VERSION ""

NS_ :

BS_:

BU_: FICM_FD Vector__XXX

BO_ 741 DTE_FuelCnsmp: 8 Vector__XXX
 SG_ RemainDrvngDist : 7|12@0+ (1,0) [0|4095] ""  FICM_FD

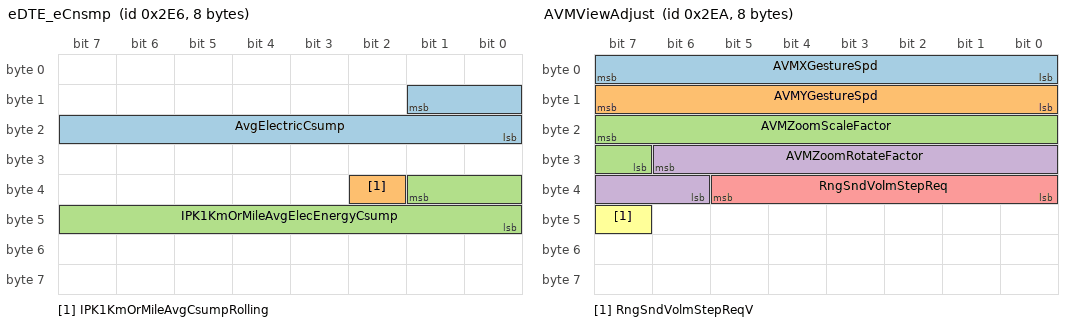
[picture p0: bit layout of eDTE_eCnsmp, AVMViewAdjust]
BO_ 742 eDTE_eCnsmp: 8 Vector__XXX
 SG_ AvgElectricCsump : 9|10@0+ (0.1,0) [0|99.9] "kWh/100km或者kWh/100mi"  FICM_FD
 SG_ IPK1KmOrMileAvgCsumpRolling : 34|1@0+ (1,0) [0|1] ""  FICM_FD
 SG_ IPK1KmOrMileAvgElecEnergyCsump : 33|10@0+ (0.1,-30) [-30|69.9] "kWh/100km或者kWh/100mi"  FICM_FD

BO_ 746 AVMViewAdjust: 8 FICM_FD
 SG_ AVMXGestureSpd : 7|8@0+ (1,0) [0|254] ""  Vector__XXX
 SG_ AVMYGestureSpd : 15|8@0+ (1,0) [0|254] ""  Vector__XXX
 SG_ AVMZoomScaleFactor : 23|9@0+ (1,0) [0|510] ""  Vector__XXX
 SG_ AVMZoomRotateFactor : 30|9@0+ (1,0) [0|510] ""  Vector__XXX
 SG_ RngSndVolmStepReq : 37|6@0+ (1,0) [0|63] ""  Vector__XXX
 SG_ RngSndVolmStepReqV : 47|1@0+ (1,0) [0|1] ""  Vector__XXX

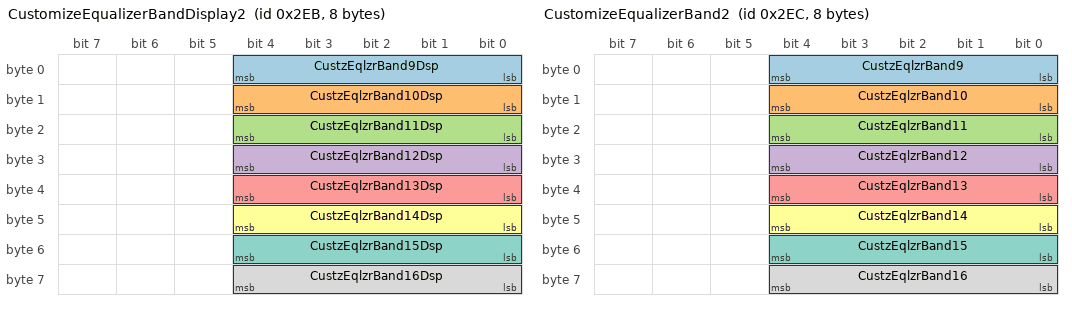
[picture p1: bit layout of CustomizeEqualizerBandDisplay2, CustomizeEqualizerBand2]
BO_ 747 CustomizeEqualizerBandDisplay2: 8 Vector__XXX
 SG_ CustzEqlzrBand9Dsp : 4|5@0+ (1,0) [0|31] ""  FICM_FD
 SG_ CustzEqlzrBand10Dsp : 12|5@0+ (1,0) [0|31] ""  FICM_FD
 SG_ CustzEqlzrBand11Dsp : 20|5@0+ (1,0) [0|31] ""  FICM_FD
 SG_ CustzEqlzrBand12Dsp : 28|5@0+ (1,0) [0|31] ""  FICM_FD
 SG_ CustzEqlzrBand13Dsp : 36|5@0+ (1,0) [0|31] ""  FICM_FD
 SG_ CustzEqlzrBand14Dsp : 44|5@0+ (1,0) [0|31] ""  FICM_FD
 SG_ CustzEqlzrBand15Dsp : 52|5@0+ (1,0) [0|31] ""  FICM_FD
 SG_ CustzEqlzrBand16Dsp : 60|5@0+ (1,0) [0|31] ""  FICM_FD

BO_ 748 CustomizeEqualizerBand2: 8 FICM_FD
 SG_ CustzEqlzrBand9 : 4|5@0+ (1,0) [0|31] "/"  Vector__XXX
 SG_ CustzEqlzrBand10 : 12|5@0+ (1,0) [0|31] "/"  Vector__XXX
 SG_ CustzEqlzrBand11 : 20|5@0+ (1,0) [0|31] "/"  Vector__XXX
 SG_ CustzEqlzrBand12 : 28|5@0+ (1,0) [0|31] "/"  Vector__XXX
 SG_ CustzEqlzrBand13 : 36|5@0+ (1,0) [0|31] "/"  Vector__XXX
 SG_ CustzEqlzrBand14 : 44|5@0+ (1,0) [0|31] "/"  Vector__XXX
 SG_ CustzEqlzrBand15 : 52|5@0+ (1,0) [0|31] "/"  Vector__XXX
 SG_ CustzEqlzrBand16 : 60|5@0+ (1,0) [0|31] "/"  Vector__XXX

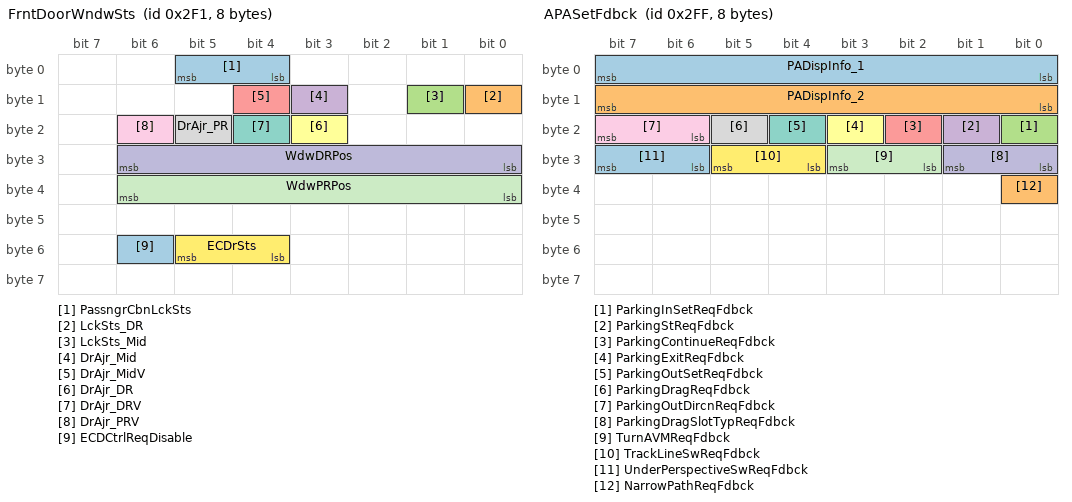
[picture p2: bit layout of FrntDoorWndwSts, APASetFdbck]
BO_ 753 FrntDoorWndwSts: 8 Vector__XXX
 SG_ PassngrCbnLckSts : 5|2@0+ (1,0) [0|3] ""  FICM_FD
 SG_ LckSts_DR : 8|1@0+ (1,0) [0|1] ""  FICM_FD
 SG_ LckSts_Mid : 9|1@0+ (1,0) [0|1] ""  FICM_FD
 SG_ DrAjr_Mid : 11|1@0+ (1,0) [0|1] ""  FICM_FD
 SG_ DrAjr_MidV : 12|1@0+ (1,0) [0|1] ""  FICM_FD
 SG_ DrAjr_DR : 19|1@0+ (1,0) [0|1] ""  FICM_FD
 SG_ DrAjr_DRV : 20|1@0+ (1,0) [0|1] ""  FICM_FD
 SG_ DrAjr_PR : 21|1@0+ (1,0) [0|1] ""  FICM_FD
 SG_ DrAjr_PRV : 22|1@0+ (1,0) [0|1] ""  FICM_FD
 SG_ WdwDRPos : 30|7@0+ (1,0) [0|127] "%"  FICM_FD
 SG_ WdwPRPos : 38|7@0+ (1,0) [0|127] "%"  FICM_FD
 SG_ ECDrSts : 53|2@0+ (1,0) [0|3] ""  FICM_FD
 SG_ ECDCtrlReqDisable : 54|1@0+ (1,0) [0|1] ""  FICM_FD

BO_ 754 RearDoorWndwSts: 8 Vector__XXX
 SG_ DrAjr_RL : 8|1@0+ (1,0) [0|1] ""  FICM_FD
 SG_ DrAjr_RLV : 9|1@0+ (1,0) [0|1] ""  FICM_FD
 SG_ DrAjr_RR : 10|1@0+ (1,0) [0|1] ""  FICM_FD
 SG_ DrAjr_RRV : 11|1@0+ (1,0) [0|1] ""  FICM_FD
 SG_ WdwRLPos : 22|7@0+ (1,0) [0|127] "%"  FICM_FD
 SG_ WdwRRPos : 30|7@0+ (1,0) [0|127] "%"  FICM_FD
 SG_ PwrPdlModuSts_RL : 36|3@0+ (1,0) [0|7] ""  FICM_FD
 SG_ PwrPdlModuSts_RR : 39|3@0+ (1,0) [0|7] ""  FICM_FD
 SG_ HVFuelSts : 41|2@0+ (1,0) [0|2] ""  FICM_FD
 SG_ Ajr_HVFulBxV : 42|1@0+ (1,0) [0|1] ""  FICM_FD
 SG_ Ajr_HVFulBx : 44|2@0+ (1,0) [0|2] ""  FICM_FD
 SG_ ChldLckSts_RR : 45|1@0+ (1,0) [0|1] ""  FICM_FD
 SG_ ChldLckSts_RL : 46|1@0+ (1,0) [0|1] ""  FICM_FD
 SG_ FuelSysEPTRdyOvrdInvsn : 54|1@0+ (1,0) [0|1] ""  FICM_FD
 SG_ FuelSysEPTRdyOvrd : 55|1@0+ (1,0) [0|1] ""  FICM_FD
 SG_ DrAjr_CRP : 57|1@0+ (1,0) [0|1] ""  FICM_FD
 SG_ DrAjr_CRPV : 58|1@0+ (1,0) [0|1] ""  FICM_FD
 SG_ ECDErrResp : 60|2@0+ (1,0) [0|3] ""  FICM_FD

BO_ 767 APASetFdbck: 8 Vector__XXX
 SG_ PADispInfo_1 : 7|8@0+ (1,0) [0|255] ""  FICM_FD
 SG_ PADispInfo_2 : 15|8@0+ (1,0) [0|255] ""  FICM_FD
 SG_ ParkingInSetReqFdbck : 16|1@0+ (1,0) [0|1] ""  FICM_FD
 SG_ ParkingStReqFdbck : 17|1@0+ (1,0) [0|1] ""  FICM_FD
 SG_ ParkingContinueReqFdbck : 18|1@0+ (1,0) [0|1] ""  FICM_FD
 SG_ ParkingExitReqFdbck : 19|1@0+ (1,0) [0|1] ""  FICM_FD
 SG_ ParkingOutSetReqFdbck : 20|1@0+ (1,0) [0|1] ""  FICM_FD
 SG_ ParkingDragReqFdbck : 21|1@0+ (1,0) [0|1] ""  FICM_FD
 SG_ ParkingOutDircnReqFdbck : 23|2@0+ (1,0) [0|3] ""  FICM_FD
 SG_ ParkingDragSlotTypReqFdbck : 25|2@0+ (1,0) [0|3] ""  FICM_FD
 SG_ TurnAVMReqFdbck : 27|2@0+ (1,0) [0|3] ""  FICM_FD
 SG_ TrackLineSwReqFdbck : 29|2@0+ (1,0) [0|3] ""  FICM_FD
 SG_ UnderPerspectiveSwReqFdbck : 31|2@0+ (1,0) [0|3] ""  FICM_FD
 SG_ NarrowPathReqFdbck : 32|1@0+ (1,0) [0|1] ""  FICM_FD

BO_ 769 TIMLmpSts: 8 Vector__XXX
 SG_ TrlerAttchSts : 0|1@0+ (1,0) [0|1] ""  FICM_FD

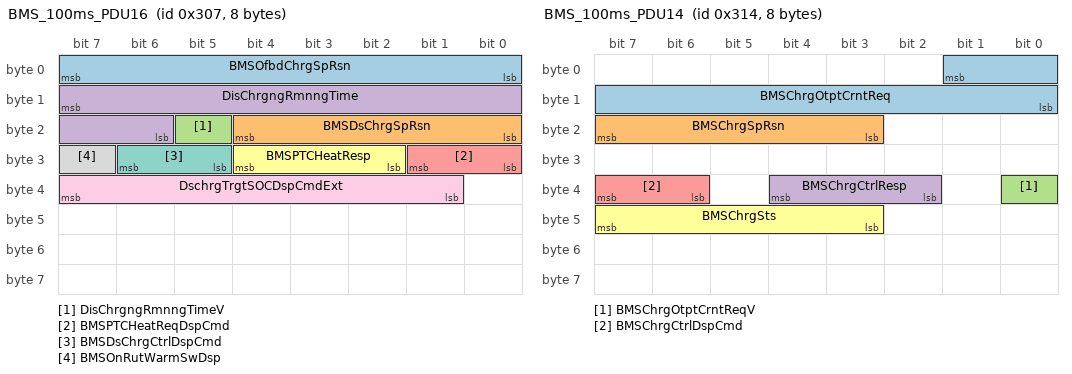
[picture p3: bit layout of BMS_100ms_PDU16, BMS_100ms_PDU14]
BO_ 775 BMS_100ms_PDU16: 8 Vector__XXX
 SG_ BMSOfbdChrgSpRsn : 7|8@0+ (1,0) [0|255] ""  FICM_FD
 SG_ BMSDsChrgSpRsn : 20|5@0+ (1,0) [0|31] ""  FICM_FD
 SG_ DisChrgngRmnngTimeV : 21|1@0+ (1,0) [0|1] ""  FICM_FD
 SG_ DisChrgngRmnngTime : 15|10@0+ (1,0) [0|1023] "min"  FICM_FD
 SG_ BMSPTCHeatReqDspCmd : 25|2@0+ (1,0) [0|3] ""  FICM_FD
 SG_ BMSPTCHeatResp : 28|3@0+ (1,0) [0|7] ""  FICM_FD
 SG_ BMSDsChrgCtrlDspCmd : 30|2@0+ (1,0) [0|3] ""  FICM_FD
 SG_ BMSOnRutWarmSwDsp : 31|1@0+ (1,0) [0|1] "NULL"  FICM_FD
 SG_ DschrgTrgtSOCDspCmdExt : 39|7@0+ (1,0) [0|100] "%"  FICM_FD

BO_ 776 AirBag_HMI: 8 Vector__XXX
 SG_ FrtPsngAirbagOnOffReqFdbck : 19|2@0+ (1,0) [0|3] ""  FICM_FD
 SG_ SBRSetReqFdbck_R : 20|1@0+ (1,0) [0|1] ""  FICM_FD

BO_ 788 BMS_100ms_PDU14: 8 Vector__XXX
 SG_ BMSChrgOtptCrntReq : 1|10@0+ (0.5,0) [0|511.5] "A"  FICM_FD
 SG_ BMSChrgSpRsn : 23|5@0+ (1,0) [0|31] "NULL"  FICM_FD
 SG_ BMSChrgOtptCrntReqV : 32|1@0+ (1,0) [0|1] "NULL"  FICM_FD
 SG_ BMSChrgCtrlResp : 36|3@0+ (1,0) [0|7] "NULL"  FICM_FD
 SG_ BMSChrgCtrlDspCmd : 39|2@0+ (1,0) [0|3] "NULL"  FICM_FD
 SG_ BMSChrgSts : 47|5@0+ (1,0) [0|31] "NULL"  FICM_FD

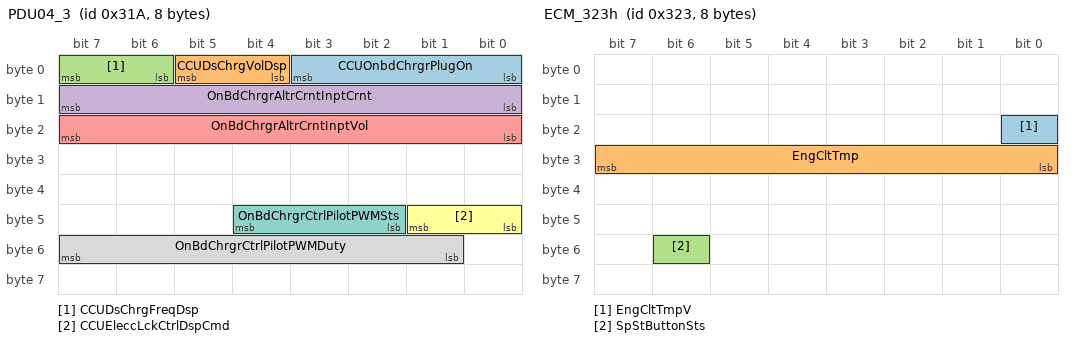
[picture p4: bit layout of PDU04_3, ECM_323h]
BO_ 794 PDU04_3: 8 Vector__XXX
 SG_ CCUOnbdChrgrPlugOn : 3|4@0+ (1,0) [0|15] "NULL"  FICM_FD
 SG_ CCUDsChrgVolDsp : 5|2@0+ (1,0) [0|3] ""  FICM_FD
 SG_ CCUDsChrgFreqDsp : 7|2@0+ (1,0) [0|3] ""  FICM_FD
 SG_ OnBdChrgrAltrCrntInptCrnt : 15|8@0+ (0.2,0) [0|51] "A"  FICM_FD
 SG_ OnBdChrgrAltrCrntInptVol : 23|8@0+ (2,0) [0|508] "V"  FICM_FD
 SG_ CCUEleccLckCtrlDspCmd : 41|2@0+ (1,0) [0|3] "NULL"  FICM_FD
 SG_ OnBdChrgrCtrlPilotPWMSts : 44|3@0+ (1,0) [0|7] ""  FICM_FD
 SG_ OnBdChrgrCtrlPilotPWMDuty : 55|7@0+ (1,0) [0|100] ""  FICM_FD

BO_ 800 SCM_DR_0x320: 8 Vector__XXX
 SG_ MemFdbk_PR : 1|2@0+ (1,0) [0|3] ""  FICM_FD
 SG_ MemClrFdbk_PR : 3|2@0+ (1,0) [0|3] ""  FICM_FD

BO_ 803 ECM_323h: 8 Vector__XXX
 SG_ EngCltTmpV : 16|1@0+ (1,0) [0|1] ""  FICM_FD
 SG_ EngCltTmp : 31|8@0+ (1,-40) [-40|215] "℃"  FICM_FD
 SG_ SpStButtonSts : 54|1@0+ (1,0) [0|1] ""  FICM_FD

BO_ 811 FOTAInfo: 8 Vector__XXX
 SG_ FOTAModReq : 1|2@0+ (1,0) [0|3] ""  FICM_FD

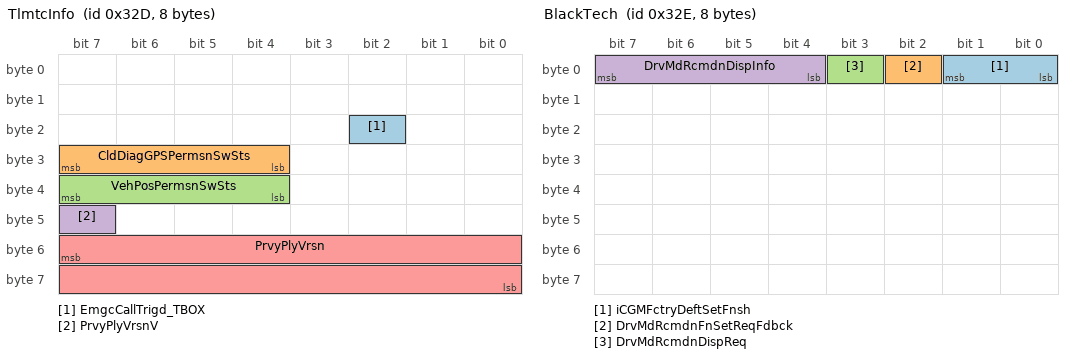
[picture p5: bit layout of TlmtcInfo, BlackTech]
BO_ 813 TlmtcInfo: 8 Vector__XXX
 SG_ EmgcCallTrigd_TBOX : 18|1@0+ (1,0) [0|1] ""  FICM_FD
 SG_ CldDiagGPSPermsnSwSts : 31|4@0+ (1,0) [0|15] ""  FICM_FD
 SG_ VehPosPermsnSwSts : 39|4@0+ (1,0) [0|15] ""  FICM_FD
 SG_ PrvyPlyVrsnV : 47|1@0+ (1,0) [0|1] ""  FICM_FD
 SG_ PrvyPlyVrsn : 55|16@0+ (1,0) [0|65535] ""  FICM_FD

BO_ 814 BlackTech: 8 Vector__XXX
 SG_ iCGMFctryDeftSetFnsh : 1|2@0+ (1,0) [0|3] ""  FICM_FD
 SG_ DrvMdRcmdnFnSetReqFdbck : 2|1@0+ (1,0) [0|1] ""  FICM_FD
 SG_ DrvMdRcmdnDispReq : 3|1@0+ (1,0) [0|1] ""  FICM_FD
 SG_ DrvMdRcmdnDispInfo : 7|4@0+ (1,0) [0|15] ""  FICM_FD

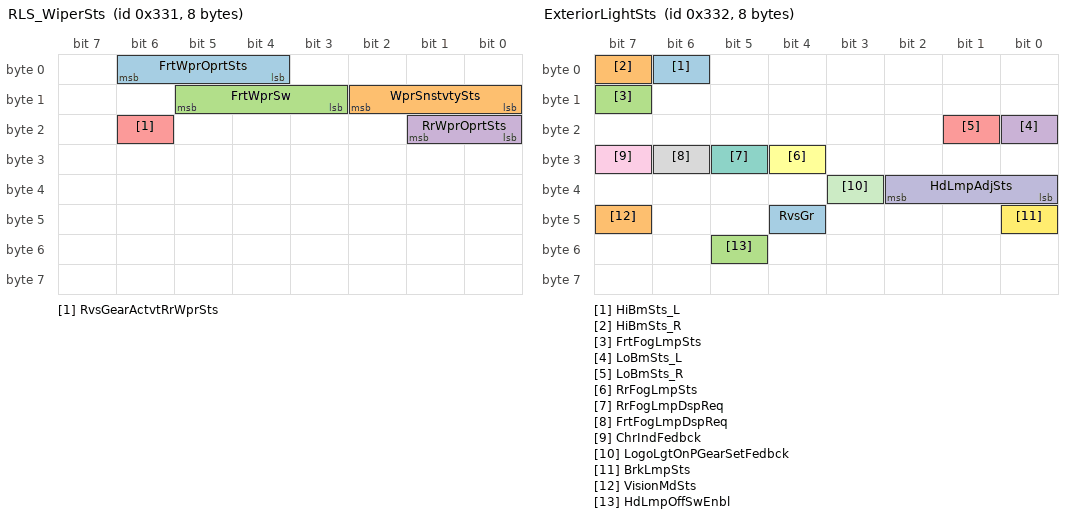
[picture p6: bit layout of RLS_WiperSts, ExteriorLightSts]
BO_ 817 RLS_WiperSts: 8 Vector__XXX
 SG_ FrtWprOprtSts : 6|3@0+ (1,0) [0|7] ""  FICM_FD
 SG_ WprSnstvtySts : 10|3@0+ (1,0) [0|4] ""  FICM_FD
 SG_ FrtWprSw : 13|3@0+ (1,0) [0|7] ""  FICM_FD
 SG_ RrWprOprtSts : 17|2@0+ (1,0) [0|3] ""  FICM_FD
 SG_ RvsGearActvtRrWprSts : 22|1@0+ (1,0) [0|1] ""  FICM_FD

BO_ 818 ExteriorLightSts: 8 Vector__XXX
 SG_ HiBmSts_L : 6|1@0+ (1,0) [0|1] ""  FICM_FD
 SG_ HiBmSts_R : 7|1@0+ (1,0) [0|1] ""  FICM_FD
 SG_ FrtFogLmpSts : 15|1@0+ (1,0) [0|1] ""  FICM_FD
 SG_ LoBmSts_L : 16|1@0+ (1,0) [0|1] ""  FICM_FD
 SG_ LoBmSts_R : 17|1@0+ (1,0) [0|1] ""  FICM_FD
 SG_ RrFogLmpSts : 28|1@0+ (1,0) [0|1] ""  FICM_FD
 SG_ RrFogLmpDspReq : 29|1@0+ (1,0) [0|1] ""  FICM_FD
 SG_ FrtFogLmpDspReq : 30|1@0+ (1,0) [0|1] ""  FICM_FD
 SG_ ChrIndFedbck : 31|1@0+ (1,0) [0|1] ""  FICM_FD
 SG_ HdLmpAdjSts : 34|3@0+ (1,0) [0|7] ""  FICM_FD
 SG_ LogoLgtOnPGearSetFedbck : 35|1@0+ (1,0) [0|1] ""  FICM_FD
 SG_ BrkLmpSts : 40|1@0+ (1,0) [0|1] ""  FICM_FD
 SG_ RvsGr : 44|1@0+ (1,0) [0|1] ""  FICM_FD
 SG_ VisionMdSts : 47|1@0+ (1,0) [0|1] ""  FICM_FD
 SG_ HdLmpOffSwEnbl : 53|1@0+ (1,0) [0|1] ""  FICM_FD

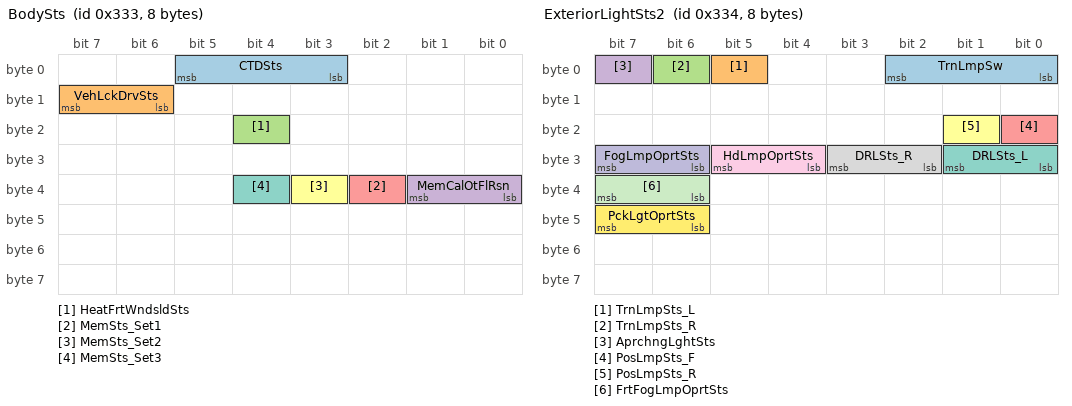
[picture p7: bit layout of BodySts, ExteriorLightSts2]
BO_ 819 BodySts: 8 Vector__XXX
 SG_ CTDSts : 5|3@0+ (1,0) [0|7] ""  FICM_FD
 SG_ VehLckDrvSts : 15|2@0+ (1,0) [0|3] ""  FICM_FD
 SG_ HeatFrtWndsldSts : 20|1@0+ (1,0) [0|1] ""  FICM_FD
 SG_ MemCalOtFlRsn : 33|2@0+ (1,0) [0|3] ""  FICM_FD
 SG_ MemSts_Set1 : 34|1@0+ (1,0) [0|1] ""  FICM_FD
 SG_ MemSts_Set2 : 35|1@0+ (1,0) [0|1] ""  FICM_FD
 SG_ MemSts_Set3 : 36|1@0+ (1,0) [0|1] ""  FICM_FD

BO_ 820 ExteriorLightSts2: 8 Vector__XXX
 SG_ TrnLmpSw : 2|3@0+ (1,0) [0|4] ""  FICM_FD
 SG_ TrnLmpSts_L : 5|1@0+ (1,0) [0|1] ""  FICM_FD
 SG_ TrnLmpSts_R : 6|1@0+ (1,0) [0|1] ""  FICM_FD
 SG_ AprchngLghtSts : 7|1@0+ (1,0) [0|1] ""  FICM_FD
 SG_ PosLmpSts_F : 16|1@0+ (1,0) [0|1] ""  FICM_FD
 SG_ PosLmpSts_R : 17|1@0+ (1,0) [0|1] ""  FICM_FD
 SG_ DRLSts_L : 25|2@0+ (1,0) [0|3] ""  FICM_FD
 SG_ DRLSts_R : 27|2@0+ (1,0) [0|3] ""  FICM_FD
 SG_ HdLmpOprtSts : 29|2@0+ (1,0) [0|3] ""  FICM_FD
 SG_ FogLmpOprtSts : 31|2@0+ (1,0) [0|3] ""  FICM_FD
 SG_ FrtFogLmpOprtSts : 39|2@0+ (1,0) [0|3] ""  FICM_FD
 SG_ PckLgtOprtSts : 47|2@0+ (1,0) [0|3] ""  FICM_FD

BO_ 823 RLSSts: 8 Vector__XXX
 SG_ Humidity : 47|8@0+ (0.5,0) [0|100] "%"  FICM_FD

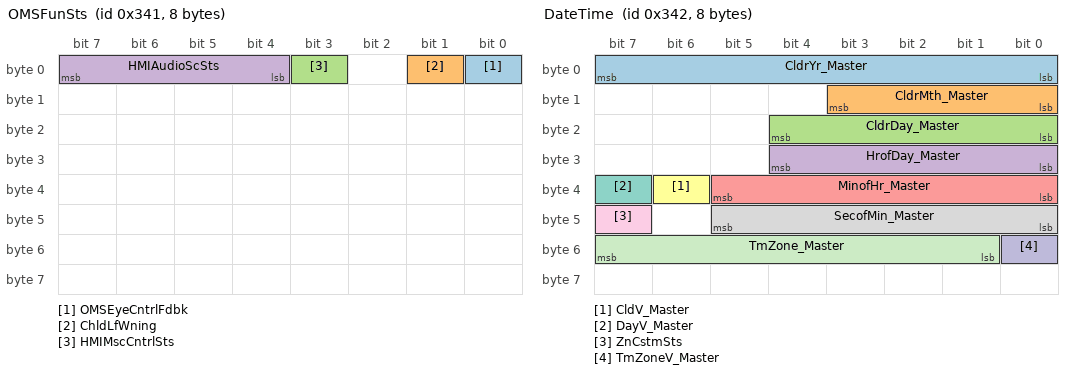
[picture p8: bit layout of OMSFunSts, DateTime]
BO_ 833 OMSFunSts: 8 FICM_FD
 SG_ OMSEyeCntrlFdbk : 0|1@0+ (1,0) [0|1] ""  Vector__XXX
 SG_ ChldLfWning : 1|1@0+ (1,0) [0|1] ""  Vector__XXX
 SG_ HMIMscCntrlSts : 3|1@0+ (1,0) [0|1] ""  Vector__XXX
 SG_ HMIAudioScSts : 7|4@0+ (1,0) [0|15] ""  Vector__XXX

BO_ 834 DateTime: 8 Vector__XXX
 SG_ CldrYr_Master : 7|8@0+ (1,2000) [2000|2255] ""  FICM_FD
 SG_ CldrMth_Master : 11|4@0+ (1,0) [0|12] ""  FICM_FD
 SG_ CldrDay_Master : 20|5@0+ (1,0) [0|31] ""  FICM_FD
 SG_ HrofDay_Master : 28|5@0+ (1,0) [0|23] ""  FICM_FD
 SG_ MinofHr_Master : 37|6@0+ (1,0) [0|63] ""  FICM_FD
 SG_ CldV_Master : 38|1@0+ (1,0) [0|1] ""  FICM_FD
 SG_ DayV_Master : 39|1@0+ (1,0) [0|1] ""  FICM_FD
 SG_ SecofMin_Master : 45|6@0+ (1,0) [0|63] ""  FICM_FD
 SG_ ZnCstmSts : 47|1@0+ (1,0) [0|1] ""  FICM_FD
 SG_ TmZoneV_Master : 48|1@0+ (1,0) [0|1] ""  FICM_FD
 SG_ TmZone_Master : 55|7@0+ (1,0) [0|127] ""  FICM_FD

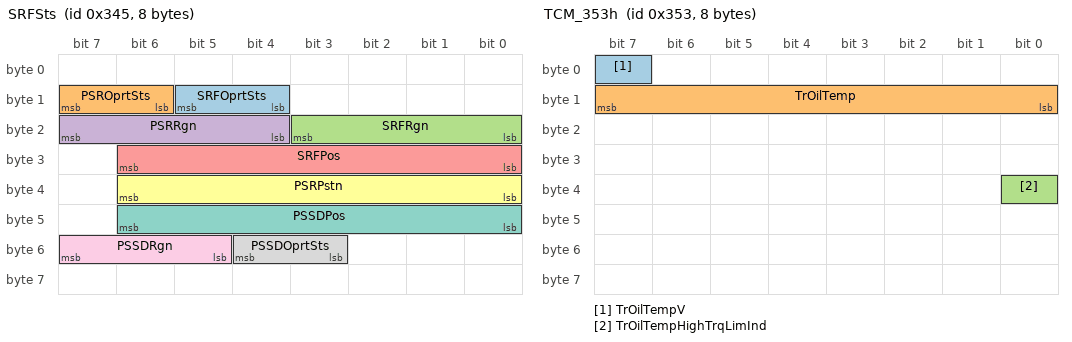
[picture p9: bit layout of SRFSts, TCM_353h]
BO_ 837 SRFSts: 8 Vector__XXX
 SG_ SRFOprtSts : 13|2@0+ (1,0) [0|3] ""  FICM_FD
 SG_ PSROprtSts : 15|2@0+ (1,0) [0|3] ""  FICM_FD
 SG_ SRFRgn : 19|4@0+ (1,0) [0|15] ""  FICM_FD
 SG_ PSRRgn : 23|4@0+ (1,0) [0|15] ""  FICM_FD
 SG_ SRFPos : 30|7@0+ (1,0) [0|127] "%"  FICM_FD
 SG_ PSRPstn : 38|7@0+ (1,0) [0|127] "%"  FICM_FD
 SG_ PSSDPos : 46|7@0+ (1,0) [0|127] "%"  FICM_FD
 SG_ PSSDOprtSts : 52|2@0+ (1,0) [0|3] ""  FICM_FD
 SG_ PSSDRgn : 55|3@0+ (1,0) [0|7] ""  FICM_FD

BO_ 838 AVAS_346h: 8 Vector__XXX
 SG_ VehSoundGenerateFeedback : 3|4@0+ (1,0) [0|7] ""  FICM_FD
 SG_ AVASSts : 4|1@0+ (1,0) [0|1] ""  FICM_FD

BO_ 846 InteriorLightSts: 8 Vector__XXX
 SG_ IntLgtOprtMd : 1|2@0+ (1,0) [0|3] ""  FICM_FD
 SG_ IntWlcmLampSetFedbck : 3|1@0+ (1,0) [0|1] ""  FICM_FD
 SG_ RfLmp5Stts : 4|1@0+ (1,0) [0|1] ""  FICM_FD
 SG_ RfLmp6Stts : 5|1@0+ (1,0) [0|1] ""  FICM_FD
 SG_ ALCRunMdSts : 7|2@0+ (1,0) [0|3] ""  FICM_FD
 SG_ BkltLumTrgt : 20|5@0+ (5,0) [0|100] "%"  FICM_FD
 SG_ BkltLum : 30|7@0+ (1,0) [0|100] "%"  FICM_FD
 SG_ BkltSts : 31|1@0+ (1,0) [0|1] ""  FICM_FD
 SG_ RfLmp1Stts : 36|1@0+ (1,0) [0|1] ""  FICM_FD
 SG_ RfLmp2Stts : 37|1@0+ (1,0) [0|1] ""  FICM_FD
 SG_ RfLmp3Stts : 38|1@0+ (1,0) [0|1] ""  FICM_FD
 SG_ RfLmp4Stts : 39|1@0+ (1,0) [0|1] ""  FICM_FD
 SG_ ALCColLvlSts : 47|8@0+ (1,0) [0|255] ""  FICM_FD
 SG_ ALCLumLvlSts : 54|7@0+ (1,0) [0|127] "%"  FICM_FD
 SG_ ALCSts : 57|2@0+ (1,0) [0|3] ""  FICM_FD
 SG_ ALDrFdbkSts : 58|1@0+ (1,0) [0|1] ""  FICM_FD
 SG_ ALCallRmdSts : 59|1@0+ (1,0) [0|1] ""  FICM_FD
 SG_ ALStartFdbkSts : 60|1@0+ (1,0) [0|1] ""  FICM_FD
 SG_ ALRhythmSts : 61|1@0+ (1,0) [0|1] ""  FICM_FD

BO_ 848 SeatSysLinkage: 8 Vector__XXX
 SG_ StSysCstmSetFdbk : 0|1@0+ (1,0) [0|1] ""  FICM_FD
 SG_ StSysLnkgSts_Dwdlr_R : 2|2@0+ (1,0) [0|3] ""  FICM_FD
 SG_ StSysSftyAlrm : 3|1@0+ (1,0) [0|1] ""  FICM_FD
 SG_ StSysLnkgSts_Thrn : 5|2@0+ (1,0) [0|3] ""  FICM_FD
 SG_ StSysLnkgSts_Dwdlr_L : 7|2@0+ (1,0) [0|3] ""  FICM_FD
 SG_ StSysLnkgSts_FstCls : 9|2@0+ (1,0) [0|3] ""  FICM_FD
 SG_ StSysLnkgSts_Strg : 11|2@0+ (1,0) [0|3] ""  FICM_FD
 SG_ StSysLnkgSts_Bbs : 13|2@0+ (1,0) [0|3] ""  FICM_FD
 SG_ StSysLnkgSts_Cstm : 15|2@0+ (1,0) [0|3] ""  FICM_FD
 SG_ StSysLnkgEnbl_Thrn : 16|1@0+ (1,0) [0|1] ""  FICM_FD
 SG_ StSysLnkgEnbl_Dwdlr_L : 17|1@0+ (1,0) [0|1] ""  FICM_FD
 SG_ StSysLnkgEnbl_FstCls : 18|1@0+ (1,0) [0|1] ""  FICM_FD
 SG_ StSysLnkgEnbl_Strg : 19|1@0+ (1,0) [0|1] ""  FICM_FD
 SG_ StSysLnkgEnbl_Bbs : 20|1@0+ (1,0) [0|1] ""  FICM_FD
 SG_ StSysLnkgEnbl_Cstm : 21|1@0+ (1,0) [0|1] ""  FICM_FD
 SG_ StSysLnkgSts_Rset : 23|2@0+ (1,0) [0|3] ""  FICM_FD
 SG_ StSysLnkgOprtSts : 27|4@0+ (1,0) [0|15] ""  FICM_FD
 SG_ MemCalOtExctSts_DR : 43|2@0+ (1,0) [0|3] ""  FICM_FD
 SG_ IntltWlcmSts : 47|2@0+ (1,0) [0|3] ""  FICM_FD
 SG_ LockVehRcvrSts : 49|2@0+ (1,0) [0|3] ""  FICM_FD
 SG_ StSysLnkgEnbl_Dwdlr_R : 55|1@0+ (1,0) [0|1] ""  FICM_FD

BO_ 849 SeatMsgReq: 8 FICM_FD
 SG_ StSysLnkgReq_HMI : 39|4@0+ (1,0) [0|15] ""  Vector__XXX
 SG_ StSysCstmReq_HMI : 42|3@0+ (1,0) [0|7] ""  Vector__XXX

BO_ 851 TCM_353h: 8 Vector__XXX
 SG_ TrOilTempV : 7|1@0+ (1,0) [0|1] ""  FICM_FD
 SG_ TrOilTemp : 15|8@0+ (1,-40) [-40|214] "℃"  FICM_FD
 SG_ TrOilTempHighTrqLimInd : 32|1@0+ (1,0) [0|1] ""  FICM_FD

BO_ 863 RearMrrAdjust: 8 Vector__XXX
 SG_ MrrFldSts : 15|2@0+ (1,0) [0|2] ""  FICM_FD

BO_ 864 ECM_360h: 8 Vector__XXX
 SG_ BarPrsAbsV : 7|1@0+ (1,0) [0|1] ""  FICM_FD
 SG_ BarPrsAbs : 15|8@0+ (0.5,0) [0|127.5] "kpa"  FICM_FD

BO_ 890 AllSeatAdjust: 8 Vector__XXX
 SG_ StHtEnbl : 14|1@0+ (1,0) [0|1] ""  FICM_FD

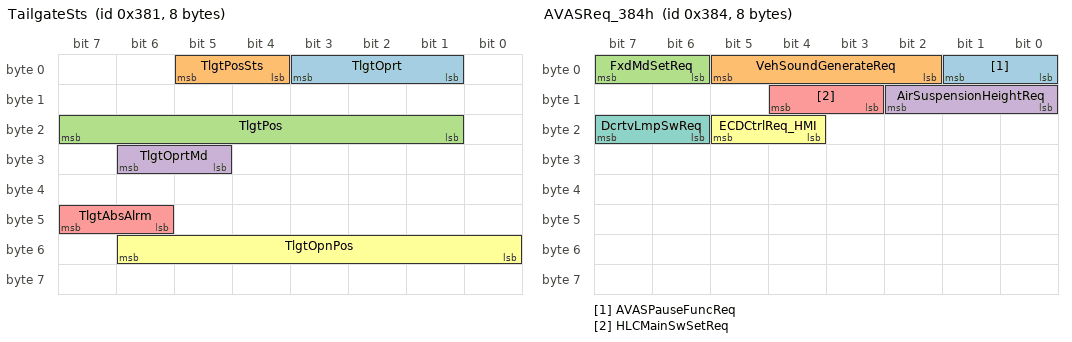
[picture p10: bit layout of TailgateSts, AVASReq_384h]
BO_ 897 TailgateSts: 8 Vector__XXX
 SG_ TlgtOprt : 3|3@0+ (1,0) [0|7] ""  FICM_FD
 SG_ TlgtPosSts : 5|2@0+ (1,0) [0|3] ""  FICM_FD
 SG_ TlgtPos : 23|7@0+ (1,0) [0|127] ""  FICM_FD
 SG_ TlgtOprtMd : 30|2@0+ (1,0) [0|3] ""  FICM_FD
 SG_ TlgtAbsAlrm : 47|2@0+ (1,0) [0|3] ""  FICM_FD
 SG_ TlgtOpnPos : 54|7@0+ (1,0) [0|100] ""  FICM_FD

BO_ 898 IBDU_SmartRequest: 8 Vector__XXX
 SG_ SmrtWlcmVcReq : 0|1@0+ (1,0) [0|1] ""  FICM_FD
 SG_ SmrtFrwllVcReq : 1|1@0+ (1,0) [0|1] ""  FICM_FD

BO_ 900 AVASReq_384h: 8 FICM_FD
 SG_ AVASPauseFuncReq : 1|2@0+ (1,0) [0|3] ""  Vector__XXX
 SG_ VehSoundGenerateReq : 5|4@0+ (1,0) [0|7] ""  Vector__XXX
 SG_ FxdMdSetReq : 7|2@0+ (1,0) [0|3] ""  Vector__XXX
 SG_ AirSuspensionHeightReq : 10|3@0+ (1,0) [0|7] ""  Vector__XXX
 SG_ HLCMainSwSetReq : 12|2@0+ (1,0) [0|3] ""  Vector__XXX
 SG_ ECDCtrlReq_HMI : 21|2@0+ (1,0) [0|3] ""  Vector__XXX
 SG_ DcrtvLmpSwReq : 23|2@0+ (1,0) [0|3] ""  Vector__XXX

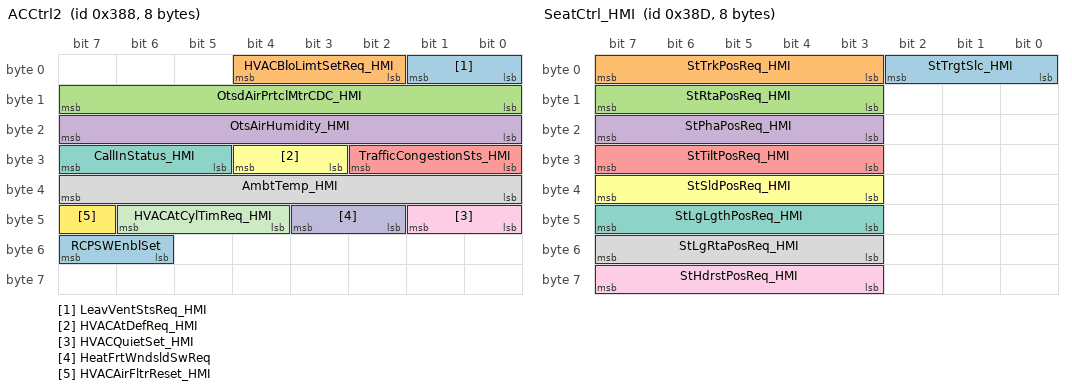
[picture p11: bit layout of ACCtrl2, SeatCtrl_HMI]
BO_ 904 ACCtrl2: 8 FICM_FD
 SG_ LeavVentStsReq_HMI : 1|2@0+ (1,0) [0|3] ""  Vector__XXX
 SG_ HVACBloLimtSetReq_HMI : 4|3@0+ (1,0) [0|7] ""  Vector__XXX
 SG_ OtsdAirPrtclMtrCDC_HMI : 15|8@0+ (2,0) [0|510] "ug/m3"  Vector__XXX
 SG_ OtsAirHumidity_HMI : 23|8@0+ (0.5,0) [0|100] "%"  Vector__XXX
 SG_ TrafficCongestionSts_HMI : 26|3@0+ (1,0) [0|7] ""  Vector__XXX
 SG_ HVACAtDefReq_HMI : 28|2@0+ (1,0) [0|3] ""  Vector__XXX
 SG_ CallInStatus_HMI : 31|3@0+ (1,0) [0|7] ""  Vector__XXX
 SG_ AmbtTemp_HMI : 39|8@0+ (0.5,-40) [-40|87.5] "deg C"  Vector__XXX
 SG_ HVACQuietSet_HMI : 41|2@0+ (1,0) [0|3] ""  Vector__XXX
 SG_ HeatFrtWndsldSwReq : 43|2@0+ (1,0) [0|3] ""  Vector__XXX
 SG_ HVACAtCylTimReq_HMI : 46|3@0+ (1,0) [0|7] ""  Vector__XXX
 SG_ HVACAirFltrReset_HMI : 47|1@0+ (1,0) [0|1] ""  Vector__XXX
 SG_ RCPSWEnblSet : 55|2@0+ (1,0) [0|3] ""  Vector__XXX

BO_ 909 SeatCtrl_HMI: 8 FICM_FD
 SG_ StTrgtSlc_HMI : 2|3@0+ (1,0) [0|7] ""  Vector__XXX
 SG_ StTrkPosReq_HMI : 7|5@0+ (1,0) [0|31] ""  Vector__XXX
 SG_ StRtaPosReq_HMI : 15|5@0+ (1,0) [0|31] ""  Vector__XXX
 SG_ StPhaPosReq_HMI : 23|5@0+ (1,0) [0|31] ""  Vector__XXX
 SG_ StTiltPosReq_HMI : 31|5@0+ (1,0) [0|31] ""  Vector__XXX
 SG_ StSldPosReq_HMI : 39|5@0+ (1,0) [0|31] ""  Vector__XXX
 SG_ StLgLgthPosReq_HMI : 47|5@0+ (1,0) [0|31] ""  Vector__XXX
 SG_ StLgRtaPosReq_HMI : 55|5@0+ (1,0) [0|31] ""  Vector__XXX
 SG_ StHdrstPosReq_HMI : 63|5@0+ (1,0) [0|31] ""  Vector__XXX

BO_ 911 OneTouchModeSts: 8 FICM_FD
 SG_ RlxMdSts_Lf : 1|2@0+ (1,0) [0|2] ""  Vector__XXX
 SG_ SlpMdSts_Lf : 3|2@0+ (1,0) [0|2] ""  Vector__XXX
 SG_ WkMdSts_Lf : 5|2@0+ (1,0) [0|2] ""  Vector__XXX
 SG_ WmMdSts_Lf : 7|2@0+ (1,0) [0|2] ""  Vector__XXX
 SG_ ClMdSts_Lf : 9|2@0+ (1,0) [0|2] ""  Vector__XXX
 SG_ SmkMdSts_Lf : 11|2@0+ (1,0) [0|2] ""  Vector__XXX
 SG_ RlxMdSts_Rt : 17|2@0+ (1,0) [0|2] ""  Vector__XXX
 SG_ SlpMdSts_Rt : 19|2@0+ (1,0) [0|2] ""  Vector__XXX
 SG_ WkMdSts_Rt : 21|2@0+ (1,0) [0|2] ""  Vector__XXX
 SG_ WmMdSts_Rt : 23|2@0+ (1,0) [0|2] ""  Vector__XXX
 SG_ ClMdSts_Rt : 25|2@0+ (1,0) [0|2] ""  Vector__XXX
 SG_ SmkMdSts_Rt : 27|2@0+ (1,0) [0|2] ""  Vector__XXX
 SG_ StBOSSVIPSts_L : 29|2@0+ (1,0) [0|2] ""  Vector__XXX
 SG_ StBOSSVIPSts_R : 31|2@0+ (1,0) [0|2] ""  Vector__XXX
 SG_ OMSCntrlObjt_L : 35|4@0+ (1,0) [0|15] ""  Vector__XXX
 SG_ OMSCntrlObjt_R : 39|4@0+ (1,0) [0|15] ""  Vector__XXX
 SG_ ClMdSts : 40|1@0+ (1,0) [0|1] ""  Vector__XXX
 SG_ WmMdSts : 41|1@0+ (1,0) [0|1] ""  Vector__XXX
 SG_ CmfrtMdSts : 42|1@0+ (1,0) [0|1] ""  Vector__XXX
 SG_ RlxMdSts : 43|1@0+ (1,0) [0|1] ""  Vector__XXX
 SG_ ZenMdSts : 44|1@0+ (1,0) [0|1] ""  Vector__XXX
 SG_ MtngMdSts : 45|1@0+ (1,0) [0|1] ""  Vector__XXX
 SG_ StdMdSts : 46|1@0+ (1,0) [0|1] ""  Vector__XXX

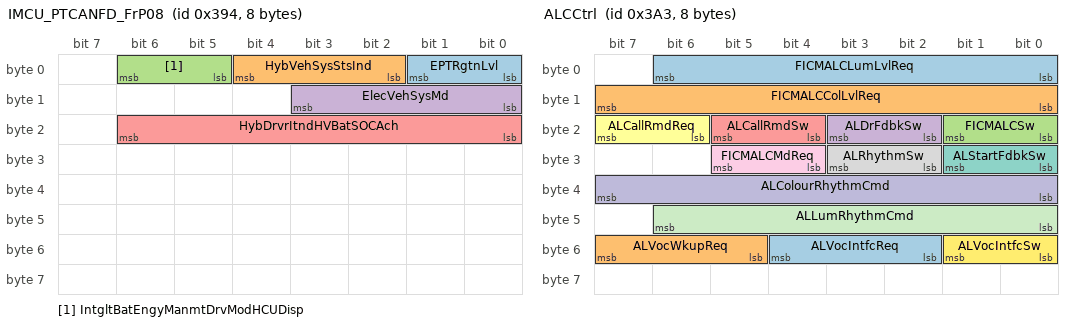
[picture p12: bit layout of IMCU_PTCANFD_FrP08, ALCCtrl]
BO_ 916 IMCU_PTCANFD_FrP08: 8 Vector__XXX
 SG_ EPTRgtnLvl : 1|2@0+ (1,0) [0|3] ""  FICM_FD
 SG_ HybVehSysStsInd : 4|3@0+ (1,0) [0|7] ""  FICM_FD
 SG_ IntgltBatEngyManmtDrvModHCUDisp : 6|2@0+ (1,0) [0|3] ""  FICM_FD
 SG_ ElecVehSysMd : 11|4@0+ (1,0) [0|15] ""  FICM_FD
 SG_ HybDrvrItndHVBatSOCAch : 22|7@0+ (1,0) [0|100] "%"  FICM_FD

BO_ 928 DASSetting: 8 FICM_FD
 SG_ FCM_AEBMainSwReq : 1|2@0+ (1,0) [0|3] ""  Vector__XXX
 SG_ LDWReminderReq : 3|2@0+ (1,0) [0|3] ""  Vector__XXX
 SG_ LDWAccuracyReq : 5|2@0+ (1,0) [0|3] ""  Vector__XXX
 SG_ LKA_LDW_ELKMainSwReq : 7|2@0+ (1,0) [0|3] ""  Vector__XXX
 SG_ SLIF_ISAMainSwReq : 9|2@0+ (1,0) [0|3] ""  Vector__XXX
 SG_ FCMMainSensitivityReq : 11|2@0+ (1,0) [0|3] ""  Vector__XXX
 SG_ ICA_ALCAMainSwReq : 13|2@0+ (1,0) [0|3] ""  Vector__XXX
 SG_ DASSoundCtrlSetReq : 15|2@0+ (1,0) [0|3] ""  Vector__XXX
 SG_ MAPMainSwReq : 17|2@0+ (1,0) [0|3] ""  Vector__XXX
 SG_ BSDMainSwReq : 19|2@0+ (1,0) [0|3] ""  Vector__XXX
 SG_ MAPRemindReq : 21|2@0+ (1,0) [0|3] ""  Vector__XXX
 SG_ AESMainSwReq : 23|2@0+ (1,0) [0|3] ""  Vector__XXX
 SG_ MAPSpdAccuracyReq : 26|3@0+ (1,0) [0|7] ""  Vector__XXX
 SG_ MAP_ICA_ACCFunctionSwReq : 27|1@0+ (1,0) [0|1] ""  Vector__XXX
 SG_ ChangeLaneConfirmToMsgBox : 29|2@0+ (1,0) [0|3] ""  Vector__XXX
 SG_ MAPChngLaneConfirmReq : 31|2@0+ (1,0) [0|3] ""  Vector__XXX
 SG_ IHCMainSwReq : 33|2@0+ (1,0) [0|3] ""  Vector__XXX
 SG_ MAPRcmndConfirmReq : 35|2@0+ (1,0) [0|3] ""  Vector__XXX
 SG_ MAPRcmndConfirmBeforeETC : 37|2@0+ (1,0) [0|3] ""  Vector__XXX
 SG_ DASDrvrSetHdwayReq : 39|2@0+ (1,0) [0|3] ""  Vector__XXX
 SG_ PASoundCtrlSetReq : 42|2@0+ (1,0) [0|3] ""  Vector__XXX
 SG_ PASoundCtrlReq : 47|5@0+ (1,0) [0|31] ""  Vector__XXX
 SG_ DASDrvrSetSpdReq : 55|8@0+ (1,0) [0|255] ""  Vector__XXX
 SG_ SoundCtrlLaneChng : 57|2@0+ (1,0) [0|3] ""  Vector__XXX
 SG_ SentryMdSensitivityReq : 61|2@0+ (1,0) [0|3] ""  Vector__XXX
 SG_ LDWSundWrnngReq : 63|2@0+ (1,0) [0|3] ""  Vector__XXX

BO_ 937 DASSetting2: 8 FICM_FD
 SG_ SLIFSundWrnngReq : 1|2@0+ (1,0) [0|3] ""  Vector__XXX
 SG_ ELKMainSwReq : 3|2@0+ (1,0) [0|3] ""  Vector__XXX
 SG_ SLIFMainSwReq : 5|2@0+ (1,0) [0|3] ""  Vector__XXX
 SG_ ISAMainSwReq : 7|2@0+ (1,0) [0|3] ""  Vector__XXX
 SG_ LKA_LDWMainSwReq : 9|2@0+ (1,0) [0|3] ""  Vector__XXX
 SG_ BSISMainSwReq : 11|2@0+ (1,0) [0|3] ""  Vector__XXX
 SG_ MOISMainSwReq : 13|2@0+ (1,0) [0|3] ""  Vector__XXX
 SG_ SpdLimitOffsetSta : 15|2@0+ (1,0) [0|3] ""  Vector__XXX
 SG_ SpdLimitOffsetValue : 19|4@0+ (1,0) [0|15] ""  Vector__XXX
 SG_ SpdLimitOffsetValuePlusMinus : 20|1@0+ (1,0) [0|1] ""  Vector__XXX
 SG_ FCMVibrationCfg : 21|1@0+ (1,0) [0|1] ""  Vector__XXX
 SG_ FCMReminderReq : 23|2@0+ (1,0) [0|3] ""  Vector__XXX
 SG_ LDWReminderTypeReq : 26|3@0+ (1,0) [0|7] ""  Vector__XXX
 SG_ LDWVibrationCfg : 27|1@0+ (1,0) [0|1] ""  Vector__XXX
 SG_ BSDLCAMainSwReq : 29|2@0+ (1,0) [0|3] ""  Vector__XXX
 SG_ RCTAMainSwReq : 31|2@0+ (1,0) [0|3] ""  Vector__XXX
 SG_ DOWMainSwReq : 35|2@0+ (1,0) [0|3] ""  Vector__XXX
 SG_ RCWMainSwReq : 37|2@0+ (1,0) [0|3] ""  Vector__XXX
 SG_ RAEBMainSwReq : 39|2@0+ (1,0) [0|3] ""  Vector__XXX

BO_ 931 ALCCtrl: 8 FICM_FD
 SG_ FICMALCLumLvlReq : 6|7@0+ (1,0) [0|127] "%"  Vector__XXX
 SG_ FICMALCColLvlReq : 15|8@0+ (1,0) [0|255] ""  Vector__XXX
 SG_ FICMALCSw : 17|2@0+ (1,0) [0|3] ""  Vector__XXX
 SG_ ALDrFdbkSw : 19|2@0+ (1,0) [0|3] ""  Vector__XXX
 SG_ ALCallRmdSw : 21|2@0+ (1,0) [0|3] ""  Vector__XXX
 SG_ ALCallRmdReq : 23|2@0+ (1,0) [0|3] ""  Vector__XXX
 SG_ ALStartFdbkSw : 25|2@0+ (1,0) [0|3] ""  Vector__XXX
 SG_ ALRhythmSw : 27|2@0+ (1,0) [0|3] ""  Vector__XXX
 SG_ FICMALCMdReq : 29|2@0+ (1,0) [0|3] ""  Vector__XXX
 SG_ ALColourRhythmCmd : 39|8@0+ (1,0) [0|255] ""  Vector__XXX
 SG_ ALLumRhythmCmd : 46|7@0+ (1,0) [0|127] "%"  Vector__XXX
 SG_ ALVocIntfcSw : 49|2@0+ (1,0) [0|3] ""  Vector__XXX
 SG_ ALVocIntfcReq : 52|3@0+ (1,0) [0|7] ""  Vector__XXX
 SG_ ALVocWkupReq : 55|3@0+ (1,0) [0|7] ""  Vector__XXX

BO_ 933 SeatAdjust_FICM: 8 FICM_FD
 SG_ StTrkAdjReq_PR : 1|2@0+ (1,0) [0|2] ""  Vector__XXX
 SG_ StRtaAdjReq_PR : 3|2@0+ (1,0) [0|2] ""  Vector__XXX
 SG_ StTrkAdjReq_RL_FICM : 5|2@0+ (1,0) [0|2] ""  Vector__XXX
 SG_ StRtaAdjReq_RL_FICM : 7|2@0+ (1,0) [0|2] ""  Vector__XXX
 SG_ StTrkAdjReq_RR_FICM : 9|2@0+ (1,0) [0|2] ""  Vector__XXX
 SG_ StRtaAdjReq_RR_FICM : 11|2@0+ (1,0) [0|2] ""  Vector__XXX
 SG_ StTrkAdjReq_3rdL_FICM : 13|2@0+ (1,0) [0|2] ""  Vector__XXX
 SG_ StTrkAdjReq_3rdR_FICM : 15|2@0+ (1,0) [0|2] ""  Vector__XXX
 SG_ StHtReq_DR : 18|3@0+ (1,0) [0|4] ""  Vector__XXX
 SG_ StHtReq_PR : 21|3@0+ (1,0) [0|4] ""  Vector__XXX
 SG_ MemReq_PR : 23|2@0+ (1,0) [0|3] ""  Vector__XXX
 SG_ StVtReq_DR : 26|3@0+ (1,0) [0|4] ""  Vector__XXX
 SG_ StVtReq_PR : 29|3@0+ (1,0) [0|4] ""  Vector__XXX
 SG_ MemCalOtReq_PR : 31|2@0+ (1,0) [0|3] ""  Vector__XXX
 SG_ MemClrReq_PR : 34|3@0+ (1,0) [0|4] ""  Vector__XXX
 SG_ StWelcomeSet_DR : 36|2@0+ (1,0) [0|2] ""  Vector__XXX
 SG_ StSysRstReq : 37|1@0+ (1,0) [0|1] ""  Vector__XXX
 SG_ MemReq_DR : 39|2@0+ (1,0) [0|3] ""  Vector__XXX
 SG_ StMsgReq_DR : 43|4@0+ (1,0) [0|15] ""  Vector__XXX
 SG_ StMsgReq_PR : 47|4@0+ (1,0) [0|15] ""  Vector__XXX
 SG_ StMsgIntstyReq_DR : 50|3@0+ (1,0) [0|4] ""  Vector__XXX
 SG_ StMsgIntstyReq_PR : 53|3@0+ (1,0) [0|4] ""  Vector__XXX
 SG_ MemCalOtReq_DR : 55|2@0+ (1,0) [0|3] ""  Vector__XXX
 SG_ MemClrReq_DR : 58|3@0+ (1,0) [0|4] ""  Vector__XXX
 SG_ StFRtaReq : 59|1@0+ (1,0) [0|1] ""  Vector__XXX
 SG_ StBRtaReq : 60|1@0+ (1,0) [0|1] ""  Vector__XXX

CM_ SG_ 741 RemainDrvngDist "IPKRemainDrivingDistance";

CM_ SG_ 742 AvgElectricCsump "IPKAverageElectricConsumption
注：不带单位传输，公制传递公制数据，英制传递英制数据";
CM_ SG_ 742 IPK1KmOrMileAvgElecEnergyCsump "公制传递公制值英制传递英制值";

CM_ SG_ 746 AVMXGestureSpd "触摸点X轴方向运动速度";
CM_ SG_ 746 AVMYGestureSpd "触摸点Y轴方向运动速度";
CM_ SG_ 746 AVMZoomScaleFactor "手势缩放系数";
CM_ SG_ 746 AVMZoomRotateFactor "手势旋转系数";
CM_ SG_ 746 RngSndVolmStepReq "电话铃声音量步长请求
Ring_Sound_Volume_Step_Request";
CM_ SG_ 746 RngSndVolmStepReqV "电话铃声音量步长请求有效性
Ring_Sound_Volume_Step_Request_Validity";

CM_ SG_ 747 CustzEqlzrBand9Dsp "自定义均衡器波段9显示
Customize_Equalizer_Band_9_Display";
CM_ SG_ 747 CustzEqlzrBand10Dsp "自定义均衡器波段10显示
Customize_Equalizer_Band_10_Display";
CM_ SG_ 747 CustzEqlzrBand11Dsp "自定义均衡器波段11显示
Customize_Equalizer_Band_11_Display";
CM_ SG_ 747 CustzEqlzrBand12Dsp "自定义均衡器波段12显示
Customize_Equalizer_Band_12_Display";
CM_ SG_ 747 CustzEqlzrBand13Dsp "自定义均衡器波段13显示
Customize_Equalizer_Band_13_Display";
CM_ SG_ 747 CustzEqlzrBand14Dsp "自定义均衡器波段14显示
Customize_Equalizer_Band_14_Display";
CM_ SG_ 747 CustzEqlzrBand15Dsp "自定义均衡器波段15显示
Customize_Equalizer_Band_15_Display";
CM_ SG_ 747 CustzEqlzrBand16Dsp "自定义均衡器波段16显示
Customize_Equalizer_Band_16_Display";

CM_ SG_ 748 CustzEqlzrBand9 "自定义均衡器波段9
Customize_Equalizer_Band_9
0-12dB，";
CM_ SG_ 748 CustzEqlzrBand10 "自定义均衡器波段10
Customize_Equalizer_Band_10
0-12dB，";
CM_ SG_ 748 CustzEqlzrBand11 "自定义均衡器波段11
Customize_Equalizer_Band_11
0是-12dB，";
CM_ SG_ 748 CustzEqlzrBand12 "自定义均衡器波段12
Customize_Equalizer_Band_12
0-12dB，";
CM_ SG_ 748 CustzEqlzrBand13 "自定义均衡器波段13
Customize_Equalizer_Band_13
0-12dB，";
CM_ SG_ 748 CustzEqlzrBand14 "自定义均衡器波段14
Customize_Equalizer_Band_14
0-12dB，";
CM_ SG_ 748 CustzEqlzrBand15 "自定义均衡器波段15
Customize_Equalizer_Band_15
0-12dB，";
CM_ SG_ 748 CustzEqlzrBand16 "自定义均衡器波段16
Customize_Equalizer_Band_16
0-12dB，";

CM_ SG_ 753 PassngrCbnLckSts "乘客舱锁状态信号";
CM_ SG_ 753 LckSts_DR "主驾门锁状态";
CM_ SG_ 753 LckSts_Mid "中门锁状态（预留）";
CM_ SG_ 753 DrAjr_Mid "中门开关状态";
CM_ SG_ 753 DrAjr_MidV "中门开关状态有效位";
CM_ SG_ 753 DrAjr_DR "主驾门开关状态";
CM_ SG_ 753 DrAjr_DRV "主驾开关状态有效位";
CM_ SG_ 753 DrAjr_PR "副驾开关状态";
CM_ SG_ 753 DrAjr_PRV "副驾开关状态有效位";
CM_ SG_ 753 WdwDRPos "车窗DR位置
physical range:0-100%
hex range:0x00-0x64";
CM_ SG_ 753 WdwPRPos "车窗PR位置
physical range:0-100%
hex range:0x00-0x64";
CM_ SG_ 753 ECDrSts "电动充电小门开关状态";
CM_ SG_ 753 ECDCtrlReqDisable "电动充电小门大屏软开关禁用请求";

CM_ SG_ 754 DrAjr_RL "左后开关状态";
CM_ SG_ 754 DrAjr_RLV "左后开关状态有效位";
CM_ SG_ 754 DrAjr_RR "右后开关状态";
CM_ SG_ 754 DrAjr_RRV "右后开关状态有效位";
CM_ SG_ 754 WdwRLPos "车窗RL位置
physical range:0-100%
hex range:0x00-0x64";
CM_ SG_ 754 WdwRRPos "车窗RR位置
physical range:0-100%
hex range:0x00-0x64";
CM_ SG_ 754 PwrPdlModuSts_RL "左后电动踏板状态";
CM_ SG_ 754 PwrPdlModuSts_RR "右后电动踏板状态";
CM_ SG_ 754 HVFuelSts "高压油箱开关状态";
CM_ SG_ 754 Ajr_HVFulBxV "高压油箱盖门状态有效性";
CM_ SG_ 754 Ajr_HVFulBx "高压油箱盖门状态";
CM_ SG_ 754 ChldLckSts_RR "右后门童锁状态";
CM_ SG_ 754 ChldLckSts_RL "左后门童锁状态";
CM_ SG_ 754 DrAjr_CRP "可开启后围开关状态";
CM_ SG_ 754 DrAjr_CRPV "可开启后围开关状态有效位";
CM_ SG_ 754 ECDErrResp "电动充电小门故障大屏提示信号";

CM_ SG_ 767 PADispInfo_1 "泊车文字提醒_1";
CM_ SG_ 767 PADispInfo_2 "泊车文字提醒_2";
CM_ SG_ 767 ParkingInSetReqFdbck "APA回复泊入界面进入状态";
CM_ SG_ 767 ParkingStReqFdbck "FICM发送泊车界面泊车开始请求反馈";
CM_ SG_ 767 ParkingContinueReqFdbck "FICM发送泊车界面泊车继续请求反馈";
CM_ SG_ 767 ParkingExitReqFdbck "FICM发送泊车界面泊车退出请求反馈";
CM_ SG_ 767 ParkingOutSetReqFdbck "APA回复泊出界面进入状态";
CM_ SG_ 767 ParkingDragReqFdbck "FICM发送泊车界面拖拽泊车请求反馈";
CM_ SG_ 767 ParkingOutDircnReqFdbck "APA回复泊出方向状态";
CM_ SG_ 767 ParkingDragSlotTypReqFdbck "APA回复拖拽车位类型";
CM_ SG_ 767 TurnAVMReqFdbck "转向触发全景请求反馈";
CM_ SG_ 767 TrackLineSwReqFdbck "轨迹线开关请求反馈";
CM_ SG_ 767 UnderPerspectiveSwReqFdbck "车底透视请求反馈";
CM_ SG_ 767 NarrowPathReqFdbck "窄路通行开关状态";

CM_ BO_ 769 "iBDU发送信号TIMTrnLmpSts_L、TIMTrnLmpSts_R【适用52&65&MILA项目】
iBDU发送信号HndlSts_FL、HndlSts_FR、HndlSts_RL、HndlSts_RR【适用52项目】，其他TIM上CAN的项目仍由TIM发送（此时iBDU不能发送）";
CM_ SG_ 769 TrlerAttchSts "拖车模式开启状态
TailerModeStatus";

CM_ SG_ 775 BMSOfbdChrgSpRsn "反馈快充停止原因";
CM_ SG_ 775 BMSDsChrgSpRsn "V2L，放电中止原因";
CM_ SG_ 775 DisChrgngRmnngTimeV "V2L，预估放电剩余时间有效位";
CM_ SG_ 775 DisChrgngRmnngTime "V2L，预估放电剩余时间";
CM_ SG_ 775 BMSPTCHeatReqDspCmd "BMS反馈PTC加热状态";
CM_ SG_ 775 BMSPTCHeatResp "预约电池包加热执行状态反馈";
CM_ SG_ 775 BMSDsChrgCtrlDspCmd "V2L功能，放电控制状态反馈";
CM_ SG_ 775 BMSOnRutWarmSwDsp "在途加热";
CM_ SG_ 775 DschrgTrgtSOCDspCmdExt "放电截止电量反馈";

CM_ SG_ 776 FrtPsngAirbagOnOffReqFdbck "Front Passange Airbag Disable Indicator";
CM_ SG_ 776 SBRSetReqFdbck_R "后排SBR反馈信号";

CM_ SG_ 788 BMSChrgOtptCrntReq "充电请求电流显示";
CM_ SG_ 788 BMSChrgSpRsn "充电停止原因显示";
CM_ SG_ 788 BMSChrgOtptCrntReqV "充电请求电流显示有效位";
CM_ SG_ 788 BMSChrgCtrlResp "充电启停";
CM_ SG_ 788 BMSChrgCtrlDspCmd "BMS输出充电状态信息";
CM_ SG_ 788 BMSChrgSts "充电状态显示";

CM_ SG_ 794 CCUOnbdChrgrPlugOn "慢充枪连接状态";
CM_ SG_ 794 CCUDsChrgVolDsp "当前显示放电电压反馈值";
CM_ SG_ 794 CCUDsChrgFreqDsp "当前显示放电频率反馈值";
CM_ SG_ 794 OnBdChrgrAltrCrntInptCrnt "交流侧充电电流";
CM_ SG_ 794 OnBdChrgrAltrCrntInptVol "交流侧充电电压";
CM_ SG_ 794 CCUEleccLckCtrlDspCmd "CCU向娱乐主机和手机发送的电子锁指令反馈";
CM_ SG_ 794 OnBdChrgrCtrlPilotPWMSts "CP状态";
CM_ SG_ 794 OnBdChrgrCtrlPilotPWMDuty "慢充CP占空比";

CM_ SG_ 800 MemFdbk_PR "副驾记忆结果反馈";
CM_ SG_ 800 MemClrFdbk_PR "副驾记忆清除结果反馈";

CM_ SG_ 803 EngCltTmpV "The validity flag shall be set to “Invalid” if any sensor failure situation has been detected currently.";
CM_ SG_ 803 EngCltTmp "It represents the temperature of the engine coolant";
CM_ SG_ 803 SpStButtonSts "GAS使用，启停功能使能";

CM_ SG_ 811 FOTAModReq "iCGM Fota请求，禁用点火功能、整车禁止DTC";

CM_ SG_ 813 CldDiagGPSPermsnSwSts "云诊断位置权限开关状态";
CM_ SG_ 813 VehPosPermsnSwSts "车辆位置开关状态";
CM_ SG_ 813 PrvyPlyVrsnV "隐私政策版本有效位";
CM_ SG_ 813 PrvyPlyVrsn "隐私政策版本";

CM_ SG_ 814 iCGMFctryDeftSetFnsh "恢复出厂设置反馈
iCGM_FactoryDefaultSettingFinished";
CM_ SG_ 814 DrvMdRcmdnFnSetReqFdbck "驾驶模式推送功能设置请求反馈
Drive Mode Recommendation Function Setting Request Feedback";
CM_ SG_ 814 DrvMdRcmdnDispReq "驾驶模式推送模式请求
Drive Mode Recommendation Display Request";
CM_ SG_ 814 DrvMdRcmdnDispInfo "驾驶模式推送信息提示（预留）
Drive Mode Recommendation Display Information";

CM_ SG_ 817 FrtWprOprtSts "前雨刮工作模式";
CM_ SG_ 817 WprSnstvtySts "前雨刮灵敏度状态";
CM_ SG_ 817 FrtWprSw "前雨刮开关状态";
CM_ SG_ 817 RrWprOprtSts "后雨刮操作状态";
CM_ SG_ 817 RvsGearActvtRrWprSts "倒档激活后雨刮功能状态";

CM_ SG_ 818 HiBmSts_L "远光灯状态_L";
CM_ SG_ 818 HiBmSts_R "远光灯状态_R";
CM_ SG_ 818 FrtFogLmpSts "前雾灯状态";
CM_ SG_ 818 LoBmSts_L "近光灯驱动状态_L";
CM_ SG_ 818 LoBmSts_R "近光灯驱动状态_R";
CM_ SG_ 818 RrFogLmpSts "后雾灯状态";
CM_ SG_ 818 RrFogLmpDspReq "后雾灯仪表指示灯请求";
CM_ SG_ 818 FrtFogLmpDspReq "前雾灯仪表指示灯请求";
CM_ SG_ 818 HdLmpAdjSts "大灯调节高度";
CM_ SG_ 818 BrkLmpSts "制动灯状态";
CM_ SG_ 818 RvsGr "实际倒档状态";
CM_ SG_ 818 VisionMdSts "Vision模式状态";
CM_ SG_ 818 HdLmpOffSwEnbl "大灯开关关闭按键使能";

CM_ SG_ 819 CTDSts "设防状态信号";
CM_ SG_ 819 VehLckDrvSts "整车解闭锁驱动状态";
CM_ SG_ 819 HeatFrtWndsldSts "前风挡电加热状态";
CM_ SG_ 819 MemCalOtFlRsn "记忆位置调出失败反馈";
CM_ SG_ 819 MemSts_Set1 "记忆状态_Set1";
CM_ SG_ 819 MemSts_Set2 "记忆状态_Set2";
CM_ SG_ 819 MemSts_Set3 "记忆状态_Set3";

CM_ SG_ 820 TrnLmpSw "转向灯开关状态";
CM_ SG_ 820 TrnLmpSts_L "左转向灯驱动状态";
CM_ SG_ 820 TrnLmpSts_R "右转向灯驱动状态";
CM_ SG_ 820 AprchngLghtSts "迎宾灯功能状态";
CM_ SG_ 820 PosLmpSts_F "前位置灯状态";
CM_ SG_ 820 PosLmpSts_R "后位置灯状态";
CM_ SG_ 820 DRLSts_L "日行灯状态";
CM_ SG_ 820 FogLmpOprtSts "后雾灯开关状态";
CM_ SG_ 820 FrtFogLmpOprtSts "前雾灯开关状态";
CM_ SG_ 820 PckLgtOprtSts "货斗灯状态";

CM_ SG_ 823 Humidity "湿度";

CM_ SG_ 833 OMSEyeCntrlFdbk "OMS功能开启状态";
CM_ SG_ 833 ChldLfWning "儿童遗留触发";
CM_ SG_ 833 HMIMscCntrlSts "音乐播放/暂停状态";
CM_ SG_ 833 HMIAudioScSts "音源状态反馈";

CM_ SG_ 834 CldrYr_Master "1、Quantization:1 year
2、phys range:2000-2255
3、0: year (0x0 - 0xFF)
4、offset:2000";
CM_ SG_ 834 CldrDay_Master "1、Quantization:1 days
2、phys range:0-30
3、0: days (0x0 - 0x1F)";
CM_ SG_ 834 HrofDay_Master "1、Quantization:1 
2、phys range:0-23
3、0: (0x0 - 0x17)";
CM_ SG_ 834 MinofHr_Master "1、Quantization:1 
2、phys range:0-59
3、0: (0x0 - 0x3B)";
CM_ SG_ 834 SecofMin_Master "1、Quantization:1 
2、phys range:0-59
3、0: (0x0 - 0x3B)";

CM_ SG_ 837 SRFOprtSts "天窗电机动作状态
Sunroof Operation Status";
CM_ SG_ 837 PSROprtSts "天窗电机动作状态
Sunroof Operation Status";
CM_ SG_ 837 SRFRgn "天窗实际位置区域";
CM_ SG_ 837 SRFPos "天窗玻璃位置
physical range:0-100%
hex range:0x00-0x64";
CM_ SG_ 837 PSRPstn "全景天窗玻璃位置
physical range:0-100%
hex range:0x00-0x64";
CM_ SG_ 837 PSSDPos "全景天窗遮阳帘位置
physical range:0-100%
hex range:0x00-0x64";
CM_ SG_ 837 PSSDOprtSts "遮阳帘电机动作状态
Sunshade Operation Status";

CM_ SG_ 838 VehSoundGenerateFeedback "发声器音色反馈
VehicleSoundGenerateFeedback";
CM_ SG_ 838 AVASSts "AVASStatus
AVAS状态反馈";

CM_ SG_ 846 IntLgtOprtMd "内顶灯状态";
CM_ SG_ 846 RfLmp5Stts "三排左侧顶灯状态";
CM_ SG_ 846 RfLmp6Stts "三排右侧顶灯状态";
CM_ SG_ 846 ALCRunMdSts "氛围点亮状态";
CM_ SG_ 846 BkltLumTrgt "背光亮度调节模式状态";
CM_ SG_ 846 BkltLum "背光灯当前亮度";
CM_ SG_ 846 BkltSts "背光状态";
CM_ SG_ 846 RfLmp1Stts "一排左侧顶灯状态";
CM_ SG_ 846 RfLmp2Stts "一排右侧顶灯状态";
CM_ SG_ 846 RfLmp3Stts "二排左侧顶灯状态";
CM_ SG_ 846 RfLmp4Stts "二排右侧顶灯状态";

CM_ SG_ 848 StSysCstmSetFdbk "座椅联动自定义设置结果反馈";
CM_ SG_ 848 StSysLnkgSts_Dwdlr_R "右侧懒人模式座椅运动状态";
CM_ SG_ 848 StSysSftyAlrm "座椅系统行车安全提醒";
CM_ SG_ 848 StSysLnkgSts_Thrn "主座模式执行状态";
CM_ SG_ 848 StSysLnkgSts_Dwdlr_L "左侧懒人模式座椅运动状态";
CM_ SG_ 848 StSysLnkgSts_FstCls "头等舱模式执行状态";
CM_ SG_ 848 StSysLnkgSts_Strg "空间模式执行状态";
CM_ SG_ 848 StSysLnkgSts_Bbs "二胎模式执行状态";
CM_ SG_ 848 StSysLnkgSts_Cstm "自定义模式执行状态";
CM_ SG_ 848 StSysLnkgEnbl_Thrn "座椅一键联动王座模式使能标识位";
CM_ SG_ 848 StSysLnkgEnbl_Dwdlr_L "左侧座椅一键联动懒人模式使能标识位";
CM_ SG_ 848 StSysLnkgEnbl_FstCls "座椅一键联动头等舱模式使能标识位";
CM_ SG_ 848 StSysLnkgEnbl_Strg "座椅一键联动空间模式使能标识位";
CM_ SG_ 848 StSysLnkgEnbl_Bbs "座椅一键联动二胎模式使能标识位";
CM_ SG_ 848 StSysLnkgEnbl_Cstm "座椅一键联动自定义模式使能标识位";
CM_ SG_ 848 StSysLnkgSts_Rset "一键恢复非主驾座椅执行状态";
CM_ SG_ 848 StSysLnkgOprtSts "座椅一键联动工作状态";
CM_ SG_ 848 MemCalOtExctSts_DR "主驾座椅记忆调出执行状态反馈";
CM_ SG_ 848 IntltWlcmSts "智能迎宾座椅运动状态";
CM_ SG_ 848 LockVehRcvrSts "锁车回位座椅运动状态";
CM_ SG_ 848 StSysLnkgEnbl_Dwdlr_R "右侧座椅一键联动懒人模式使能标识位";

CM_ SG_ 849 StSysLnkgReq_HMI "前排娱乐大屏座椅一键联动请求";
CM_ SG_ 849 StSysCstmReq_HMI "前排娱乐大屏座椅联动自定义请求";

CM_ SG_ 851 TrOilTempV "Transmission Oil Temperature Validity shall be set to Invalid if the sensor providing the data has failed and a corresponding DTC has been set.When Transmission Oil Temperature Validity is set to Invalid, the Transmitter shall populate the Transmission Oil Temperature signal with a calculated default value.";
CM_ SG_ 851 TrOilTemp "Transmission Oil Temperature represents the temperature of the transmission fluid.For a conventional transmission, the Transmission Oil Temperature indicates the sump temperature and on a dry DCT the temperature measured is the temperature of the control fluid – which is not used for lubrication and does not get cooled with conventional cooling.";
CM_ SG_ 851 TrOilTempHighTrqLimInd "IPK receives the signal indicating that the transmission oil temperature is too high to limit the torque output";

CM_ SG_ 863 MrrFldSts "后视镜折叠状态";

CM_ SG_ 864 BarPrsAbsV "In the case that the sensor data cannot be obtained due to fault the validity flag must be set to “Invalid”.";
CM_ SG_ 864 BarPrsAbs "“Barometric Pressure Absolute” indicates the absolute atmospheric pressure.";

CM_ SG_ 890 StHtEnbl "座椅加热使能";

CM_ SG_ 897 TlgtPos "physical range:0-100%
hex range:0x00-0x64";
CM_ SG_ 897 TlgtOpnPos "physical range:0-100%
hex range:0x00-0x64";

CM_ SG_ 898 SmrtWlcmVcReq "iBDU智能迎宾语音请求";
CM_ SG_ 898 SmrtFrwllVcReq "iBDU智能欢送语音请求";

CM_ SG_ 900 AVASPauseFuncReq "AVAS开关";
CM_ SG_ 900 VehSoundGenerateReq "AVAS音色设置";
CM_ SG_ 900 FxdMdSetReq "维修模式设置请求";
CM_ SG_ 900 AirSuspensionHeightReq "空气悬架高度设置请求";
CM_ SG_ 900 ECDCtrlReq_HMI "电动充电小门大屏软开关操作信号";
CM_ SG_ 900 DcrtvLmpSwReq "装饰灯开关设置";

CM_ SG_ 904 HeatFrtWndsldSwReq "前风挡电加热开关请求";
CM_ SG_ 904 RCPSWEnblSet "RCP 开关使能设置";

CM_ SG_ 909 StTrgtSlc_HMI "座椅自动调节目标选择";
CM_ SG_ 909 StTrkPosReq_HMI "座椅水平目标位置";
CM_ SG_ 909 StRtaPosReq_HMI "座椅靠背目标位置";
CM_ SG_ 909 StPhaPosReq_HMI "座椅后提升目标位置";
CM_ SG_ 909 StTiltPosReq_HMI "座椅前提升目标位置";
CM_ SG_ 909 StSldPosReq_HMI "座椅侧滑目标位置
Seat Slide Position Request_iCGM";
CM_ SG_ 909 StLgLgthPosReq_HMI "座椅腿托伸展目标位置";
CM_ SG_ 909 StLgRtaPosReq_HMI "座椅腿托角度目标位置";
CM_ SG_ 909 StHdrstPosReq_HMI "座椅头枕伸展目标位置";

CM_ SG_ 911 RlxMdSts_Lf "左扶手屏一键小憩模式状态";
CM_ SG_ 911 SlpMdSts_Lf "左扶手屏一键深度放松模式状态";
CM_ SG_ 911 WkMdSts_Lf "左扶手屏一键工作模式状态";
CM_ SG_ 911 WmMdSts_Lf "左扶手屏一键温暖模式状态";
CM_ SG_ 911 ClMdSts_Lf "左扶手屏一键清凉模式状态";
CM_ SG_ 911 SmkMdSts_Lf "左扶手屏一键抽烟（通风）模式状态";
CM_ SG_ 911 RlxMdSts_Rt "右扶手屏一键小憩模式状态";
CM_ SG_ 911 SlpMdSts_Rt "右扶手屏一键深度放松模式状态";
CM_ SG_ 911 WkMdSts_Rt "右扶手屏一键工作模式状态";
CM_ SG_ 911 WmMdSts_Rt "右扶手屏一键温暖模式状态";
CM_ SG_ 911 ClMdSts_Rt "右扶手屏一键清凉模式状态";
CM_ SG_ 911 SmkMdSts_Rt "右扶手屏一键抽烟（通风）模式状态";
CM_ SG_ 911 StBOSSVIPSts_L "老板按键功能状态反馈_左";
CM_ SG_ 911 StBOSSVIPSts_R "老板按键功能状态反馈_右";
CM_ SG_ 911 OMSCntrlObjt_L "左侧扶手屏OMS识别事件";
CM_ SG_ 911 OMSCntrlObjt_R "右侧扶手屏OMS识别事件";
CM_ SG_ 911 ClMdSts "清凉模式状态";
CM_ SG_ 911 WmMdSts "温暖模式状态";
CM_ SG_ 911 CmfrtMdSts "舒畅模式状态";
CM_ SG_ 911 RlxMdSts "小憩模式状态";
CM_ SG_ 911 ZenMdSts "禅境模式状态";
CM_ SG_ 911 MtngMdSts "会议模式状态";
CM_ SG_ 911 StdMdSts "标准模式状态";

CM_ SG_ 916 ElecVehSysMd "能量流显示";
CM_ SG_ 916 HybDrvrItndHVBatSOCAch "E=N*1 %";

CM_ SG_ 928 LDWReminderReq "LDW报警方式个性化设置请求";
CM_ SG_ 928 LDWAccuracyReq "LDW报警灵敏度设置请求";
CM_ SG_ 928 FCMMainSensitivityReq "前碰撞预警灵敏度调节设置请求";
CM_ SG_ 928 BSDMainSwReq "BSD&LCA开关设置请求 , BSD、LCA、RCTA、DOW共用开关";
CM_ SG_ 928 AESMainSwReq "AES个性化设置请求";
CM_ SG_ 928 IHCMainSwReq "开启/关闭IHC个性化设置请求";
CM_ SG_ 928 DASDrvrSetHdwayReq "语音控制跟车时距增加或者减少";
CM_ SG_ 928 PASoundCtrlSetReq "APA语音控制使能开关";
CM_ SG_ 928 PASoundCtrlReq "语音控制泊车指令请求";
CM_ SG_ 928 DASDrvrSetSpdReq "语音控制车速增加或者减少";
CM_ SG_ 928 SoundCtrlLaneChng "语音控制变道";
CM_ SG_ 928 SentryMdSensitivityReq "哨兵模式灵敏度设置请求";
CM_ SG_ 928 LDWSundWrnngReq "LDW报警音关闭请求";

CM_ SG_ 937 SLIFSundWrnngReq "限速提醒报警音设置请求";
CM_ SG_ 937 SpdLimitOffsetSta "偏移速度的单位";
CM_ SG_ 937 SpdLimitOffsetValue "偏移速度范围";
CM_ SG_ 937 SpdLimitOffsetValuePlusMinus "偏移速度的正负
0x0：+ (用户设置的为0-10，发送的符号为+)
0x1：-（用户设置的为-10~-1）";
CM_ SG_ 937 FCMVibrationCfg "代表FCM振动开关配置是否露出";
CM_ SG_ 937 LDWVibrationCfg "代表LDW振动开关配置是否露出";
CM_ SG_ 937 BSDLCAMainSwReq "代表BSD和LCA单独的开关";
CM_ SG_ 937 RCTAMainSwReq "代表RCTA单独的开关";
CM_ SG_ 937 DOWMainSwReq "代表DOW单独的开关";
CM_ SG_ 937 RCWMainSwReq "代表RCW单独的开关";
CM_ SG_ 937 RAEBMainSwReq "代表RAEB单独的开关";

CM_ SG_ 931 FICMALCMdReq "氛围点亮状态请求（前娱乐大屏）";

CM_ SG_ 933 MemReq_DR "主驾座椅记忆请求";
CM_ SG_ 933 StMsgReq_DR "0x0:No Request
0x1:Mode1
0x2:Mode2
0x3:Mode3
……
0x8:Mode8
0x9~0xE:Reserved
0xF:OFF";
CM_ SG_ 933 StMsgReq_PR "0x0:No Request
0x1:Mode1
0x2:Mode2
0x3:Mode3
……
0x8:Mode8
0x9~0xE:Reserved
0xF:OFF";
CM_ SG_ 933 MemCalOtReq_DR "主驾座椅记忆调出请求";
CM_ SG_ 933 MemClrReq_DR "主驾座椅记忆清除请求";
CM_ SG_ 933 StFRtaReq "前旋转请求信号";
CM_ SG_ 933 StBRtaReq "后旋转请求信号";
BA_DEF_ SG_  "GenSigTimeoutValue" INT 0 65535;
BA_DEF_ BO_  "DiagState" ENUM  "no","yes";
BA_DEF_ BO_  "GenMsgNrOfRepetition" INT 0 65535;
BA_DEF_ BO_  "GenMsgSendType" ENUM  "Cyclic","NotUsed","NotUsed","NotUsed","NotUsed","NotUsed","NotUsed","IfActive","NoMsgSendType","NotUsed";
BA_DEF_ SG_  "SignalLongName" STRING ;
BA_DEF_ BO_  "VFrameFormat" ENUM  "StandardCAN","ExtendedCAN","reserved","J1939PG","reserved","reserved","reserved","reserved","reserved","reserved","reserved","reserved","reserved","reserved","StandardCAN_FD","ExtendedCAN_FD";
BA_DEF_ BO_  "NmMessage" ENUM  "no","yes";
BA_DEF_ BO_  "GenMsgDelayTime" INT 0 65535;
BA_DEF_ BO_  "GenMsgILSupport" ENUM  "no","yes";
BA_DEF_ BO_  "GenMsgStartDelayTime" INT 0 65535;
BA_DEF_ BO_  "NmAsrMessage" ENUM  "no","yes";
BA_DEF_ BO_  "DiagRequest" ENUM  "no","yes";
BA_DEF_ BO_  "DiagResponse" ENUM  "no","yes";
BA_DEF_ BO_  "GenMsgCycleTimeFast" INT 0 65535;
BA_DEF_ BO_  "GenMsgCycleTime" INT 0 30000;
BA_DEF_ SG_  "GenSigStartValue" INT 0 65535;
BA_DEF_ SG_  "GenSigInactiveValue" HEX 0 65535;
BA_DEF_ SG_  "GenSigSendType" ENUM  "Cyclic","OnWrite","OnWriteWithRepetition","OnChange","OnChangeWithRepetition","IfActive","IfActiveWithRepetition","NoSigSendType","OnChangeAndIfActive","OnChangeAndIfActiveWithRepetition";
BA_DEF_REL_ BU_SG_REL_  "GenSigTimeoutTime" INT 0 65535;
BA_DEF_DEF_  "GenSigTimeoutValue" 0;
BA_DEF_DEF_  "DiagState" "no";
BA_DEF_DEF_  "GenMsgNrOfRepetition" 0;
BA_DEF_DEF_  "GenMsgSendType" "NoMsgSendType";
BA_DEF_DEF_  "SignalLongName" "";
BA_DEF_DEF_  "VFrameFormat" "StandardCAN";
BA_DEF_DEF_  "NmMessage" "no";
BA_DEF_DEF_  "GenMsgDelayTime" 0;
BA_DEF_DEF_  "GenMsgILSupport" "no";
BA_DEF_DEF_  "GenMsgStartDelayTime" 0;
BA_DEF_DEF_  "NmAsrMessage" "no";
BA_DEF_DEF_  "DiagRequest" "no";
BA_DEF_DEF_  "DiagResponse" "no";
BA_DEF_DEF_  "GenMsgCycleTimeFast" 0;
BA_DEF_DEF_  "GenMsgCycleTime" 0;
BA_DEF_DEF_  "GenSigStartValue" 0;
BA_DEF_DEF_  "GenSigInactiveValue" 0;
BA_DEF_DEF_  "GenSigSendType" "NoSigSendType";
BA_DEF_DEF_REL_ "GenSigTimeoutTime" 0;

BA_ "GenMsgSendType" BO_ 741 0;
BA_ "GenMsgStartDelayTime" BO_ 741 15;
BA_ "GenMsgCycleTime" BO_ 741 100;
BA_ "GenMsgILSupport" BO_ 741 1;
BA_ "VFrameFormat" BO_ 741 14;

BA_ "GenSigSendType" SG_ 741 RemainDrvngDist 0;
BA_ "SignalLongName" SG_ 741 RemainDrvngDist "RemainDrivingDistance";

BA_ "GenMsgSendType" BO_ 742 0;
BA_ "GenMsgStartDelayTime" BO_ 742 15;
BA_ "GenMsgCycleTime" BO_ 742 100;
BA_ "GenMsgILSupport" BO_ 742 1;
BA_ "VFrameFormat" BO_ 742 14;

BA_ "GenSigSendType" SG_ 742 AvgElectricCsump 0;
BA_ "SignalLongName" SG_ 742 AvgElectricCsump "Average Electric Consumption";

BA_ "GenSigSendType" SG_ 742 IPK1KmOrMileAvgCsumpRolling 0;
BA_ "SignalLongName" SG_ 742 IPK1KmOrMileAvgCsumpRolling "IPK1KmOrMileAvgCsumpRolling";

BA_ "GenSigSendType" SG_ 742 IPK1KmOrMileAvgElecEnergyCsump 0;
BA_ "SignalLongName" SG_ 742 IPK1KmOrMileAvgElecEnergyCsump "IPK1KmOrMileAvgElecEnergyCsump";

BA_ "GenMsgSendType" BO_ 746 0;
BA_ "GenMsgStartDelayTime" BO_ 746 20;
BA_ "GenMsgCycleTime" BO_ 746 100;
BA_ "GenMsgILSupport" BO_ 746 1;
BA_ "VFrameFormat" BO_ 746 14;

BA_ "GenSigSendType" SG_ 746 AVMXGestureSpd 0;
BA_ "SignalLongName" SG_ 746 AVMXGestureSpd "AVM X Gesture Speed";

BA_ "GenSigSendType" SG_ 746 AVMYGestureSpd 0;
BA_ "SignalLongName" SG_ 746 AVMYGestureSpd "AVM Y Gesture Speed";

BA_ "GenSigSendType" SG_ 746 AVMZoomScaleFactor 0;
BA_ "SignalLongName" SG_ 746 AVMZoomScaleFactor "AVMZoomScaleFactor";

BA_ "GenSigSendType" SG_ 746 AVMZoomRotateFactor 0;
BA_ "SignalLongName" SG_ 746 AVMZoomRotateFactor "AVMZoomRotateFactor";

BA_ "GenSigSendType" SG_ 746 RngSndVolmStepReq 0;
BA_ "SignalLongName" SG_ 746 RngSndVolmStepReq "Ring_Sound_Volume_Step_Request";
BA_ "GenSigTimeoutValue" SG_ 746 RngSndVolmStepReq 16;
BA_ "GenSigStartValue" SG_ 746 RngSndVolmStepReq 16;

BA_ "GenSigSendType" SG_ 746 RngSndVolmStepReqV 0;
BA_ "SignalLongName" SG_ 746 RngSndVolmStepReqV "Ring_Sound_Volume_Step_Request_Validity";
BA_ "GenSigTimeoutValue" SG_ 746 RngSndVolmStepReqV 1;
BA_ "GenSigStartValue" SG_ 746 RngSndVolmStepReqV 1;

BA_ "GenMsgSendType" BO_ 747 0;
BA_ "GenMsgStartDelayTime" BO_ 747 30;
BA_ "GenMsgCycleTime" BO_ 747 100;
BA_ "GenMsgILSupport" BO_ 747 1;
BA_ "GenMsgDelayTime" BO_ 747 20;
BA_ "VFrameFormat" BO_ 747 14;

BA_ "GenSigSendType" SG_ 747 CustzEqlzrBand9Dsp 0;
BA_ "SignalLongName" SG_ 747 CustzEqlzrBand9Dsp "Customize_Equalizer_Band_9_Display";
BA_ "GenSigTimeoutValue" SG_ 747 CustzEqlzrBand9Dsp 12;
BA_ "GenSigStartValue" SG_ 747 CustzEqlzrBand9Dsp 12;

BA_ "GenSigSendType" SG_ 747 CustzEqlzrBand10Dsp 0;
BA_ "SignalLongName" SG_ 747 CustzEqlzrBand10Dsp "Customize_Equalizer_Band_10_Display";
BA_ "GenSigTimeoutValue" SG_ 747 CustzEqlzrBand10Dsp 12;
BA_ "GenSigStartValue" SG_ 747 CustzEqlzrBand10Dsp 12;

BA_ "GenSigSendType" SG_ 747 CustzEqlzrBand11Dsp 0;
BA_ "SignalLongName" SG_ 747 CustzEqlzrBand11Dsp "Customize_Equalizer_Band_11_Display";
BA_ "GenSigTimeoutValue" SG_ 747 CustzEqlzrBand11Dsp 12;
BA_ "GenSigStartValue" SG_ 747 CustzEqlzrBand11Dsp 12;

BA_ "GenSigSendType" SG_ 747 CustzEqlzrBand12Dsp 0;
BA_ "SignalLongName" SG_ 747 CustzEqlzrBand12Dsp "Customize_Equalizer_Band_12_Display";
BA_ "GenSigTimeoutValue" SG_ 747 CustzEqlzrBand12Dsp 12;
BA_ "GenSigStartValue" SG_ 747 CustzEqlzrBand12Dsp 12;

BA_ "GenSigSendType" SG_ 747 CustzEqlzrBand13Dsp 0;
BA_ "SignalLongName" SG_ 747 CustzEqlzrBand13Dsp "Customize_Equalizer_Band_13_Display";
BA_ "GenSigTimeoutValue" SG_ 747 CustzEqlzrBand13Dsp 12;
BA_ "GenSigStartValue" SG_ 747 CustzEqlzrBand13Dsp 12;

BA_ "GenSigSendType" SG_ 747 CustzEqlzrBand14Dsp 0;
BA_ "SignalLongName" SG_ 747 CustzEqlzrBand14Dsp "Customize_Equalizer_Band_14_Display";
BA_ "GenSigTimeoutValue" SG_ 747 CustzEqlzrBand14Dsp 12;
BA_ "GenSigStartValue" SG_ 747 CustzEqlzrBand14Dsp 12;

BA_ "GenSigSendType" SG_ 747 CustzEqlzrBand15Dsp 0;
BA_ "SignalLongName" SG_ 747 CustzEqlzrBand15Dsp "Customize_Equalizer_Band_15_Display";
BA_ "GenSigTimeoutValue" SG_ 747 CustzEqlzrBand15Dsp 12;
BA_ "GenSigStartValue" SG_ 747 CustzEqlzrBand15Dsp 12;

BA_ "GenSigSendType" SG_ 747 CustzEqlzrBand16Dsp 0;
BA_ "SignalLongName" SG_ 747 CustzEqlzrBand16Dsp "Customize_Equalizer_Band_16_Display";
BA_ "GenSigTimeoutValue" SG_ 747 CustzEqlzrBand16Dsp 12;
BA_ "GenSigStartValue" SG_ 747 CustzEqlzrBand16Dsp 12;

BA_ "GenMsgSendType" BO_ 748 0;
BA_ "GenMsgStartDelayTime" BO_ 748 30;
BA_ "GenMsgCycleTime" BO_ 748 100;
BA_ "GenMsgILSupport" BO_ 748 1;
BA_ "GenMsgDelayTime" BO_ 748 20;
BA_ "VFrameFormat" BO_ 748 14;

BA_ "GenSigSendType" SG_ 748 CustzEqlzrBand9 0;
BA_ "SignalLongName" SG_ 748 CustzEqlzrBand9 "Customize_Equalizer_Band_9";
BA_ "GenSigTimeoutValue" SG_ 748 CustzEqlzrBand9 12;
BA_ "GenSigStartValue" SG_ 748 CustzEqlzrBand9 12;

BA_ "GenSigSendType" SG_ 748 CustzEqlzrBand10 0;
BA_ "SignalLongName" SG_ 748 CustzEqlzrBand10 "Customize_Equalizer_Band_10";
BA_ "GenSigTimeoutValue" SG_ 748 CustzEqlzrBand10 12;
BA_ "GenSigStartValue" SG_ 748 CustzEqlzrBand10 12;

BA_ "GenSigSendType" SG_ 748 CustzEqlzrBand11 0;
BA_ "SignalLongName" SG_ 748 CustzEqlzrBand11 "Customize_Equalizer_Band_11";
BA_ "GenSigTimeoutValue" SG_ 748 CustzEqlzrBand11 12;
BA_ "GenSigStartValue" SG_ 748 CustzEqlzrBand11 12;

BA_ "GenSigSendType" SG_ 748 CustzEqlzrBand12 0;
BA_ "SignalLongName" SG_ 748 CustzEqlzrBand12 "Customize_Equalizer_Band_12";
BA_ "GenSigTimeoutValue" SG_ 748 CustzEqlzrBand12 12;
BA_ "GenSigStartValue" SG_ 748 CustzEqlzrBand12 12;

BA_ "GenSigSendType" SG_ 748 CustzEqlzrBand13 0;
BA_ "SignalLongName" SG_ 748 CustzEqlzrBand13 "Customize_Equalizer_Band_13";
BA_ "GenSigTimeoutValue" SG_ 748 CustzEqlzrBand13 12;
BA_ "GenSigStartValue" SG_ 748 CustzEqlzrBand13 12;

BA_ "GenSigSendType" SG_ 748 CustzEqlzrBand14 0;
BA_ "SignalLongName" SG_ 748 CustzEqlzrBand14 "Customize_Equalizer_Band_14";
BA_ "GenSigTimeoutValue" SG_ 748 CustzEqlzrBand14 12;
BA_ "GenSigStartValue" SG_ 748 CustzEqlzrBand14 12;

BA_ "GenSigSendType" SG_ 748 CustzEqlzrBand15 0;
BA_ "SignalLongName" SG_ 748 CustzEqlzrBand15 "Customize_Equalizer_Band_15";
BA_ "GenSigTimeoutValue" SG_ 748 CustzEqlzrBand15 12;
BA_ "GenSigStartValue" SG_ 748 CustzEqlzrBand15 12;

BA_ "GenSigSendType" SG_ 748 CustzEqlzrBand16 0;
BA_ "SignalLongName" SG_ 748 CustzEqlzrBand16 "Customize_Equalizer_Band_16";
BA_ "GenSigTimeoutValue" SG_ 748 CustzEqlzrBand16 12;
BA_ "GenSigStartValue" SG_ 748 CustzEqlzrBand16 12;

BA_ "GenMsgSendType" BO_ 753 0;
BA_ "GenMsgStartDelayTime" BO_ 753 30;
BA_ "GenMsgCycleTime" BO_ 753 500;
BA_ "GenMsgILSupport" BO_ 753 1;
BA_ "GenMsgCycleTimeFast" BO_ 753 40;
BA_ "GenMsgNrOfRepetition" BO_ 753 3;
BA_ "GenMsgDelayTime" BO_ 753 20;
BA_ "VFrameFormat" BO_ 753 14;

BA_ "GenSigSendType" SG_ 753 PassngrCbnLckSts 4;
BA_ "SignalLongName" SG_ 753 PassngrCbnLckSts "Passenger Cabin Lock Status";

BA_ "GenSigSendType" SG_ 753 LckSts_DR 4;
BA_ "SignalLongName" SG_ 753 LckSts_DR "Lock Status_DR";

BA_ "GenSigSendType" SG_ 753 LckSts_Mid 4;
BA_ "SignalLongName" SG_ 753 LckSts_Mid "Lock Status_Middle";

BA_ "GenSigSendType" SG_ 753 DrAjr_Mid 4;
BA_ "SignalLongName" SG_ 753 DrAjr_Mid "Door Ajar_Middle";

BA_ "GenSigSendType" SG_ 753 DrAjr_MidV 4;
BA_ "SignalLongName" SG_ 753 DrAjr_MidV "DoorAjar Middle tStatusValidity";

BA_ "GenSigSendType" SG_ 753 DrAjr_DR 4;
BA_ "SignalLongName" SG_ 753 DrAjr_DR "DoorAjarDriverStatus";

BA_ "GenSigSendType" SG_ 753 DrAjr_DRV 4;
BA_ "SignalLongName" SG_ 753 DrAjr_DRV "DoorAjarDriverStatusValidity";

BA_ "GenSigSendType" SG_ 753 DrAjr_PR 4;
BA_ "SignalLongName" SG_ 753 DrAjr_PR "Door Ajar_PR";

BA_ "GenSigSendType" SG_ 753 DrAjr_PRV 4;
BA_ "SignalLongName" SG_ 753 DrAjr_PRV "Door Ajar_PRValidity";

BA_ "GenSigSendType" SG_ 753 WdwDRPos 4;
BA_ "SignalLongName" SG_ 753 WdwDRPos "Window DR Actual Position";
BA_ "GenSigStartValue" SG_ 753 WdwDRPos 127;

BA_ "GenSigSendType" SG_ 753 WdwPRPos 4;
BA_ "SignalLongName" SG_ 753 WdwPRPos "Window PR Actual Position";
BA_ "GenSigStartValue" SG_ 753 WdwPRPos 127;

BA_ "GenSigSendType" SG_ 753 ECDrSts 4;
BA_ "SignalLongName" SG_ 753 ECDrSts "Electric Charging Door actual Status";

BA_ "GenSigSendType" SG_ 753 ECDCtrlReqDisable 4;
BA_ "SignalLongName" SG_ 753 ECDCtrlReqDisable "Electric Charging Door Control Request Disableed";

BA_ "GenMsgSendType" BO_ 754 0;
BA_ "GenMsgStartDelayTime" BO_ 754 30;
BA_ "GenMsgCycleTime" BO_ 754 500;
BA_ "GenMsgILSupport" BO_ 754 1;
BA_ "GenMsgCycleTimeFast" BO_ 754 40;
BA_ "GenMsgNrOfRepetition" BO_ 754 3;
BA_ "GenMsgDelayTime" BO_ 754 20;
BA_ "VFrameFormat" BO_ 754 14;

BA_ "GenSigSendType" SG_ 754 DrAjr_RL 4;
BA_ "SignalLongName" SG_ 754 DrAjr_RL "Door Ajar_RL";

BA_ "GenSigSendType" SG_ 754 DrAjr_RLV 4;
BA_ "SignalLongName" SG_ 754 DrAjr_RLV "DoorAjarRearLeftStatusValidity";

BA_ "GenSigSendType" SG_ 754 DrAjr_RR 4;
BA_ "SignalLongName" SG_ 754 DrAjr_RR "Door Ajar_RR";

BA_ "GenSigSendType" SG_ 754 DrAjr_RRV 4;
BA_ "SignalLongName" SG_ 754 DrAjr_RRV "DoorAjarRearRightStatusValidity";

BA_ "GenSigSendType" SG_ 754 WdwRLPos 4;
BA_ "SignalLongName" SG_ 754 WdwRLPos "Window RL Actual Position";
BA_ "GenSigStartValue" SG_ 754 WdwRLPos 127;

BA_ "GenSigSendType" SG_ 754 WdwRRPos 4;
BA_ "SignalLongName" SG_ 754 WdwRRPos "Window RR Actual Position";
BA_ "GenSigStartValue" SG_ 754 WdwRRPos 127;

BA_ "GenSigSendType" SG_ 754 PwrPdlModuSts_RL 0;
BA_ "SignalLongName" SG_ 754 PwrPdlModuSts_RL "PowerPedalModuleStatus_RL";

BA_ "GenSigSendType" SG_ 754 PwrPdlModuSts_RR 0;
BA_ "SignalLongName" SG_ 754 PwrPdlModuSts_RR "PowerPedalModuleStatus_RR";

BA_ "GenSigSendType" SG_ 754 HVFuelSts 4;
BA_ "SignalLongName" SG_ 754 HVFuelSts "High Voltage Fuel Status";

BA_ "GenSigSendType" SG_ 754 Ajr_HVFulBxV 4;
BA_ "SignalLongName" SG_ 754 Ajr_HVFulBxV "High Voltage Fuel Box Ajar Valid";

BA_ "GenSigSendType" SG_ 754 Ajr_HVFulBx 4;
BA_ "SignalLongName" SG_ 754 Ajr_HVFulBx "High Voltage Fuel Box Ajar";

BA_ "GenSigSendType" SG_ 754 ChldLckSts_RR 4;
BA_ "SignalLongName" SG_ 754 ChldLckSts_RR "Child Lock Status Rear Right";

BA_ "GenSigSendType" SG_ 754 ChldLckSts_RL 4;
BA_ "SignalLongName" SG_ 754 ChldLckSts_RL "Child Lock Status Rear Left";

BA_ "GenSigSendType" SG_ 754 FuelSysEPTRdyOvrdInvsn 4;
BA_ "SignalLongName" SG_ 754 FuelSysEPTRdyOvrdInvsn "Fuel System Electric Powertrain Ready Override Inversion";

BA_ "GenSigSendType" SG_ 754 FuelSysEPTRdyOvrd 4;
BA_ "SignalLongName" SG_ 754 FuelSysEPTRdyOvrd "Fuel System Electric Powertrain Ready Override";

BA_ "GenSigSendType" SG_ 754 DrAjr_CRP 4;
BA_ "SignalLongName" SG_ 754 DrAjr_CRP "Cabin Rear Panel Open Status";

BA_ "GenSigSendType" SG_ 754 DrAjr_CRPV 4;
BA_ "SignalLongName" SG_ 754 DrAjr_CRPV "Cabin Rear Panel Status Validity";

BA_ "GenSigSendType" SG_ 754 ECDErrResp 4;
BA_ "SignalLongName" SG_ 754 ECDErrResp "Electric Charging Door Control Error Reception";

BA_ "GenMsgSendType" BO_ 767 0;
BA_ "GenMsgStartDelayTime" BO_ 767 30;
BA_ "GenMsgCycleTime" BO_ 767 100;
BA_ "GenMsgILSupport" BO_ 767 1;
BA_ "VFrameFormat" BO_ 767 14;

BA_ "GenSigSendType" SG_ 767 PADispInfo_1 0;
BA_ "SignalLongName" SG_ 767 PADispInfo_1 "Parking Assist Display Information_1";

BA_ "GenSigSendType" SG_ 767 PADispInfo_2 0;
BA_ "SignalLongName" SG_ 767 PADispInfo_2 "Parking Assist Display Information_2";

BA_ "GenSigSendType" SG_ 767 ParkingInSetReqFdbck 0;
BA_ "SignalLongName" SG_ 767 ParkingInSetReqFdbck "Parking In Set Request Feedback";

BA_ "GenSigSendType" SG_ 767 ParkingStReqFdbck 0;
BA_ "SignalLongName" SG_ 767 ParkingStReqFdbck "Parking Start Request Feedback";

BA_ "GenSigSendType" SG_ 767 ParkingContinueReqFdbck 0;
BA_ "SignalLongName" SG_ 767 ParkingContinueReqFdbck "Parking Continue Request Feedback";

BA_ "GenSigSendType" SG_ 767 ParkingExitReqFdbck 0;
BA_ "SignalLongName" SG_ 767 ParkingExitReqFdbck "Parking Exit Request Feedback";

BA_ "GenSigSendType" SG_ 767 ParkingOutSetReqFdbck 0;
BA_ "SignalLongName" SG_ 767 ParkingOutSetReqFdbck "Parking Out Set Request Feedback";

BA_ "GenSigSendType" SG_ 767 ParkingDragReqFdbck 0;
BA_ "SignalLongName" SG_ 767 ParkingDragReqFdbck "Parking Drag Request Feedback";

BA_ "GenSigSendType" SG_ 767 ParkingOutDircnReqFdbck 0;
BA_ "SignalLongName" SG_ 767 ParkingOutDircnReqFdbck "Parking Out Direction Request Feedback";

BA_ "GenSigSendType" SG_ 767 ParkingDragSlotTypReqFdbck 0;
BA_ "SignalLongName" SG_ 767 ParkingDragSlotTypReqFdbck "Parking Drag Slot Type Request Feedback";

BA_ "GenSigSendType" SG_ 767 TurnAVMReqFdbck 0;
BA_ "SignalLongName" SG_ 767 TurnAVMReqFdbck "Turn AVM Request Feedback";

BA_ "GenSigSendType" SG_ 767 TrackLineSwReqFdbck 0;
BA_ "SignalLongName" SG_ 767 TrackLineSwReqFdbck "Track Line Switch Request Feedback";

BA_ "GenSigSendType" SG_ 767 UnderPerspectiveSwReqFdbck 0;
BA_ "SignalLongName" SG_ 767 UnderPerspectiveSwReqFdbck "Under Perspective Switch Request Feedback";

BA_ "GenSigSendType" SG_ 767 NarrowPathReqFdbck 0;
BA_ "SignalLongName" SG_ 767 NarrowPathReqFdbck "Narrow Path Request Feedback";

BA_ "GenMsgSendType" BO_ 769 0;
BA_ "GenMsgStartDelayTime" BO_ 769 20;
BA_ "GenMsgCycleTime" BO_ 769 200;
BA_ "GenMsgILSupport" BO_ 769 1;
BA_ "VFrameFormat" BO_ 769 14;

BA_ "GenSigSendType" SG_ 769 TrlerAttchSts 0;
BA_ "SignalLongName" SG_ 769 TrlerAttchSts "TrailerAttachmentStatus";

BA_ "GenMsgSendType" BO_ 775 0;
BA_ "GenMsgStartDelayTime" BO_ 775 10;
BA_ "GenMsgCycleTime" BO_ 775 100;
BA_ "GenMsgILSupport" BO_ 775 1;
BA_ "VFrameFormat" BO_ 775 14;

BA_ "GenSigSendType" SG_ 775 BMSOfbdChrgSpRsn 0;
BA_ "SignalLongName" SG_ 775 BMSOfbdChrgSpRsn "Battery Management System Offboard Charge Stop Reason";

BA_ "GenSigSendType" SG_ 775 BMSDsChrgSpRsn 0;
BA_ "SignalLongName" SG_ 775 BMSDsChrgSpRsn "Battery Management System Discharge Stop Reason";

BA_ "GenSigSendType" SG_ 775 DisChrgngRmnngTimeV 0;
BA_ "SignalLongName" SG_ 775 DisChrgngRmnngTimeV "Discharging Remaining Time Validity";
BA_ "GenSigTimeoutValue" SG_ 775 DisChrgngRmnngTimeV 1;
BA_ "GenSigStartValue" SG_ 775 DisChrgngRmnngTimeV 1;

BA_ "GenSigSendType" SG_ 775 DisChrgngRmnngTime 0;
BA_ "SignalLongName" SG_ 775 DisChrgngRmnngTime "Discharging Remaining Time";
BA_ "GenSigTimeoutValue" SG_ 775 DisChrgngRmnngTime 1023;
BA_ "GenSigStartValue" SG_ 775 DisChrgngRmnngTime 1023;

BA_ "GenSigSendType" SG_ 775 BMSPTCHeatReqDspCmd 0;
BA_ "SignalLongName" SG_ 775 BMSPTCHeatReqDspCmd "Battery Management System Positive Temperature Coefficient Heat Request Display Command";

BA_ "GenSigSendType" SG_ 775 BMSPTCHeatResp 0;
BA_ "SignalLongName" SG_ 775 BMSPTCHeatResp "Battery Management System Ptc Heat Response";

BA_ "GenSigSendType" SG_ 775 BMSDsChrgCtrlDspCmd 0;
BA_ "SignalLongName" SG_ 775 BMSDsChrgCtrlDspCmd "Battery Management System Discharge Control Display Command";

BA_ "GenSigSendType" SG_ 775 BMSOnRutWarmSwDsp 0;
BA_ "SignalLongName" SG_ 775 BMSOnRutWarmSwDsp "BMS On Route Warm Display";

BA_ "GenSigSendType" SG_ 775 DschrgTrgtSOCDspCmdExt 0;
BA_ "SignalLongName" SG_ 775 DschrgTrgtSOCDspCmdExt "DischargeTargetStateOfChargeDisplayCommand_Extend";

BA_ "GenMsgSendType" BO_ 776 0;
BA_ "GenMsgStartDelayTime" BO_ 776 10;
BA_ "GenMsgCycleTime" BO_ 776 100;
BA_ "GenMsgILSupport" BO_ 776 1;
BA_ "VFrameFormat" BO_ 776 14;

BA_ "GenSigSendType" SG_ 776 FrtPsngAirbagOnOffReqFdbck 0;
BA_ "SignalLongName" SG_ 776 FrtPsngAirbagOnOffReqFdbck "Front Passange Airbag On or Off Request Feedback";

BA_ "GenSigSendType" SG_ 776 SBRSetReqFdbck_R 0;
BA_ "SignalLongName" SG_ 776 SBRSetReqFdbck_R "Seatbelt Reminder Set Request Feedback_Rear";
BA_ "GenSigStartValue" SG_ 776 SBRSetReqFdbck_R 1;

BA_ "GenMsgSendType" BO_ 788 0;
BA_ "GenMsgStartDelayTime" BO_ 788 5;
BA_ "GenMsgCycleTime" BO_ 788 100;
BA_ "GenMsgILSupport" BO_ 788 1;
BA_ "VFrameFormat" BO_ 788 14;

BA_ "GenSigSendType" SG_ 788 BMSChrgOtptCrntReq 0;
BA_ "SignalLongName" SG_ 788 BMSChrgOtptCrntReq "Battery_Management_System_Charge_Output_Current_Request";
BA_ "GenSigTimeoutValue" SG_ 788 BMSChrgOtptCrntReq 511;
BA_ "GenSigStartValue" SG_ 788 BMSChrgOtptCrntReq 511;

BA_ "GenSigSendType" SG_ 788 BMSChrgSpRsn 0;
BA_ "SignalLongName" SG_ 788 BMSChrgSpRsn "Battery Management System Charge Stop Reason";

BA_ "GenSigSendType" SG_ 788 BMSChrgOtptCrntReqV 0;
BA_ "SignalLongName" SG_ 788 BMSChrgOtptCrntReqV "Battery_Management_System_Charge_Output_Current_Request_Validity";
BA_ "GenSigTimeoutValue" SG_ 788 BMSChrgOtptCrntReqV 1;
BA_ "GenSigStartValue" SG_ 788 BMSChrgOtptCrntReqV 1;

BA_ "GenSigSendType" SG_ 788 BMSChrgCtrlResp 0;
BA_ "SignalLongName" SG_ 788 BMSChrgCtrlResp "Battery_Management_System_Charge_Control_Response";

BA_ "GenSigSendType" SG_ 788 BMSChrgCtrlDspCmd 0;
BA_ "SignalLongName" SG_ 788 BMSChrgCtrlDspCmd "Battery_Management_System_Charge_Control_Display_Command";

BA_ "GenSigSendType" SG_ 788 BMSChrgSts 0;
BA_ "SignalLongName" SG_ 788 BMSChrgSts "Battery Management System Charge Status";

BA_ "GenMsgSendType" BO_ 794 0;
BA_ "GenMsgStartDelayTime" BO_ 794 10;
BA_ "GenMsgCycleTime" BO_ 794 100;
BA_ "GenMsgILSupport" BO_ 794 1;
BA_ "VFrameFormat" BO_ 794 14;

BA_ "GenSigSendType" SG_ 794 CCUOnbdChrgrPlugOn 0;
BA_ "SignalLongName" SG_ 794 CCUOnbdChrgrPlugOn "Combined Charging Unit On Board Charger Plug On";

BA_ "GenSigSendType" SG_ 794 CCUDsChrgVolDsp 0;
BA_ "SignalLongName" SG_ 794 CCUDsChrgVolDsp "CCU Discharge Voltage Display";

BA_ "GenSigSendType" SG_ 794 CCUDsChrgFreqDsp 0;
BA_ "SignalLongName" SG_ 794 CCUDsChrgFreqDsp "CCU Discharge Frequence Display";

BA_ "GenSigSendType" SG_ 794 OnBdChrgrAltrCrntInptCrnt 0;
BA_ "SignalLongName" SG_ 794 OnBdChrgrAltrCrntInptCrnt "On Board Charger Alternator Current Input Current";

BA_ "GenSigSendType" SG_ 794 OnBdChrgrAltrCrntInptVol 0;
BA_ "SignalLongName" SG_ 794 OnBdChrgrAltrCrntInptVol "On Board Charger Alternator Current Input Voltage";

BA_ "GenSigSendType" SG_ 794 CCUEleccLckCtrlDspCmd 0;
BA_ "SignalLongName" SG_ 794 CCUEleccLckCtrlDspCmd "Electronic Lock Control Display Command";

BA_ "GenSigSendType" SG_ 794 OnBdChrgrCtrlPilotPWMSts 0;
BA_ "SignalLongName" SG_ 794 OnBdChrgrCtrlPilotPWMSts "OnBoardChargerControlPilotPulseWidthModulationStatus";

BA_ "GenSigSendType" SG_ 794 OnBdChrgrCtrlPilotPWMDuty 0;
BA_ "SignalLongName" SG_ 794 OnBdChrgrCtrlPilotPWMDuty "On Board Charger Control Pilot Pulse Width Modulation Duty";

BA_ "GenMsgSendType" BO_ 800 0;
BA_ "GenMsgStartDelayTime" BO_ 800 20;
BA_ "GenMsgCycleTime" BO_ 800 200;
BA_ "GenMsgILSupport" BO_ 800 1;
BA_ "GenMsgCycleTimeFast" BO_ 800 40;
BA_ "GenMsgNrOfRepetition" BO_ 800 3;
BA_ "GenMsgDelayTime" BO_ 800 20;
BA_ "VFrameFormat" BO_ 800 14;

BA_ "GenSigSendType" SG_ 800 MemFdbk_PR 4;
BA_ "SignalLongName" SG_ 800 MemFdbk_PR "Seat_PR Memorizing Feedback";

BA_ "GenSigSendType" SG_ 800 MemClrFdbk_PR 4;
BA_ "SignalLongName" SG_ 800 MemClrFdbk_PR "Seat_PR Memorization Clear Feedback";

BA_ "GenMsgSendType" BO_ 803 0;
BA_ "GenMsgStartDelayTime" BO_ 803 20;
BA_ "GenMsgCycleTime" BO_ 803 200;
BA_ "GenMsgILSupport" BO_ 803 1;
BA_ "VFrameFormat" BO_ 803 14;

BA_ "GenSigSendType" SG_ 803 EngCltTmpV 0;
BA_ "SignalLongName" SG_ 803 EngCltTmpV "Engine Coolant Temperature Validity";

BA_ "GenSigSendType" SG_ 803 EngCltTmp 0;
BA_ "SignalLongName" SG_ 803 EngCltTmp "Engine Coolant Temperature";

BA_ "GenSigSendType" SG_ 803 SpStButtonSts 0;
BA_ "SignalLongName" SG_ 803 SpStButtonSts "Stop Start Button Status";

BA_ "GenMsgSendType" BO_ 811 0;
BA_ "GenMsgStartDelayTime" BO_ 811 10;
BA_ "GenMsgCycleTime" BO_ 811 100;
BA_ "GenMsgILSupport" BO_ 811 1;
BA_ "VFrameFormat" BO_ 811 14;

BA_ "GenSigSendType" SG_ 811 FOTAModReq 0;
BA_ "SignalLongName" SG_ 811 FOTAModReq "FotaModeRequest";

BA_ "GenMsgSendType" BO_ 813 0;
BA_ "GenMsgStartDelayTime" BO_ 813 10;
BA_ "GenMsgCycleTime" BO_ 813 100;
BA_ "GenMsgILSupport" BO_ 813 1;
BA_ "VFrameFormat" BO_ 813 14;

BA_ "GenSigSendType" SG_ 813 EmgcCallTrigd_TBOX 0;
BA_ "SignalLongName" SG_ 813 EmgcCallTrigd_TBOX "EmgcCallTrigd_TBOX";

BA_ "GenSigSendType" SG_ 813 CldDiagGPSPermsnSwSts 0;
BA_ "SignalLongName" SG_ 813 CldDiagGPSPermsnSwSts "CloudDiagnosisGPSPermissionSwitchStatus";

BA_ "GenSigSendType" SG_ 813 VehPosPermsnSwSts 0;
BA_ "SignalLongName" SG_ 813 VehPosPermsnSwSts "VehiclePositionPermissionSwitchStatus";

BA_ "GenSigSendType" SG_ 813 PrvyPlyVrsnV 0;
BA_ "SignalLongName" SG_ 813 PrvyPlyVrsnV "PrivacyPolicyVersionValidity
";

BA_ "GenSigSendType" SG_ 813 PrvyPlyVrsn 0;
BA_ "SignalLongName" SG_ 813 PrvyPlyVrsn "PrivacyPolicyVersion";

BA_ "GenMsgSendType" BO_ 814 0;
BA_ "GenMsgStartDelayTime" BO_ 814 10;
BA_ "GenMsgCycleTime" BO_ 814 100;
BA_ "GenMsgILSupport" BO_ 814 1;
BA_ "GenMsgCycleTimeFast" BO_ 814 40;
BA_ "GenMsgNrOfRepetition" BO_ 814 3;
BA_ "GenMsgDelayTime" BO_ 814 20;
BA_ "VFrameFormat" BO_ 814 14;

BA_ "GenSigSendType" SG_ 814 iCGMFctryDeftSetFnsh 4;
BA_ "SignalLongName" SG_ 814 iCGMFctryDeftSetFnsh "iCGM_FactoryDefaultSettingFinished";

BA_ "GenSigSendType" SG_ 814 DrvMdRcmdnFnSetReqFdbck 0;
BA_ "SignalLongName" SG_ 814 DrvMdRcmdnFnSetReqFdbck "Drive Mode Recommendation Function Setting Request FeedBack";

BA_ "GenSigSendType" SG_ 814 DrvMdRcmdnDispReq 4;
BA_ "SignalLongName" SG_ 814 DrvMdRcmdnDispReq "Drive Mode Recommendation Display Request";

BA_ "GenSigSendType" SG_ 814 DrvMdRcmdnDispInfo 0;
BA_ "SignalLongName" SG_ 814 DrvMdRcmdnDispInfo "Drive Mode Recommendation Display Request Information";

BA_ "GenMsgSendType" BO_ 817 0;
BA_ "GenMsgStartDelayTime" BO_ 817 20;
BA_ "GenMsgCycleTime" BO_ 817 200;
BA_ "GenMsgILSupport" BO_ 817 1;
BA_ "GenMsgCycleTimeFast" BO_ 817 40;
BA_ "GenMsgNrOfRepetition" BO_ 817 3;
BA_ "GenMsgDelayTime" BO_ 817 20;
BA_ "VFrameFormat" BO_ 817 14;

BA_ "GenSigSendType" SG_ 817 FrtWprOprtSts 0;
BA_ "SignalLongName" SG_ 817 FrtWprOprtSts "Front Wiper Operation Status";

BA_ "GenSigSendType" SG_ 817 WprSnstvtySts 0;
BA_ "SignalLongName" SG_ 817 WprSnstvtySts "Wiper Sensitivity Status";

BA_ "GenSigSendType" SG_ 817 FrtWprSw 4;
BA_ "SignalLongName" SG_ 817 FrtWprSw "Front Wiper Switch";

BA_ "GenSigSendType" SG_ 817 RrWprOprtSts 0;
BA_ "SignalLongName" SG_ 817 RrWprOprtSts "Rear Wiper Operation Status";

BA_ "GenSigSendType" SG_ 817 RvsGearActvtRrWprSts 0;
BA_ "SignalLongName" SG_ 817 RvsGearActvtRrWprSts "Reverse Gear Activate Wiper Status";

BA_ "GenMsgSendType" BO_ 818 0;
BA_ "GenMsgStartDelayTime" BO_ 818 20;
BA_ "GenMsgCycleTime" BO_ 818 200;
BA_ "GenMsgILSupport" BO_ 818 1;
BA_ "GenMsgCycleTimeFast" BO_ 818 40;
BA_ "GenMsgNrOfRepetition" BO_ 818 3;
BA_ "GenMsgDelayTime" BO_ 818 20;
BA_ "VFrameFormat" BO_ 818 14;

BA_ "GenSigSendType" SG_ 818 HiBmSts_L 0;
BA_ "SignalLongName" SG_ 818 HiBmSts_L "High Beam Status_Left";

BA_ "GenSigSendType" SG_ 818 HiBmSts_R 0;
BA_ "SignalLongName" SG_ 818 HiBmSts_R "High Beam Status_Right";

BA_ "GenSigSendType" SG_ 818 FrtFogLmpSts 0;
BA_ "SignalLongName" SG_ 818 FrtFogLmpSts "Front Fog Lamp Status";

BA_ "GenSigSendType" SG_ 818 LoBmSts_L 4;
BA_ "SignalLongName" SG_ 818 LoBmSts_L "Low Beam Status_Left";

BA_ "GenSigSendType" SG_ 818 LoBmSts_R 4;
BA_ "SignalLongName" SG_ 818 LoBmSts_R "Low Beam Status_Right";

BA_ "GenSigSendType" SG_ 818 RrFogLmpSts 0;
BA_ "SignalLongName" SG_ 818 RrFogLmpSts "Rear Fog Lamp Status";

BA_ "GenSigSendType" SG_ 818 RrFogLmpDspReq 4;
BA_ "SignalLongName" SG_ 818 RrFogLmpDspReq "Rear Fog Lamp Console Display Request";

BA_ "GenSigSendType" SG_ 818 FrtFogLmpDspReq 4;
BA_ "SignalLongName" SG_ 818 FrtFogLmpDspReq "Front Fog Lamp Console Display Request";

BA_ "GenSigSendType" SG_ 818 ChrIndFedbck 4;
BA_ "SignalLongName" SG_ 818 ChrIndFedbck "Charging Indicate Feedback";

BA_ "GenSigSendType" SG_ 818 HdLmpAdjSts 0;
BA_ "SignalLongName" SG_ 818 HdLmpAdjSts "Head Lamp Adjust Level Status";

BA_ "GenSigSendType" SG_ 818 LogoLgtOnPGearSetFedbck 4;
BA_ "SignalLongName" SG_ 818 LogoLgtOnPGearSetFedbck "Logo Light On Park Gear Set Feedback";

BA_ "GenSigSendType" SG_ 818 BrkLmpSts 4;
BA_ "SignalLongName" SG_ 818 BrkLmpSts "Brake Lamp Status";

BA_ "GenSigSendType" SG_ 818 RvsGr 0;
BA_ "SignalLongName" SG_ 818 RvsGr "Reverse Gear";

BA_ "GenSigSendType" SG_ 818 VisionMdSts 4;
BA_ "SignalLongName" SG_ 818 VisionMdSts "Vision Mode Status";

BA_ "GenSigSendType" SG_ 818 HdLmpOffSwEnbl 0;
BA_ "SignalLongName" SG_ 818 HdLmpOffSwEnbl "Head Lamp Off Switch Enable";

BA_ "GenMsgSendType" BO_ 819 0;
BA_ "GenMsgStartDelayTime" BO_ 819 20;
BA_ "GenMsgCycleTime" BO_ 819 200;
BA_ "GenMsgILSupport" BO_ 819 1;
BA_ "GenMsgCycleTimeFast" BO_ 819 40;
BA_ "GenMsgNrOfRepetition" BO_ 819 6;
BA_ "GenMsgDelayTime" BO_ 819 20;
BA_ "VFrameFormat" BO_ 819 14;

BA_ "GenSigSendType" SG_ 819 CTDSts 0;
BA_ "SignalLongName" SG_ 819 CTDSts "CTD Status";

BA_ "GenSigSendType" SG_ 819 VehLckDrvSts 4;
BA_ "SignalLongName" SG_ 819 VehLckDrvSts "Vehicle Lock Drive Status";

BA_ "GenSigSendType" SG_ 819 HeatFrtWndsldSts 0;
BA_ "SignalLongName" SG_ 819 HeatFrtWndsldSts "Heat Front Windshield Status";

BA_ "GenSigSendType" SG_ 819 MemCalOtFlRsn 4;
BA_ "SignalLongName" SG_ 819 MemCalOtFlRsn "Memorization Callout Failreason";

BA_ "GenSigSendType" SG_ 819 MemSts_Set1 4;
BA_ "SignalLongName" SG_ 819 MemSts_Set1 "Memorization Status Set1";

BA_ "GenSigSendType" SG_ 819 MemSts_Set2 4;
BA_ "SignalLongName" SG_ 819 MemSts_Set2 "Memorization Status Set2";

BA_ "GenSigSendType" SG_ 819 MemSts_Set3 4;
BA_ "SignalLongName" SG_ 819 MemSts_Set3 "Memorization Status Set3";

BA_ "GenMsgSendType" BO_ 820 0;
BA_ "GenMsgStartDelayTime" BO_ 820 20;
BA_ "GenMsgCycleTime" BO_ 820 200;
BA_ "GenMsgILSupport" BO_ 820 1;
BA_ "GenMsgCycleTimeFast" BO_ 820 40;
BA_ "GenMsgNrOfRepetition" BO_ 820 3;
BA_ "GenMsgDelayTime" BO_ 820 20;
BA_ "VFrameFormat" BO_ 820 14;

BA_ "GenSigSendType" SG_ 820 TrnLmpSw 0;
BA_ "SignalLongName" SG_ 820 TrnLmpSw "Turn Lamp Switch";

BA_ "GenSigSendType" SG_ 820 TrnLmpSts_L 0;
BA_ "SignalLongName" SG_ 820 TrnLmpSts_L "Turn Lamp Status_Left";

BA_ "GenSigSendType" SG_ 820 TrnLmpSts_R 0;
BA_ "SignalLongName" SG_ 820 TrnLmpSts_R "Turn Lamp Status_Right";

BA_ "GenSigSendType" SG_ 820 AprchngLghtSts 0;
BA_ "SignalLongName" SG_ 820 AprchngLghtSts "Approching Light Status";

BA_ "GenSigSendType" SG_ 820 PosLmpSts_F 0;
BA_ "SignalLongName" SG_ 820 PosLmpSts_F "Position Lamp Status Front";

BA_ "GenSigSendType" SG_ 820 PosLmpSts_R 0;
BA_ "SignalLongName" SG_ 820 PosLmpSts_R "Position Lamp Status Rear";

BA_ "GenSigSendType" SG_ 820 DRLSts_L 0;
BA_ "SignalLongName" SG_ 820 DRLSts_L "DRL Status_L";

BA_ "GenSigSendType" SG_ 820 DRLSts_R 0;
BA_ "SignalLongName" SG_ 820 DRLSts_R "DRL Status_R";

BA_ "GenSigSendType" SG_ 820 HdLmpOprtSts 4;
BA_ "SignalLongName" SG_ 820 HdLmpOprtSts "Head Lamp Operation Status";

BA_ "GenSigSendType" SG_ 820 FogLmpOprtSts 4;
BA_ "SignalLongName" SG_ 820 FogLmpOprtSts "Fog Lamp Operation Status";

BA_ "GenSigSendType" SG_ 820 FrtFogLmpOprtSts 4;
BA_ "SignalLongName" SG_ 820 FrtFogLmpOprtSts "Front Fog Lamp Operation Status";

BA_ "GenSigSendType" SG_ 820 PckLgtOprtSts 0;
BA_ "SignalLongName" SG_ 820 PckLgtOprtSts "Packing Lighting Operation Status";

BA_ "GenMsgSendType" BO_ 823 0;
BA_ "GenMsgStartDelayTime" BO_ 823 20;
BA_ "GenMsgCycleTime" BO_ 823 200;
BA_ "GenMsgILSupport" BO_ 823 1;
BA_ "VFrameFormat" BO_ 823 14;

BA_ "GenSigSendType" SG_ 823 Humidity 0;
BA_ "SignalLongName" SG_ 823 Humidity "Humidity";

BA_ "GenMsgSendType" BO_ 833 0;
BA_ "GenMsgStartDelayTime" BO_ 833 20;
BA_ "GenMsgCycleTime" BO_ 833 200;
BA_ "GenMsgILSupport" BO_ 833 1;
BA_ "VFrameFormat" BO_ 833 14;

BA_ "GenSigSendType" SG_ 833 OMSEyeCntrlFdbk 0;
BA_ "SignalLongName" SG_ 833 OMSEyeCntrlFdbk "OMSEyeControlFeedback";

BA_ "GenSigSendType" SG_ 833 ChldLfWning 0;
BA_ "SignalLongName" SG_ 833 ChldLfWning "ChildLeftWarning";

BA_ "GenSigSendType" SG_ 833 HMIMscCntrlSts 0;
BA_ "SignalLongName" SG_ 833 HMIMscCntrlSts "HMIMusicControlRequestStatus";

BA_ "GenSigSendType" SG_ 833 HMIAudioScSts 0;
BA_ "SignalLongName" SG_ 833 HMIAudioScSts "HMIAudioSourceStatus";

BA_ "GenMsgSendType" BO_ 834 0;
BA_ "GenMsgStartDelayTime" BO_ 834 10;
BA_ "GenMsgCycleTime" BO_ 834 200;
BA_ "GenMsgILSupport" BO_ 834 1;
BA_ "VFrameFormat" BO_ 834 14;

BA_ "GenSigSendType" SG_ 834 CldrYr_Master 0;
BA_ "SignalLongName" SG_ 834 CldrYr_Master "CalendarYear";

BA_ "GenSigSendType" SG_ 834 CldrMth_Master 0;
BA_ "SignalLongName" SG_ 834 CldrMth_Master "CalendarMonth";

BA_ "GenSigSendType" SG_ 834 CldrDay_Master 0;
BA_ "SignalLongName" SG_ 834 CldrDay_Master "CalendarDay";

BA_ "GenSigSendType" SG_ 834 HrofDay_Master 0;
BA_ "SignalLongName" SG_ 834 HrofDay_Master "HourOfDay";

BA_ "GenSigSendType" SG_ 834 MinofHr_Master 0;
BA_ "SignalLongName" SG_ 834 MinofHr_Master "MinuteOfHour";

BA_ "GenSigSendType" SG_ 834 CldV_Master 0;
BA_ "SignalLongName" SG_ 834 CldV_Master "iCGMCalendarValid";

BA_ "GenSigSendType" SG_ 834 DayV_Master 0;
BA_ "SignalLongName" SG_ 834 DayV_Master "iCGMDayValid";

BA_ "GenSigSendType" SG_ 834 SecofMin_Master 0;
BA_ "SignalLongName" SG_ 834 SecofMin_Master "SecsOfMinute";

BA_ "GenSigSendType" SG_ 834 ZnCstmSts 0;
BA_ "SignalLongName" SG_ 834 ZnCstmSts "ZoneCustomStatus";

BA_ "GenSigSendType" SG_ 834 TmZoneV_Master 0;
BA_ "SignalLongName" SG_ 834 TmZoneV_Master "TimeZoneValid";

BA_ "GenSigSendType" SG_ 834 TmZone_Master 0;
BA_ "SignalLongName" SG_ 834 TmZone_Master "TimeZone";

BA_ "GenMsgSendType" BO_ 837 0;
BA_ "GenMsgStartDelayTime" BO_ 837 20;
BA_ "GenMsgCycleTime" BO_ 837 200;
BA_ "GenMsgILSupport" BO_ 837 1;
BA_ "VFrameFormat" BO_ 837 14;

BA_ "GenSigSendType" SG_ 837 SRFOprtSts 0;
BA_ "SignalLongName" SG_ 837 SRFOprtSts "Sunroof Operation Status";

BA_ "GenSigSendType" SG_ 837 PSROprtSts 0;
BA_ "SignalLongName" SG_ 837 PSROprtSts "Sunroof Operation Status";

BA_ "GenSigSendType" SG_ 837 SRFRgn 0;
BA_ "SignalLongName" SG_ 837 SRFRgn "Sunroof Actual Region";

BA_ "GenSigSendType" SG_ 837 PSRRgn 0;
BA_ "SignalLongName" SG_ 837 PSRRgn "Panoramic Sunroof Actual Region";

BA_ "GenSigSendType" SG_ 837 SRFPos 0;
BA_ "SignalLongName" SG_ 837 SRFPos "Sunroof Actual Position";

BA_ "GenSigSendType" SG_ 837 PSRPstn 0;
BA_ "SignalLongName" SG_ 837 PSRPstn "PSR Position";

BA_ "GenSigSendType" SG_ 837 PSSDPos 0;
BA_ "SignalLongName" SG_ 837 PSSDPos "Panoramic Sunshade Actual Position";

BA_ "GenSigSendType" SG_ 837 PSSDOprtSts 0;
BA_ "SignalLongName" SG_ 837 PSSDOprtSts "Sunshade Operation Status";

BA_ "GenSigSendType" SG_ 837 PSSDRgn 0;
BA_ "SignalLongName" SG_ 837 PSSDRgn "Panoramic Sunshade Actual Region";

BA_ "GenMsgSendType" BO_ 838 0;
BA_ "GenMsgStartDelayTime" BO_ 838 20;
BA_ "GenMsgCycleTime" BO_ 838 200;
BA_ "GenMsgILSupport" BO_ 838 1;
BA_ "VFrameFormat" BO_ 838 14;

BA_ "GenSigSendType" SG_ 838 VehSoundGenerateFeedback 0;
BA_ "SignalLongName" SG_ 838 VehSoundGenerateFeedback "Vehicle Sound Generate Feedback";

BA_ "GenSigSendType" SG_ 838 AVASSts 0;
BA_ "SignalLongName" SG_ 838 AVASSts "AVAS Status";

BA_ "GenMsgSendType" BO_ 846 0;
BA_ "GenMsgStartDelayTime" BO_ 846 20;
BA_ "GenMsgCycleTime" BO_ 846 200;
BA_ "GenMsgILSupport" BO_ 846 1;
BA_ "GenMsgCycleTimeFast" BO_ 846 40;
BA_ "GenMsgNrOfRepetition" BO_ 846 3;
BA_ "GenMsgDelayTime" BO_ 846 20;
BA_ "VFrameFormat" BO_ 846 14;

BA_ "GenSigSendType" SG_ 846 IntLgtOprtMd 0;
BA_ "SignalLongName" SG_ 846 IntLgtOprtMd "Interior Lighting Operation Mode";

BA_ "GenSigSendType" SG_ 846 IntWlcmLampSetFedbck 4;
BA_ "SignalLongName" SG_ 846 IntWlcmLampSetFedbck "Intelligent Welcome Lamp Set Feedback";

BA_ "GenSigSendType" SG_ 846 RfLmp5Stts 0;
BA_ "SignalLongName" SG_ 846 RfLmp5Stts "Roof Lamp5 Status";
BA_ "GenSigStartValue" SG_ 846 RfLmp5Stts 1;

BA_ "GenSigSendType" SG_ 846 RfLmp6Stts 0;
BA_ "SignalLongName" SG_ 846 RfLmp6Stts "Roof Lamp6 Status";
BA_ "GenSigStartValue" SG_ 846 RfLmp6Stts 1;

BA_ "GenSigSendType" SG_ 846 ALCRunMdSts 4;
BA_ "SignalLongName" SG_ 846 ALCRunMdSts "ALC Run Mode Status";

BA_ "GenSigSendType" SG_ 846 BkltLumTrgt 0;
BA_ "SignalLongName" SG_ 846 BkltLumTrgt "Backlight Luminance Target Value";

BA_ "GenSigSendType" SG_ 846 BkltLum 0;
BA_ "SignalLongName" SG_ 846 BkltLum "Backlight Luminance";

BA_ "GenSigSendType" SG_ 846 BkltSts 0;
BA_ "SignalLongName" SG_ 846 BkltSts "Backlight Status";

BA_ "GenSigSendType" SG_ 846 RfLmp1Stts 0;
BA_ "SignalLongName" SG_ 846 RfLmp1Stts "Roof Lamp1 Status";
BA_ "GenSigStartValue" SG_ 846 RfLmp1Stts 1;

BA_ "GenSigSendType" SG_ 846 RfLmp2Stts 0;
BA_ "SignalLongName" SG_ 846 RfLmp2Stts "Roof Lamp2 Status";
BA_ "GenSigStartValue" SG_ 846 RfLmp2Stts 1;

BA_ "GenSigSendType" SG_ 846 RfLmp3Stts 0;
BA_ "SignalLongName" SG_ 846 RfLmp3Stts "Roof Lamp3 Status";
BA_ "GenSigStartValue" SG_ 846 RfLmp3Stts 1;

BA_ "GenSigSendType" SG_ 846 RfLmp4Stts 0;
BA_ "SignalLongName" SG_ 846 RfLmp4Stts "Roof Lamp4 Status";
BA_ "GenSigStartValue" SG_ 846 RfLmp4Stts 1;

BA_ "GenSigSendType" SG_ 846 ALCColLvlSts 0;
BA_ "SignalLongName" SG_ 846 ALCColLvlSts "ALC Color Level Status";
BA_ "GenSigStartValue" SG_ 846 ALCColLvlSts 22;

BA_ "GenSigSendType" SG_ 846 ALCLumLvlSts 0;
BA_ "SignalLongName" SG_ 846 ALCLumLvlSts "ALC Lumination Level Status";
BA_ "GenSigStartValue" SG_ 846 ALCLumLvlSts 50;

BA_ "GenSigSendType" SG_ 846 ALCSts 0;
BA_ "SignalLongName" SG_ 846 ALCSts "ALC Status";
BA_ "GenSigStartValue" SG_ 846 ALCSts 2;

BA_ "GenSigSendType" SG_ 846 ALDrFdbkSts 0;
BA_ "SignalLongName" SG_ 846 ALDrFdbkSts "Ambient Lighting Door Feedback Status";

BA_ "GenSigSendType" SG_ 846 ALCallRmdSts 0;
BA_ "SignalLongName" SG_ 846 ALCallRmdSts "Ambient Lighting Call Remind Status";

BA_ "GenSigSendType" SG_ 846 ALStartFdbkSts 0;
BA_ "SignalLongName" SG_ 846 ALStartFdbkSts "Ambient Lighting Start Feedback Status";

BA_ "GenSigSendType" SG_ 846 ALRhythmSts 0;
BA_ "SignalLongName" SG_ 846 ALRhythmSts "Ambient Lighting Rhythm Status";

BA_ "GenMsgSendType" BO_ 848 0;
BA_ "GenMsgStartDelayTime" BO_ 848 30;
BA_ "GenMsgCycleTime" BO_ 848 500;
BA_ "GenMsgILSupport" BO_ 848 1;
BA_ "GenMsgCycleTimeFast" BO_ 848 40;
BA_ "GenMsgNrOfRepetition" BO_ 848 3;
BA_ "GenMsgDelayTime" BO_ 848 20;
BA_ "VFrameFormat" BO_ 848 14;

BA_ "GenSigSendType" SG_ 848 StSysCstmSetFdbk 4;
BA_ "SignalLongName" SG_ 848 StSysCstmSetFdbk "Seat System Custom Set Feedback";

BA_ "GenSigSendType" SG_ 848 StSysLnkgSts_Dwdlr_R 4;
BA_ "SignalLongName" SG_ 848 StSysLnkgSts_Dwdlr_R "Seat System Linkage Status_Dawdler Mode_R";

BA_ "GenSigSendType" SG_ 848 StSysSftyAlrm 4;
BA_ "SignalLongName" SG_ 848 StSysSftyAlrm "Seat System Safety Alarm";

BA_ "GenSigSendType" SG_ 848 StSysLnkgSts_Thrn 4;
BA_ "SignalLongName" SG_ 848 StSysLnkgSts_Thrn "Seat System Linkage Status_Throne Mode";

BA_ "GenSigSendType" SG_ 848 StSysLnkgSts_Dwdlr_L 4;
BA_ "SignalLongName" SG_ 848 StSysLnkgSts_Dwdlr_L "Seat System Linkage Status_Dawdler Mode Left";

BA_ "GenSigSendType" SG_ 848 StSysLnkgSts_FstCls 4;
BA_ "SignalLongName" SG_ 848 StSysLnkgSts_FstCls "Seat System Linkage Status_First Class Mode";

BA_ "GenSigSendType" SG_ 848 StSysLnkgSts_Strg 4;
BA_ "SignalLongName" SG_ 848 StSysLnkgSts_Strg "Seat System Linkage Status_Storage Mode";

BA_ "GenSigSendType" SG_ 848 StSysLnkgSts_Bbs 4;
BA_ "SignalLongName" SG_ 848 StSysLnkgSts_Bbs "Seat System Linkage Status_Babies Mode";

BA_ "GenSigSendType" SG_ 848 StSysLnkgSts_Cstm 4;
BA_ "SignalLongName" SG_ 848 StSysLnkgSts_Cstm "Seat System Linkage Status_Custom Mode";

BA_ "GenSigSendType" SG_ 848 StSysLnkgEnbl_Thrn 4;
BA_ "SignalLongName" SG_ 848 StSysLnkgEnbl_Thrn "Seat System Linkage Enable_Throne Mode";

BA_ "GenSigSendType" SG_ 848 StSysLnkgEnbl_Dwdlr_L 4;
BA_ "SignalLongName" SG_ 848 StSysLnkgEnbl_Dwdlr_L "Seat System Linkage Enable_Dawdler Mode Left";

BA_ "GenSigSendType" SG_ 848 StSysLnkgEnbl_FstCls 4;
BA_ "SignalLongName" SG_ 848 StSysLnkgEnbl_FstCls "Seat System Linkage Enable_First Class Mode";

BA_ "GenSigSendType" SG_ 848 StSysLnkgEnbl_Strg 4;
BA_ "SignalLongName" SG_ 848 StSysLnkgEnbl_Strg "Seat System Linkage Enable_Storage Mode";

BA_ "GenSigSendType" SG_ 848 StSysLnkgEnbl_Bbs 4;
BA_ "SignalLongName" SG_ 848 StSysLnkgEnbl_Bbs "Seat System Linkage Enable_Babies Mode";

BA_ "GenSigSendType" SG_ 848 StSysLnkgEnbl_Cstm 4;
BA_ "SignalLongName" SG_ 848 StSysLnkgEnbl_Cstm "Seat System Linkage Enable_Custom Mode";

BA_ "GenSigSendType" SG_ 848 StSysLnkgSts_Rset 4;
BA_ "SignalLongName" SG_ 848 StSysLnkgSts_Rset "Seat System Linkage Status_Reset";

BA_ "GenSigSendType" SG_ 848 StSysLnkgOprtSts 0;
BA_ "SignalLongName" SG_ 848 StSysLnkgOprtSts "Seat System Linkage Operation Status";

BA_ "GenSigSendType" SG_ 848 MemCalOtExctSts_DR 4;
BA_ "SignalLongName" SG_ 848 MemCalOtExctSts_DR "Memorization Callout Execution status_DR";

BA_ "GenSigSendType" SG_ 848 IntltWlcmSts 4;
BA_ "SignalLongName" SG_ 848 IntltWlcmSts "IntelligentWelcomeStatus";

BA_ "GenSigSendType" SG_ 848 LockVehRcvrSts 4;
BA_ "SignalLongName" SG_ 848 LockVehRcvrSts "LockVehicleRecoverStatus";

BA_ "GenSigSendType" SG_ 848 StSysLnkgEnbl_Dwdlr_R 4;
BA_ "SignalLongName" SG_ 848 StSysLnkgEnbl_Dwdlr_R "Seat System Linkage Enable_Dawdler Mode_R";

BA_ "GenMsgSendType" BO_ 849 0;
BA_ "GenMsgStartDelayTime" BO_ 849 30;
BA_ "GenMsgCycleTime" BO_ 849 500;
BA_ "GenMsgILSupport" BO_ 849 1;
BA_ "GenMsgCycleTimeFast" BO_ 849 40;
BA_ "GenMsgNrOfRepetition" BO_ 849 3;
BA_ "GenMsgDelayTime" BO_ 849 20;
BA_ "VFrameFormat" BO_ 849 14;

BA_ "GenSigSendType" SG_ 849 StSysLnkgReq_HMI 4;
BA_ "SignalLongName" SG_ 849 StSysLnkgReq_HMI "Seat System Linkage Request_HMI";

BA_ "GenSigSendType" SG_ 849 StSysCstmReq_HMI 4;
BA_ "SignalLongName" SG_ 849 StSysCstmReq_HMI "Seat System Custom Request_HMI";

BA_ "GenMsgSendType" BO_ 851 0;
BA_ "GenMsgStartDelayTime" BO_ 851 15;
BA_ "GenMsgCycleTime" BO_ 851 500;
BA_ "GenMsgILSupport" BO_ 851 1;
BA_ "VFrameFormat" BO_ 851 14;

BA_ "GenSigSendType" SG_ 851 TrOilTempV 0;
BA_ "SignalLongName" SG_ 851 TrOilTempV "Transmission Oil Temperature Validity";

BA_ "GenSigSendType" SG_ 851 TrOilTemp 0;
BA_ "SignalLongName" SG_ 851 TrOilTemp "Transmission Oil Temperature";

BA_ "GenSigSendType" SG_ 851 TrOilTempHighTrqLimInd 0;
BA_ "SignalLongName" SG_ 851 TrOilTempHighTrqLimInd "Transmission oil temperature too high to drive normally and need limit torque indication";

BA_ "GenMsgSendType" BO_ 863 0;
BA_ "GenMsgStartDelayTime" BO_ 863 20;
BA_ "GenMsgCycleTime" BO_ 863 200;
BA_ "GenMsgILSupport" BO_ 863 1;
BA_ "GenMsgCycleTimeFast" BO_ 863 40;
BA_ "GenMsgNrOfRepetition" BO_ 863 3;
BA_ "GenMsgDelayTime" BO_ 863 20;
BA_ "VFrameFormat" BO_ 863 14;

BA_ "GenSigSendType" SG_ 863 MrrFldSts 0;
BA_ "SignalLongName" SG_ 863 MrrFldSts "Mirror Fold Status";

BA_ "GenMsgSendType" BO_ 864 0;
BA_ "GenMsgStartDelayTime" BO_ 864 20;
BA_ "GenMsgCycleTime" BO_ 864 500;
BA_ "GenMsgILSupport" BO_ 864 1;
BA_ "VFrameFormat" BO_ 864 14;

BA_ "GenSigSendType" SG_ 864 BarPrsAbsV 0;
BA_ "SignalLongName" SG_ 864 BarPrsAbsV "Barometric Pressure Absolute Validity";

BA_ "GenSigSendType" SG_ 864 BarPrsAbs 0;
BA_ "SignalLongName" SG_ 864 BarPrsAbs "Barometric Pressure Absolute";

BA_ "GenMsgSendType" BO_ 890 0;
BA_ "GenMsgStartDelayTime" BO_ 890 30;
BA_ "GenMsgCycleTime" BO_ 890 500;
BA_ "GenMsgILSupport" BO_ 890 1;
BA_ "GenMsgCycleTimeFast" BO_ 890 40;
BA_ "GenMsgNrOfRepetition" BO_ 890 3;
BA_ "GenMsgDelayTime" BO_ 890 20;
BA_ "VFrameFormat" BO_ 890 14;

BA_ "GenSigSendType" SG_ 890 StHtEnbl 4;
BA_ "SignalLongName" SG_ 890 StHtEnbl "Seat Heat Enable";

BA_ "GenMsgSendType" BO_ 897 0;
BA_ "GenMsgStartDelayTime" BO_ 897 10;
BA_ "GenMsgCycleTime" BO_ 897 500;
BA_ "GenMsgILSupport" BO_ 897 1;
BA_ "GenMsgCycleTimeFast" BO_ 897 40;
BA_ "GenMsgNrOfRepetition" BO_ 897 3;
BA_ "GenMsgDelayTime" BO_ 897 20;
BA_ "VFrameFormat" BO_ 897 14;

BA_ "GenSigSendType" SG_ 897 TlgtOprt 4;
BA_ "SignalLongName" SG_ 897 TlgtOprt "Tailgate Operation";

BA_ "GenSigSendType" SG_ 897 TlgtPosSts 4;
BA_ "SignalLongName" SG_ 897 TlgtPosSts "Tailgate Position Status";

BA_ "GenSigSendType" SG_ 897 TlgtPos 0;
BA_ "SignalLongName" SG_ 897 TlgtPos "Tailgate Position";
BA_ "GenSigStartValue" SG_ 897 TlgtPos 127;

BA_ "GenSigSendType" SG_ 897 TlgtOprtMd 4;
BA_ "SignalLongName" SG_ 897 TlgtOprtMd "Tailgate Operation Mode";
BA_ "GenSigStartValue" SG_ 897 TlgtOprtMd 2;

BA_ "GenSigSendType" SG_ 897 TlgtAbsAlrm 4;
BA_ "SignalLongName" SG_ 897 TlgtAbsAlrm "Tailgate Abuse Alarm";

BA_ "GenSigSendType" SG_ 897 TlgtOpnPos 4;
BA_ "SignalLongName" SG_ 897 TlgtOpnPos "Tailgate Target Open Position";
BA_ "GenSigStartValue" SG_ 897 TlgtOpnPos 127;

BA_ "GenMsgSendType" BO_ 898 0;
BA_ "GenMsgStartDelayTime" BO_ 898 30;
BA_ "GenMsgCycleTime" BO_ 898 500;
BA_ "GenMsgILSupport" BO_ 898 1;
BA_ "GenMsgCycleTimeFast" BO_ 898 40;
BA_ "GenMsgNrOfRepetition" BO_ 898 3;
BA_ "GenMsgDelayTime" BO_ 898 20;
BA_ "VFrameFormat" BO_ 898 14;

BA_ "GenSigSendType" SG_ 898 SmrtWlcmVcReq 4;
BA_ "SignalLongName" SG_ 898 SmrtWlcmVcReq "Smart Welcome Voice Request";

BA_ "GenSigSendType" SG_ 898 SmrtFrwllVcReq 4;
BA_ "SignalLongName" SG_ 898 SmrtFrwllVcReq "Smart Farewell Voice Request";

BA_ "GenMsgSendType" BO_ 900 0;
BA_ "GenMsgStartDelayTime" BO_ 900 20;
BA_ "GenMsgCycleTime" BO_ 900 500;
BA_ "GenMsgILSupport" BO_ 900 1;
BA_ "GenMsgCycleTimeFast" BO_ 900 40;
BA_ "GenMsgNrOfRepetition" BO_ 900 3;
BA_ "GenMsgDelayTime" BO_ 900 20;
BA_ "VFrameFormat" BO_ 900 14;

BA_ "GenSigSendType" SG_ 900 AVASPauseFuncReq 4;
BA_ "SignalLongName" SG_ 900 AVASPauseFuncReq "AVAS Pause Function Request";

BA_ "GenSigSendType" SG_ 900 VehSoundGenerateReq 4;
BA_ "SignalLongName" SG_ 900 VehSoundGenerateReq "Vehicle Sound Generate Request";

BA_ "GenSigSendType" SG_ 900 FxdMdSetReq 4;
BA_ "SignalLongName" SG_ 900 FxdMdSetReq "FixedModeSetRequest";

BA_ "GenSigSendType" SG_ 900 AirSuspensionHeightReq 4;
BA_ "SignalLongName" SG_ 900 AirSuspensionHeightReq "AirSuspensionHeightReq";

BA_ "GenSigSendType" SG_ 900 HLCMainSwSetReq 4;
BA_ "SignalLongName" SG_ 900 HLCMainSwSetReq "HLCMainSwitchSetRequest";

BA_ "GenSigSendType" SG_ 900 ECDCtrlReq_HMI 4;
BA_ "SignalLongName" SG_ 900 ECDCtrlReq_HMI "Electric Charging Door Control Request_HMI";

BA_ "GenSigSendType" SG_ 900 DcrtvLmpSwReq 4;
BA_ "SignalLongName" SG_ 900 DcrtvLmpSwReq "DecorativeLampSwitchRequest";

BA_ "GenMsgSendType" BO_ 904 0;
BA_ "GenMsgStartDelayTime" BO_ 904 15;
BA_ "GenMsgCycleTime" BO_ 904 500;
BA_ "GenMsgILSupport" BO_ 904 1;
BA_ "GenMsgCycleTimeFast" BO_ 904 40;
BA_ "GenMsgNrOfRepetition" BO_ 904 5;
BA_ "GenMsgDelayTime" BO_ 904 20;
BA_ "VFrameFormat" BO_ 904 14;

BA_ "GenSigSendType" SG_ 904 LeavVentStsReq_HMI 4;
BA_ "SignalLongName" SG_ 904 LeavVentStsReq_HMI "Leave Vent Status Requst";

BA_ "GenSigSendType" SG_ 904 HVACBloLimtSetReq_HMI 4;
BA_ "SignalLongName" SG_ 904 HVACBloLimtSetReq_HMI "HVAC Blower Limit Set Request";

BA_ "GenSigSendType" SG_ 904 OtsdAirPrtclMtrCDC_HMI 0;
BA_ "SignalLongName" SG_ 904 OtsdAirPrtclMtrCDC_HMI "Outside Air Particulate Matter Concentration Display Command";

BA_ "GenSigSendType" SG_ 904 OtsAirHumidity_HMI 0;
BA_ "SignalLongName" SG_ 904 OtsAirHumidity_HMI "Outside Air Humidity";

BA_ "GenSigSendType" SG_ 904 TrafficCongestionSts_HMI 0;
BA_ "SignalLongName" SG_ 904 TrafficCongestionSts_HMI "Traffic Congestion Status";

BA_ "GenSigSendType" SG_ 904 HVACAtDefReq_HMI 4;
BA_ "SignalLongName" SG_ 904 HVACAtDefReq_HMI "HVAC Auto Defrost Requst";

BA_ "GenSigSendType" SG_ 904 CallInStatus_HMI 0;
BA_ "SignalLongName" SG_ 904 CallInStatus_HMI "CallIn Status";

BA_ "GenSigSendType" SG_ 904 AmbtTemp_HMI 0;
BA_ "SignalLongName" SG_ 904 AmbtTemp_HMI "Ambiant Temperature";

BA_ "GenSigSendType" SG_ 904 HVACQuietSet_HMI 4;
BA_ "SignalLongName" SG_ 904 HVACQuietSet_HMI "HVAC Quiet Set";

BA_ "GenSigSendType" SG_ 904 HeatFrtWndsldSwReq 4;
BA_ "SignalLongName" SG_ 904 HeatFrtWndsldSwReq "Heat Front Windshield Switch Request";

BA_ "GenSigSendType" SG_ 904 HVACAtCylTimReq_HMI 4;
BA_ "SignalLongName" SG_ 904 HVACAtCylTimReq_HMI "HVAC Auto Cycle Time Request";

BA_ "GenSigSendType" SG_ 904 HVACAirFltrReset_HMI 4;
BA_ "SignalLongName" SG_ 904 HVACAirFltrReset_HMI "HVAC Air Filter Reset";

BA_ "GenSigSendType" SG_ 904 RCPSWEnblSet 4;
BA_ "SignalLongName" SG_ 904 RCPSWEnblSet "RCP Switch Enable Set";

BA_ "GenMsgSendType" BO_ 909 0;
BA_ "GenMsgStartDelayTime" BO_ 909 20;
BA_ "GenMsgCycleTime" BO_ 909 500;
BA_ "GenMsgILSupport" BO_ 909 1;
BA_ "GenMsgCycleTimeFast" BO_ 909 40;
BA_ "GenMsgNrOfRepetition" BO_ 909 3;
BA_ "GenMsgDelayTime" BO_ 909 20;
BA_ "VFrameFormat" BO_ 909 14;

BA_ "GenSigSendType" SG_ 909 StTrgtSlc_HMI 4;
BA_ "SignalLongName" SG_ 909 StTrgtSlc_HMI "Seat Target Select_HMI";

BA_ "GenSigSendType" SG_ 909 StTrkPosReq_HMI 4;
BA_ "SignalLongName" SG_ 909 StTrkPosReq_HMI "Seat Track Position Request_HMI";
BA_ "GenSigTimeoutValue" SG_ 909 StTrkPosReq_HMI 31;
BA_ "GenSigStartValue" SG_ 909 StTrkPosReq_HMI 31;

BA_ "GenSigSendType" SG_ 909 StRtaPosReq_HMI 4;
BA_ "SignalLongName" SG_ 909 StRtaPosReq_HMI "Seat Rotation Position Request_HMI";
BA_ "GenSigTimeoutValue" SG_ 909 StRtaPosReq_HMI 31;
BA_ "GenSigStartValue" SG_ 909 StRtaPosReq_HMI 31;

BA_ "GenSigSendType" SG_ 909 StPhaPosReq_HMI 4;
BA_ "SignalLongName" SG_ 909 StPhaPosReq_HMI "Seat Pha Position Request_HMI";
BA_ "GenSigTimeoutValue" SG_ 909 StPhaPosReq_HMI 31;
BA_ "GenSigStartValue" SG_ 909 StPhaPosReq_HMI 31;

BA_ "GenSigSendType" SG_ 909 StTiltPosReq_HMI 4;
BA_ "SignalLongName" SG_ 909 StTiltPosReq_HMI "Seat Tilt Position Request_HMI";
BA_ "GenSigTimeoutValue" SG_ 909 StTiltPosReq_HMI 31;
BA_ "GenSigStartValue" SG_ 909 StTiltPosReq_HMI 31;

BA_ "GenSigSendType" SG_ 909 StSldPosReq_HMI 4;
BA_ "SignalLongName" SG_ 909 StSldPosReq_HMI "Seat Slide Position Request_HMI";
BA_ "GenSigTimeoutValue" SG_ 909 StSldPosReq_HMI 31;
BA_ "GenSigStartValue" SG_ 909 StSldPosReq_HMI 31;

BA_ "GenSigSendType" SG_ 909 StLgLgthPosReq_HMI 4;
BA_ "SignalLongName" SG_ 909 StLgLgthPosReq_HMI "Seat Legsupport Length Request_HMI";
BA_ "GenSigTimeoutValue" SG_ 909 StLgLgthPosReq_HMI 31;
BA_ "GenSigStartValue" SG_ 909 StLgLgthPosReq_HMI 31;

BA_ "GenSigSendType" SG_ 909 StLgRtaPosReq_HMI 4;
BA_ "SignalLongName" SG_ 909 StLgRtaPosReq_HMI "Seat Legsupport Rotation Position Request_HMI";
BA_ "GenSigTimeoutValue" SG_ 909 StLgRtaPosReq_HMI 31;
BA_ "GenSigStartValue" SG_ 909 StLgRtaPosReq_HMI 31;

BA_ "GenSigSendType" SG_ 909 StHdrstPosReq_HMI 4;
BA_ "SignalLongName" SG_ 909 StHdrstPosReq_HMI "Seat Headrest Position Request_HMI";
BA_ "GenSigTimeoutValue" SG_ 909 StHdrstPosReq_HMI 31;
BA_ "GenSigStartValue" SG_ 909 StHdrstPosReq_HMI 31;

BA_ "GenMsgSendType" BO_ 911 0;
BA_ "GenMsgStartDelayTime" BO_ 911 20;
BA_ "GenMsgCycleTime" BO_ 911 500;
BA_ "GenMsgILSupport" BO_ 911 1;
BA_ "GenMsgCycleTimeFast" BO_ 911 40;
BA_ "GenMsgNrOfRepetition" BO_ 911 3;
BA_ "GenMsgDelayTime" BO_ 911 20;
BA_ "VFrameFormat" BO_ 911 14;

BA_ "GenSigSendType" SG_ 911 RlxMdSts_Lf 0;
BA_ "SignalLongName" SG_ 911 RlxMdSts_Lf "RelaxModeStatus_Left";

BA_ "GenSigSendType" SG_ 911 SlpMdSts_Lf 0;
BA_ "SignalLongName" SG_ 911 SlpMdSts_Lf "SleepModeStatus_Left";

BA_ "GenSigSendType" SG_ 911 WkMdSts_Lf 0;
BA_ "SignalLongName" SG_ 911 WkMdSts_Lf "WorkModeStatus_Left";

BA_ "GenSigSendType" SG_ 911 WmMdSts_Lf 0;
BA_ "SignalLongName" SG_ 911 WmMdSts_Lf "WarmingModeStatus_Left";

BA_ "GenSigSendType" SG_ 911 ClMdSts_Lf 0;
BA_ "SignalLongName" SG_ 911 ClMdSts_Lf "CoolingModeStatus_Left";

BA_ "GenSigSendType" SG_ 911 SmkMdSts_Lf 0;
BA_ "SignalLongName" SG_ 911 SmkMdSts_Lf "SmokingModeStatus_Left";

BA_ "GenSigSendType" SG_ 911 RlxMdSts_Rt 0;
BA_ "SignalLongName" SG_ 911 RlxMdSts_Rt "RelaxModeStatus_Right";

BA_ "GenSigSendType" SG_ 911 SlpMdSts_Rt 0;
BA_ "SignalLongName" SG_ 911 SlpMdSts_Rt "SleepModeStatus_Right";

BA_ "GenSigSendType" SG_ 911 WkMdSts_Rt 0;
BA_ "SignalLongName" SG_ 911 WkMdSts_Rt "WorkModeStatus_Right";

BA_ "GenSigSendType" SG_ 911 WmMdSts_Rt 0;
BA_ "SignalLongName" SG_ 911 WmMdSts_Rt "WarmingModeStatus_Right";

BA_ "GenSigSendType" SG_ 911 ClMdSts_Rt 0;
BA_ "SignalLongName" SG_ 911 ClMdSts_Rt "CoolingModeStatus_Right";

BA_ "GenSigSendType" SG_ 911 SmkMdSts_Rt 0;
BA_ "SignalLongName" SG_ 911 SmkMdSts_Rt "SmokingModeStatus_Right";

BA_ "GenSigSendType" SG_ 911 StBOSSVIPSts_L 4;
BA_ "SignalLongName" SG_ 911 StBOSSVIPSts_L "Seat BOSSVIPStatus_Left";

BA_ "GenSigSendType" SG_ 911 StBOSSVIPSts_R 4;
BA_ "SignalLongName" SG_ 911 StBOSSVIPSts_R "Seat BOSSVIPStatus_Right";

BA_ "GenSigSendType" SG_ 911 OMSCntrlObjt_L 4;
BA_ "SignalLongName" SG_ 911 OMSCntrlObjt_L "OMSControlObject_Left";

BA_ "GenSigSendType" SG_ 911 OMSCntrlObjt_R 4;
BA_ "SignalLongName" SG_ 911 OMSCntrlObjt_R "OMSControlObject_Right";

BA_ "GenSigSendType" SG_ 911 ClMdSts 0;
BA_ "SignalLongName" SG_ 911 ClMdSts "CoolingModeStatus";

BA_ "GenSigSendType" SG_ 911 WmMdSts 0;
BA_ "SignalLongName" SG_ 911 WmMdSts "WarmingModeStatus";

BA_ "GenSigSendType" SG_ 911 CmfrtMdSts 0;
BA_ "SignalLongName" SG_ 911 CmfrtMdSts "ComfortModeStatus";

BA_ "GenSigSendType" SG_ 911 RlxMdSts 0;
BA_ "SignalLongName" SG_ 911 RlxMdSts "RelaxModeStatus";

BA_ "GenSigSendType" SG_ 911 ZenMdSts 0;
BA_ "SignalLongName" SG_ 911 ZenMdSts "ZenModeStatus";

BA_ "GenSigSendType" SG_ 911 MtngMdSts 0;
BA_ "SignalLongName" SG_ 911 MtngMdSts "MeetingModeStatus";

BA_ "GenSigSendType" SG_ 911 StdMdSts 0;
BA_ "SignalLongName" SG_ 911 StdMdSts "StandardModeStatus";

BA_ "GenMsgSendType" BO_ 916 0;
BA_ "GenMsgStartDelayTime" BO_ 916 10;
BA_ "GenMsgCycleTime" BO_ 916 100;
BA_ "GenMsgILSupport" BO_ 916 1;
BA_ "VFrameFormat" BO_ 916 14;

BA_ "GenSigSendType" SG_ 916 EPTRgtnLvl 0;
BA_ "SignalLongName" SG_ 916 EPTRgtnLvl "Electric Powertrain Regeneration Level";

BA_ "GenSigSendType" SG_ 916 HybVehSysStsInd 0;
BA_ "SignalLongName" SG_ 916 HybVehSysStsInd "Hybrid Vehicle System Status Indication";

BA_ "GenSigSendType" SG_ 916 IntgltBatEngyManmtDrvModHCUDisp 0;
BA_ "SignalLongName" SG_ 916 IntgltBatEngyManmtDrvModHCUDisp "Intelligent Battery Energy Management Drive Mode HCU Display";

BA_ "GenSigSendType" SG_ 916 ElecVehSysMd 0;
BA_ "SignalLongName" SG_ 916 ElecVehSysMd "Electric Vehicle System Mode";

BA_ "GenSigSendType" SG_ 916 HybDrvrItndHVBatSOCAch 0;
BA_ "SignalLongName" SG_ 916 HybDrvrItndHVBatSOCAch "Hybrid Driver Intended High Voltage Battery State Of Charge Achieved";

BA_ "GenMsgSendType" BO_ 928 0;
BA_ "GenMsgStartDelayTime" BO_ 928 15;
BA_ "GenMsgCycleTime" BO_ 928 500;
BA_ "GenMsgILSupport" BO_ 928 1;
BA_ "GenMsgCycleTimeFast" BO_ 928 40;
BA_ "GenMsgNrOfRepetition" BO_ 928 3;
BA_ "GenMsgDelayTime" BO_ 928 20;
BA_ "VFrameFormat" BO_ 928 14;

BA_ "GenSigSendType" SG_ 928 FCM_AEBMainSwReq 4;
BA_ "SignalLongName" SG_ 928 FCM_AEBMainSwReq "Forward Collision Mitigation_ Autonomous Emergency Braking Main Switch Request";

BA_ "GenSigSendType" SG_ 928 LDWReminderReq 4;
BA_ "SignalLongName" SG_ 928 LDWReminderReq "Lane Departure Warning Reminder Request";

BA_ "GenSigSendType" SG_ 928 LDWAccuracyReq 4;
BA_ "SignalLongName" SG_ 928 LDWAccuracyReq "Lane Departure Warning Accuracy Request";

BA_ "GenSigSendType" SG_ 928 LKA_LDW_ELKMainSwReq 4;
BA_ "SignalLongName" SG_ 928 LKA_LDW_ELKMainSwReq "Lane Keeping Assist_ Lane Departure Warning _Emergency Lane keeping Main Switch Request";

BA_ "GenSigSendType" SG_ 928 SLIF_ISAMainSwReq 4;
BA_ "SignalLongName" SG_ 928 SLIF_ISAMainSwReq "Speed Limit Information Function_Intelligent Speed Assistance Main Switch Request";

BA_ "GenSigSendType" SG_ 928 FCMMainSensitivityReq 4;
BA_ "SignalLongName" SG_ 928 FCMMainSensitivityReq "Forward Collision Mitgation system Main Sensitivity Request";

BA_ "GenSigSendType" SG_ 928 ICA_ALCAMainSwReq 4;
BA_ "SignalLongName" SG_ 928 ICA_ALCAMainSwReq "ICA_ALCA Main Switch Request";

BA_ "GenSigSendType" SG_ 928 DASSoundCtrlSetReq 4;
BA_ "SignalLongName" SG_ 928 DASSoundCtrlSetReq "DAS Sound Control Set Request";

BA_ "GenSigSendType" SG_ 928 MAPMainSwReq 4;
BA_ "SignalLongName" SG_ 928 MAPMainSwReq "Maxus Auto Pilot Main Switch Request";

BA_ "GenSigSendType" SG_ 928 BSDMainSwReq 4;
BA_ "SignalLongName" SG_ 928 BSDMainSwReq "Blind Spot Detect_Lane Change Assist Main Switch Request";

BA_ "GenSigSendType" SG_ 928 MAPRemindReq 4;
BA_ "SignalLongName" SG_ 928 MAPRemindReq "Maxus Auto Pilot Remind Request";

BA_ "GenSigSendType" SG_ 928 AESMainSwReq 4;
BA_ "SignalLongName" SG_ 928 AESMainSwReq "Automatic Emergency Steering Main Switch Request";

BA_ "GenSigSendType" SG_ 928 MAPSpdAccuracyReq 4;
BA_ "SignalLongName" SG_ 928 MAPSpdAccuracyReq "Maxus Auto Pilot Speed Accuracy Request";

BA_ "GenSigSendType" SG_ 928 MAP_ICA_ACCFunctionSwReq 4;
BA_ "SignalLongName" SG_ 928 MAP_ICA_ACCFunctionSwReq "MAP_ICA_ACC Function Switch Request";

BA_ "GenSigSendType" SG_ 928 ChangeLaneConfirmToMsgBox 4;
BA_ "SignalLongName" SG_ 928 ChangeLaneConfirmToMsgBox "Change Lane Confirm To Message Box";

BA_ "GenSigSendType" SG_ 928 MAPChngLaneConfirmReq 4;
BA_ "SignalLongName" SG_ 928 MAPChngLaneConfirmReq "Maxus Auto Pilot Change Lane Confirm Request";

BA_ "GenSigSendType" SG_ 928 IHCMainSwReq 4;
BA_ "SignalLongName" SG_ 928 IHCMainSwReq "Intelligence Headlamp Control Main Switch Request";

BA_ "GenSigSendType" SG_ 928 MAPRcmndConfirmReq 4;
BA_ "SignalLongName" SG_ 928 MAPRcmndConfirmReq "Maxus Auto Pilot Recomand Confirm Request";

BA_ "GenSigSendType" SG_ 928 MAPRcmndConfirmBeforeETC 4;
BA_ "SignalLongName" SG_ 928 MAPRcmndConfirmBeforeETC "Maxus Auto Pilot Recomand Confirm Before ETC";

BA_ "GenSigSendType" SG_ 928 DASDrvrSetHdwayReq 4;
BA_ "SignalLongName" SG_ 928 DASDrvrSetHdwayReq "DAS Driver Set Headway Request";

BA_ "GenSigSendType" SG_ 928 PASoundCtrlSetReq 4;
BA_ "SignalLongName" SG_ 928 PASoundCtrlSetReq "Parking Assist Sound Control Set Request";

BA_ "GenSigSendType" SG_ 928 PASoundCtrlReq 4;
BA_ "SignalLongName" SG_ 928 PASoundCtrlReq "Parking Assist Sound Control Request";

BA_ "GenSigSendType" SG_ 928 DASDrvrSetSpdReq 4;
BA_ "SignalLongName" SG_ 928 DASDrvrSetSpdReq "DAS Driver Set Speed Request";
BA_ "GenSigTimeoutValue" SG_ 928 DASDrvrSetSpdReq 255;
BA_ "GenSigStartValue" SG_ 928 DASDrvrSetSpdReq 255;

BA_ "GenSigSendType" SG_ 928 SoundCtrlLaneChng 4;
BA_ "SignalLongName" SG_ 928 SoundCtrlLaneChng "Sound Control Lane Change";

BA_ "GenSigSendType" SG_ 928 SentryMdSensitivityReq 4;
BA_ "SignalLongName" SG_ 928 SentryMdSensitivityReq "SentryModedSensitivityRequest";

BA_ "GenSigSendType" SG_ 928 LDWSundWrnngReq 4;
BA_ "SignalLongName" SG_ 928 LDWSundWrnngReq "Lane Departure Warning Sound Warning Request";

BA_ "GenMsgSendType" BO_ 937 0;
BA_ "GenMsgStartDelayTime" BO_ 937 15;
BA_ "GenMsgCycleTime" BO_ 937 500;
BA_ "GenMsgILSupport" BO_ 937 1;
BA_ "GenMsgCycleTimeFast" BO_ 937 40;
BA_ "GenMsgNrOfRepetition" BO_ 937 3;
BA_ "GenMsgDelayTime" BO_ 937 20;
BA_ "VFrameFormat" BO_ 937 14;

BA_ "GenSigSendType" SG_ 937 SLIFSundWrnngReq 4;
BA_ "SignalLongName" SG_ 937 SLIFSundWrnngReq "Speed Linit Information Function Sound Warning Request";

BA_ "GenSigSendType" SG_ 937 ELKMainSwReq 4;
BA_ "SignalLongName" SG_ 937 ELKMainSwReq "Emergency Lane keeping Main Switch Request";

BA_ "GenSigSendType" SG_ 937 SLIFMainSwReq 4;
BA_ "SignalLongName" SG_ 937 SLIFMainSwReq "Speed Limit Information Function Main Switch Request";

BA_ "GenSigSendType" SG_ 937 ISAMainSwReq 4;
BA_ "SignalLongName" SG_ 937 ISAMainSwReq "Intelligent Speed Assistance Main Switch Request";

BA_ "GenSigSendType" SG_ 937 LKA_LDWMainSwReq 4;
BA_ "SignalLongName" SG_ 937 LKA_LDWMainSwReq "Lane Keeping Assist_ Lane Departure Warning Main Switch Request";

BA_ "GenSigSendType" SG_ 937 BSISMainSwReq 4;
BA_ "SignalLongName" SG_ 937 BSISMainSwReq "Blind Spot Information System Main Switch Request";

BA_ "GenSigSendType" SG_ 937 MOISMainSwReq 4;
BA_ "SignalLongName" SG_ 937 MOISMainSwReq "Moving Off Information System Main Switch Request";

BA_ "GenSigSendType" SG_ 937 SpdLimitOffsetSta 0;

BA_ "GenSigSendType" SG_ 937 SpdLimitOffsetValue 0;

BA_ "GenSigSendType" SG_ 937 SpdLimitOffsetValuePlusMinus 0;

BA_ "GenSigSendType" SG_ 937 FCMVibrationCfg 0;

BA_ "GenSigSendType" SG_ 937 FCMReminderReq 0;

BA_ "GenSigSendType" SG_ 937 LDWReminderTypeReq 0;

BA_ "GenSigSendType" SG_ 937 LDWVibrationCfg 0;

BA_ "GenSigSendType" SG_ 937 BSDLCAMainSwReq 0;

BA_ "GenSigSendType" SG_ 937 RCTAMainSwReq 0;

BA_ "GenSigSendType" SG_ 937 DOWMainSwReq 0;

BA_ "GenSigSendType" SG_ 937 RCWMainSwReq 0;

BA_ "GenSigSendType" SG_ 937 RAEBMainSwReq 0;

BA_ "GenMsgSendType" BO_ 931 0;
BA_ "GenMsgStartDelayTime" BO_ 931 15;
BA_ "GenMsgCycleTime" BO_ 931 500;
BA_ "GenMsgILSupport" BO_ 931 1;
BA_ "GenMsgCycleTimeFast" BO_ 931 40;
BA_ "GenMsgNrOfRepetition" BO_ 931 3;
BA_ "GenMsgDelayTime" BO_ 931 20;
BA_ "VFrameFormat" BO_ 931 14;

BA_ "GenSigSendType" SG_ 931 FICMALCLumLvlReq 4;
BA_ "SignalLongName" SG_ 931 FICMALCLumLvlReq "FICM ALC Lumination Level Request";
BA_ "GenSigStartValue" SG_ 931 FICMALCLumLvlReq 127;

BA_ "GenSigSendType" SG_ 931 FICMALCColLvlReq 4;
BA_ "SignalLongName" SG_ 931 FICMALCColLvlReq "FICM ALC Color Level Request";
BA_ "GenSigStartValue" SG_ 931 FICMALCColLvlReq 255;

BA_ "GenSigSendType" SG_ 931 FICMALCSw 4;
BA_ "SignalLongName" SG_ 931 FICMALCSw "FICM ALC Switch";

BA_ "GenSigSendType" SG_ 931 ALDrFdbkSw 4;
BA_ "SignalLongName" SG_ 931 ALDrFdbkSw "Ambient Lighting Door Feedback Switch";

BA_ "GenSigSendType" SG_ 931 ALCallRmdSw 4;
BA_ "SignalLongName" SG_ 931 ALCallRmdSw "Ambient Lighting Call Remind Switch";

BA_ "GenSigSendType" SG_ 931 ALCallRmdReq 4;
BA_ "SignalLongName" SG_ 931 ALCallRmdReq "Ambient Lighting Call Remind Request";

BA_ "GenSigSendType" SG_ 931 ALStartFdbkSw 4;
BA_ "SignalLongName" SG_ 931 ALStartFdbkSw "Ambient Lighting Start Feedback Switch";

BA_ "GenSigSendType" SG_ 931 ALRhythmSw 4;
BA_ "SignalLongName" SG_ 931 ALRhythmSw "Ambient Lighting Rhythm Switch";

BA_ "GenSigSendType" SG_ 931 FICMALCMdReq 4;
BA_ "SignalLongName" SG_ 931 FICMALCMdReq "FICM ALC Mode Request";

BA_ "GenSigSendType" SG_ 931 ALColourRhythmCmd 4;
BA_ "SignalLongName" SG_ 931 ALColourRhythmCmd "Ambient Lighting Colour Rhythm Command";
BA_ "GenSigStartValue" SG_ 931 ALColourRhythmCmd 255;

BA_ "GenSigSendType" SG_ 931 ALLumRhythmCmd 4;
BA_ "SignalLongName" SG_ 931 ALLumRhythmCmd "Ambient Lighting Lumination Rhythm Command";
BA_ "GenSigStartValue" SG_ 931 ALLumRhythmCmd 127;

BA_ "GenSigSendType" SG_ 931 ALVocIntfcSw 4;
BA_ "SignalLongName" SG_ 931 ALVocIntfcSw "Ambient Lighting Voice Interface Switch";

BA_ "GenSigSendType" SG_ 931 ALVocIntfcReq 4;
BA_ "SignalLongName" SG_ 931 ALVocIntfcReq "Ambient Lighting Voice Interface Request";

BA_ "GenSigSendType" SG_ 931 ALVocWkupReq 4;
BA_ "SignalLongName" SG_ 931 ALVocWkupReq "Ambient Lighting Voice Wakeup Request";

BA_ "GenMsgSendType" BO_ 933 0;
BA_ "GenMsgStartDelayTime" BO_ 933 15;
BA_ "GenMsgCycleTime" BO_ 933 500;
BA_ "GenMsgILSupport" BO_ 933 1;
BA_ "GenMsgCycleTimeFast" BO_ 933 40;
BA_ "GenMsgNrOfRepetition" BO_ 933 3;
BA_ "GenMsgDelayTime" BO_ 933 20;
BA_ "VFrameFormat" BO_ 933 14;

BA_ "GenSigSendType" SG_ 933 StTrkAdjReq_PR 4;
BA_ "SignalLongName" SG_ 933 StTrkAdjReq_PR "Seat Track Adjust Request_PR";

BA_ "GenSigSendType" SG_ 933 StRtaAdjReq_PR 4;
BA_ "SignalLongName" SG_ 933 StRtaAdjReq_PR "Seat Rotation Adjust Request_PR";

BA_ "GenSigSendType" SG_ 933 StTrkAdjReq_RL_FICM 4;
BA_ "SignalLongName" SG_ 933 StTrkAdjReq_RL_FICM "Seat Track Adjust Request_RL_FICM";

BA_ "GenSigSendType" SG_ 933 StRtaAdjReq_RL_FICM 4;
BA_ "SignalLongName" SG_ 933 StRtaAdjReq_RL_FICM "Seat Rotation Adjust Request_RL_FICM";

BA_ "GenSigSendType" SG_ 933 StTrkAdjReq_RR_FICM 4;
BA_ "SignalLongName" SG_ 933 StTrkAdjReq_RR_FICM "Seat Track Adjust Request_RR_FICM";

BA_ "GenSigSendType" SG_ 933 StRtaAdjReq_RR_FICM 4;
BA_ "SignalLongName" SG_ 933 StRtaAdjReq_RR_FICM "Seat Rotation Adjust Request_RR_FICM";

BA_ "GenSigSendType" SG_ 933 StTrkAdjReq_3rdL_FICM 4;
BA_ "SignalLongName" SG_ 933 StTrkAdjReq_3rdL_FICM "Seat Track Adjust Request_3rdL_FICM";

BA_ "GenSigSendType" SG_ 933 StTrkAdjReq_3rdR_FICM 4;
BA_ "SignalLongName" SG_ 933 StTrkAdjReq_3rdR_FICM "Seat Track Adjust Request_3rdR_FICM";

BA_ "GenSigSendType" SG_ 933 StHtReq_DR 4;
BA_ "SignalLongName" SG_ 933 StHtReq_DR "Seat_DR Heat Request";

BA_ "GenSigSendType" SG_ 933 StHtReq_PR 4;
BA_ "SignalLongName" SG_ 933 StHtReq_PR "Seat_PR Heat Request";

BA_ "GenSigSendType" SG_ 933 MemReq_PR 4;
BA_ "SignalLongName" SG_ 933 MemReq_PR "Seat_PR Memorize Request";

BA_ "GenSigSendType" SG_ 933 StVtReq_DR 4;
BA_ "SignalLongName" SG_ 933 StVtReq_DR "Seat_DR Vent Request";

BA_ "GenSigSendType" SG_ 933 StVtReq_PR 4;
BA_ "SignalLongName" SG_ 933 StVtReq_PR "Seat_PR Vent Request";

BA_ "GenSigSendType" SG_ 933 MemCalOtReq_PR 4;
BA_ "SignalLongName" SG_ 933 MemCalOtReq_PR "Seat_PR Memorization Call Out Request";

BA_ "GenSigSendType" SG_ 933 MemClrReq_PR 4;
BA_ "SignalLongName" SG_ 933 MemClrReq_PR "Seat_PR Memorize Clear Request";

BA_ "GenSigSendType" SG_ 933 StWelcomeSet_DR 4;
BA_ "SignalLongName" SG_ 933 StWelcomeSet_DR "Seat Welcome Set_DR";

BA_ "GenSigSendType" SG_ 933 StSysRstReq 4;
BA_ "SignalLongName" SG_ 933 StSysRstReq "Seat System Reset Request";

BA_ "GenSigSendType" SG_ 933 MemReq_DR 4;
BA_ "SignalLongName" SG_ 933 MemReq_DR "Seat_DR Memorize Request";

BA_ "GenSigSendType" SG_ 933 StMsgReq_DR 4;
BA_ "SignalLongName" SG_ 933 StMsgReq_DR "Seat Massage Request_DR";

BA_ "GenSigSendType" SG_ 933 StMsgReq_PR 4;
BA_ "SignalLongName" SG_ 933 StMsgReq_PR "Seat Massage Request_PR";

BA_ "GenSigSendType" SG_ 933 StMsgIntstyReq_DR 4;
BA_ "SignalLongName" SG_ 933 StMsgIntstyReq_DR "Seat Massage Intensity Request_DR";

BA_ "GenSigSendType" SG_ 933 StMsgIntstyReq_PR 4;
BA_ "SignalLongName" SG_ 933 StMsgIntstyReq_PR "Seat Massage Intensity Request_PR";

BA_ "GenSigSendType" SG_ 933 MemCalOtReq_DR 4;
BA_ "SignalLongName" SG_ 933 MemCalOtReq_DR "Seat_DR Memorization Call Out Request";

BA_ "GenSigSendType" SG_ 933 MemClrReq_DR 4;
BA_ "SignalLongName" SG_ 933 MemClrReq_DR "Seat_DR Memorize Clear Request";

BA_ "GenSigSendType" SG_ 933 StFRtaReq 4;
BA_ "SignalLongName" SG_ 933 StFRtaReq " Seat Forward Rotate Request";

BA_ "GenSigSendType" SG_ 933 StBRtaReq 4;
BA_ "SignalLongName" SG_ 933 StBRtaReq " Seat Back Rotate Request";
BA_REL_ "GenSigTimeoutTime" BU_SG_REL_ FICM_FD SG_ 741 RemainDrvngDist 1000;
BA_REL_ "GenSigTimeoutTime" BU_SG_REL_ FICM_FD SG_ 742 AvgElectricCsump 1000;
BA_REL_ "GenSigTimeoutTime" BU_SG_REL_ FICM_FD SG_ 742 IPK1KmOrMileAvgCsumpRolling 1000;
BA_REL_ "GenSigTimeoutTime" BU_SG_REL_ FICM_FD SG_ 742 IPK1KmOrMileAvgElecEnergyCsump 1000;
BA_REL_ "GenSigTimeoutTime" BU_SG_REL_ FICM_FD SG_ 747 CustzEqlzrBand9Dsp 1000;
BA_REL_ "GenSigTimeoutTime" BU_SG_REL_ FICM_FD SG_ 747 CustzEqlzrBand10Dsp 1000;
BA_REL_ "GenSigTimeoutTime" BU_SG_REL_ FICM_FD SG_ 747 CustzEqlzrBand11Dsp 1000;
BA_REL_ "GenSigTimeoutTime" BU_SG_REL_ FICM_FD SG_ 747 CustzEqlzrBand12Dsp 1000;
BA_REL_ "GenSigTimeoutTime" BU_SG_REL_ FICM_FD SG_ 747 CustzEqlzrBand13Dsp 1000;
BA_REL_ "GenSigTimeoutTime" BU_SG_REL_ FICM_FD SG_ 747 CustzEqlzrBand14Dsp 1000;
BA_REL_ "GenSigTimeoutTime" BU_SG_REL_ FICM_FD SG_ 747 CustzEqlzrBand15Dsp 1000;
BA_REL_ "GenSigTimeoutTime" BU_SG_REL_ FICM_FD SG_ 747 CustzEqlzrBand16Dsp 1000;
BA_REL_ "GenSigTimeoutTime" BU_SG_REL_ FICM_FD SG_ 753 PassngrCbnLckSts 5000;
BA_REL_ "GenSigTimeoutTime" BU_SG_REL_ FICM_FD SG_ 753 LckSts_DR 5000;
BA_REL_ "GenSigTimeoutTime" BU_SG_REL_ FICM_FD SG_ 753 LckSts_Mid 5000;
BA_REL_ "GenSigTimeoutTime" BU_SG_REL_ FICM_FD SG_ 753 DrAjr_Mid 5000;
BA_REL_ "GenSigTimeoutTime" BU_SG_REL_ FICM_FD SG_ 753 DrAjr_MidV 5000;
BA_REL_ "GenSigTimeoutTime" BU_SG_REL_ FICM_FD SG_ 753 DrAjr_DR 5000;
BA_REL_ "GenSigTimeoutTime" BU_SG_REL_ FICM_FD SG_ 753 DrAjr_DRV 5000;
BA_REL_ "GenSigTimeoutTime" BU_SG_REL_ FICM_FD SG_ 753 DrAjr_PR 5000;
BA_REL_ "GenSigTimeoutTime" BU_SG_REL_ FICM_FD SG_ 753 DrAjr_PRV 5000;
BA_REL_ "GenSigTimeoutTime" BU_SG_REL_ FICM_FD SG_ 753 WdwDRPos 5000;
BA_REL_ "GenSigTimeoutTime" BU_SG_REL_ FICM_FD SG_ 753 WdwPRPos 5000;
BA_REL_ "GenSigTimeoutTime" BU_SG_REL_ FICM_FD SG_ 753 ECDrSts 5000;
BA_REL_ "GenSigTimeoutTime" BU_SG_REL_ FICM_FD SG_ 753 ECDCtrlReqDisable 5000;
BA_REL_ "GenSigTimeoutTime" BU_SG_REL_ FICM_FD SG_ 754 DrAjr_RL 5000;
BA_REL_ "GenSigTimeoutTime" BU_SG_REL_ FICM_FD SG_ 754 DrAjr_RLV 5000;
BA_REL_ "GenSigTimeoutTime" BU_SG_REL_ FICM_FD SG_ 754 DrAjr_RR 5000;
BA_REL_ "GenSigTimeoutTime" BU_SG_REL_ FICM_FD SG_ 754 DrAjr_RRV 5000;
BA_REL_ "GenSigTimeoutTime" BU_SG_REL_ FICM_FD SG_ 754 WdwRLPos 5000;
BA_REL_ "GenSigTimeoutTime" BU_SG_REL_ FICM_FD SG_ 754 WdwRRPos 5000;
BA_REL_ "GenSigTimeoutTime" BU_SG_REL_ FICM_FD SG_ 754 PwrPdlModuSts_RL 5000;
BA_REL_ "GenSigTimeoutTime" BU_SG_REL_ FICM_FD SG_ 754 PwrPdlModuSts_RR 5000;
BA_REL_ "GenSigTimeoutTime" BU_SG_REL_ FICM_FD SG_ 754 HVFuelSts 5000;
BA_REL_ "GenSigTimeoutTime" BU_SG_REL_ FICM_FD SG_ 754 Ajr_HVFulBxV 5000;
BA_REL_ "GenSigTimeoutTime" BU_SG_REL_ FICM_FD SG_ 754 Ajr_HVFulBx 5000;
BA_REL_ "GenSigTimeoutTime" BU_SG_REL_ FICM_FD SG_ 754 ChldLckSts_RR 5000;
BA_REL_ "GenSigTimeoutTime" BU_SG_REL_ FICM_FD SG_ 754 ChldLckSts_RL 5000;
BA_REL_ "GenSigTimeoutTime" BU_SG_REL_ FICM_FD SG_ 754 FuelSysEPTRdyOvrdInvsn 5000;
BA_REL_ "GenSigTimeoutTime" BU_SG_REL_ FICM_FD SG_ 754 FuelSysEPTRdyOvrd 5000;
BA_REL_ "GenSigTimeoutTime" BU_SG_REL_ FICM_FD SG_ 754 DrAjr_CRP 5000;
BA_REL_ "GenSigTimeoutTime" BU_SG_REL_ FICM_FD SG_ 754 DrAjr_CRPV 5000;
BA_REL_ "GenSigTimeoutTime" BU_SG_REL_ FICM_FD SG_ 754 ECDErrResp 5000;
BA_REL_ "GenSigTimeoutTime" BU_SG_REL_ FICM_FD SG_ 767 PADispInfo_1 1000;
BA_REL_ "GenSigTimeoutTime" BU_SG_REL_ FICM_FD SG_ 767 PADispInfo_2 1000;
BA_REL_ "GenSigTimeoutTime" BU_SG_REL_ FICM_FD SG_ 767 ParkingInSetReqFdbck 1000;
BA_REL_ "GenSigTimeoutTime" BU_SG_REL_ FICM_FD SG_ 767 ParkingStReqFdbck 1000;
BA_REL_ "GenSigTimeoutTime" BU_SG_REL_ FICM_FD SG_ 767 ParkingContinueReqFdbck 1000;
BA_REL_ "GenSigTimeoutTime" BU_SG_REL_ FICM_FD SG_ 767 ParkingExitReqFdbck 1000;
BA_REL_ "GenSigTimeoutTime" BU_SG_REL_ FICM_FD SG_ 767 ParkingOutSetReqFdbck 1000;
BA_REL_ "GenSigTimeoutTime" BU_SG_REL_ FICM_FD SG_ 767 ParkingDragReqFdbck 1000;
BA_REL_ "GenSigTimeoutTime" BU_SG_REL_ FICM_FD SG_ 767 ParkingOutDircnReqFdbck 1000;
BA_REL_ "GenSigTimeoutTime" BU_SG_REL_ FICM_FD SG_ 767 ParkingDragSlotTypReqFdbck 1000;
BA_REL_ "GenSigTimeoutTime" BU_SG_REL_ FICM_FD SG_ 767 TurnAVMReqFdbck 1000;
BA_REL_ "GenSigTimeoutTime" BU_SG_REL_ FICM_FD SG_ 767 TrackLineSwReqFdbck 1000;
BA_REL_ "GenSigTimeoutTime" BU_SG_REL_ FICM_FD SG_ 767 UnderPerspectiveSwReqFdbck 1000;
BA_REL_ "GenSigTimeoutTime" BU_SG_REL_ FICM_FD SG_ 767 NarrowPathReqFdbck 1000;
BA_REL_ "GenSigTimeoutTime" BU_SG_REL_ FICM_FD SG_ 769 TrlerAttchSts 2000;
BA_REL_ "GenSigTimeoutTime" BU_SG_REL_ FICM_FD SG_ 775 BMSOfbdChrgSpRsn 1000;
BA_REL_ "GenSigTimeoutTime" BU_SG_REL_ FICM_FD SG_ 775 BMSDsChrgSpRsn 1000;
BA_REL_ "GenSigTimeoutTime" BU_SG_REL_ FICM_FD SG_ 775 DisChrgngRmnngTimeV 1000;
BA_REL_ "GenSigTimeoutTime" BU_SG_REL_ FICM_FD SG_ 775 DisChrgngRmnngTime 1000;
BA_REL_ "GenSigTimeoutTime" BU_SG_REL_ FICM_FD SG_ 775 BMSPTCHeatReqDspCmd 1000;
BA_REL_ "GenSigTimeoutTime" BU_SG_REL_ FICM_FD SG_ 775 BMSPTCHeatResp 1000;
BA_REL_ "GenSigTimeoutTime" BU_SG_REL_ FICM_FD SG_ 775 BMSDsChrgCtrlDspCmd 1000;
BA_REL_ "GenSigTimeoutTime" BU_SG_REL_ FICM_FD SG_ 775 BMSOnRutWarmSwDsp 1000;
BA_REL_ "GenSigTimeoutTime" BU_SG_REL_ FICM_FD SG_ 775 DschrgTrgtSOCDspCmdExt 1000;
BA_REL_ "GenSigTimeoutTime" BU_SG_REL_ FICM_FD SG_ 776 FrtPsngAirbagOnOffReqFdbck 1000;
BA_REL_ "GenSigTimeoutTime" BU_SG_REL_ FICM_FD SG_ 776 SBRSetReqFdbck_R 1000;
BA_REL_ "GenSigTimeoutTime" BU_SG_REL_ FICM_FD SG_ 788 BMSChrgOtptCrntReq 1000;
BA_REL_ "GenSigTimeoutTime" BU_SG_REL_ FICM_FD SG_ 788 BMSChrgSpRsn 1000;
BA_REL_ "GenSigTimeoutTime" BU_SG_REL_ FICM_FD SG_ 788 BMSChrgOtptCrntReqV 1000;
BA_REL_ "GenSigTimeoutTime" BU_SG_REL_ FICM_FD SG_ 788 BMSChrgCtrlResp 1000;
BA_REL_ "GenSigTimeoutTime" BU_SG_REL_ FICM_FD SG_ 788 BMSChrgCtrlDspCmd 1000;
BA_REL_ "GenSigTimeoutTime" BU_SG_REL_ FICM_FD SG_ 788 BMSChrgSts 1000;
BA_REL_ "GenSigTimeoutTime" BU_SG_REL_ FICM_FD SG_ 794 CCUOnbdChrgrPlugOn 1000;
BA_REL_ "GenSigTimeoutTime" BU_SG_REL_ FICM_FD SG_ 794 CCUDsChrgVolDsp 1000;
BA_REL_ "GenSigTimeoutTime" BU_SG_REL_ FICM_FD SG_ 794 CCUDsChrgFreqDsp 1000;
BA_REL_ "GenSigTimeoutTime" BU_SG_REL_ FICM_FD SG_ 794 OnBdChrgrAltrCrntInptCrnt 1000;
BA_REL_ "GenSigTimeoutTime" BU_SG_REL_ FICM_FD SG_ 794 OnBdChrgrAltrCrntInptVol 1000;
BA_REL_ "GenSigTimeoutTime" BU_SG_REL_ FICM_FD SG_ 794 CCUEleccLckCtrlDspCmd 1000;
BA_REL_ "GenSigTimeoutTime" BU_SG_REL_ FICM_FD SG_ 794 OnBdChrgrCtrlPilotPWMSts 1000;
BA_REL_ "GenSigTimeoutTime" BU_SG_REL_ FICM_FD SG_ 794 OnBdChrgrCtrlPilotPWMDuty 1000;
BA_REL_ "GenSigTimeoutTime" BU_SG_REL_ FICM_FD SG_ 800 MemFdbk_PR 2000;
BA_REL_ "GenSigTimeoutTime" BU_SG_REL_ FICM_FD SG_ 800 MemClrFdbk_PR 2000;
BA_REL_ "GenSigTimeoutTime" BU_SG_REL_ FICM_FD SG_ 803 EngCltTmpV 2000;
BA_REL_ "GenSigTimeoutTime" BU_SG_REL_ FICM_FD SG_ 803 EngCltTmp 2000;
BA_REL_ "GenSigTimeoutTime" BU_SG_REL_ FICM_FD SG_ 803 SpStButtonSts 2000;
BA_REL_ "GenSigTimeoutTime" BU_SG_REL_ FICM_FD SG_ 811 FOTAModReq 1000;
BA_REL_ "GenSigTimeoutTime" BU_SG_REL_ FICM_FD SG_ 813 EmgcCallTrigd_TBOX 1000;
BA_REL_ "GenSigTimeoutTime" BU_SG_REL_ FICM_FD SG_ 813 CldDiagGPSPermsnSwSts 1000;
BA_REL_ "GenSigTimeoutTime" BU_SG_REL_ FICM_FD SG_ 813 VehPosPermsnSwSts 1000;
BA_REL_ "GenSigTimeoutTime" BU_SG_REL_ FICM_FD SG_ 813 PrvyPlyVrsnV 1000;
BA_REL_ "GenSigTimeoutTime" BU_SG_REL_ FICM_FD SG_ 813 PrvyPlyVrsn 1000;
BA_REL_ "GenSigTimeoutTime" BU_SG_REL_ FICM_FD SG_ 814 iCGMFctryDeftSetFnsh 1000;
BA_REL_ "GenSigTimeoutTime" BU_SG_REL_ FICM_FD SG_ 814 DrvMdRcmdnFnSetReqFdbck 1000;
BA_REL_ "GenSigTimeoutTime" BU_SG_REL_ FICM_FD SG_ 814 DrvMdRcmdnDispReq 1000;
BA_REL_ "GenSigTimeoutTime" BU_SG_REL_ FICM_FD SG_ 814 DrvMdRcmdnDispInfo 1000;
BA_REL_ "GenSigTimeoutTime" BU_SG_REL_ FICM_FD SG_ 817 FrtWprOprtSts 2000;
BA_REL_ "GenSigTimeoutTime" BU_SG_REL_ FICM_FD SG_ 817 WprSnstvtySts 2000;
BA_REL_ "GenSigTimeoutTime" BU_SG_REL_ FICM_FD SG_ 817 FrtWprSw 2000;
BA_REL_ "GenSigTimeoutTime" BU_SG_REL_ FICM_FD SG_ 817 RrWprOprtSts 2000;
BA_REL_ "GenSigTimeoutTime" BU_SG_REL_ FICM_FD SG_ 817 RvsGearActvtRrWprSts 2000;
BA_REL_ "GenSigTimeoutTime" BU_SG_REL_ FICM_FD SG_ 818 HiBmSts_L 2000;
BA_REL_ "GenSigTimeoutTime" BU_SG_REL_ FICM_FD SG_ 818 HiBmSts_R 2000;
BA_REL_ "GenSigTimeoutTime" BU_SG_REL_ FICM_FD SG_ 818 FrtFogLmpSts 2000;
BA_REL_ "GenSigTimeoutTime" BU_SG_REL_ FICM_FD SG_ 818 LoBmSts_L 2000;
BA_REL_ "GenSigTimeoutTime" BU_SG_REL_ FICM_FD SG_ 818 LoBmSts_R 2000;
BA_REL_ "GenSigTimeoutTime" BU_SG_REL_ FICM_FD SG_ 818 RrFogLmpSts 2000;
BA_REL_ "GenSigTimeoutTime" BU_SG_REL_ FICM_FD SG_ 818 RrFogLmpDspReq 2000;
BA_REL_ "GenSigTimeoutTime" BU_SG_REL_ FICM_FD SG_ 818 FrtFogLmpDspReq 2000;
BA_REL_ "GenSigTimeoutTime" BU_SG_REL_ FICM_FD SG_ 818 ChrIndFedbck 2000;
BA_REL_ "GenSigTimeoutTime" BU_SG_REL_ FICM_FD SG_ 818 HdLmpAdjSts 2000;
BA_REL_ "GenSigTimeoutTime" BU_SG_REL_ FICM_FD SG_ 818 LogoLgtOnPGearSetFedbck 2000;
BA_REL_ "GenSigTimeoutTime" BU_SG_REL_ FICM_FD SG_ 818 BrkLmpSts 2000;
BA_REL_ "GenSigTimeoutTime" BU_SG_REL_ FICM_FD SG_ 818 RvsGr 2000;
BA_REL_ "GenSigTimeoutTime" BU_SG_REL_ FICM_FD SG_ 818 VisionMdSts 2000;
BA_REL_ "GenSigTimeoutTime" BU_SG_REL_ FICM_FD SG_ 818 HdLmpOffSwEnbl 2000;
BA_REL_ "GenSigTimeoutTime" BU_SG_REL_ FICM_FD SG_ 819 CTDSts 2000;
BA_REL_ "GenSigTimeoutTime" BU_SG_REL_ FICM_FD SG_ 819 VehLckDrvSts 2000;
BA_REL_ "GenSigTimeoutTime" BU_SG_REL_ FICM_FD SG_ 819 HeatFrtWndsldSts 2000;
BA_REL_ "GenSigTimeoutTime" BU_SG_REL_ FICM_FD SG_ 819 MemCalOtFlRsn 2000;
BA_REL_ "GenSigTimeoutTime" BU_SG_REL_ FICM_FD SG_ 819 MemSts_Set1 2000;
BA_REL_ "GenSigTimeoutTime" BU_SG_REL_ FICM_FD SG_ 819 MemSts_Set2 2000;
BA_REL_ "GenSigTimeoutTime" BU_SG_REL_ FICM_FD SG_ 819 MemSts_Set3 2000;
BA_REL_ "GenSigTimeoutTime" BU_SG_REL_ FICM_FD SG_ 820 TrnLmpSw 2000;
BA_REL_ "GenSigTimeoutTime" BU_SG_REL_ FICM_FD SG_ 820 TrnLmpSts_L 2000;
BA_REL_ "GenSigTimeoutTime" BU_SG_REL_ FICM_FD SG_ 820 TrnLmpSts_R 2000;
BA_REL_ "GenSigTimeoutTime" BU_SG_REL_ FICM_FD SG_ 820 AprchngLghtSts 2000;
BA_REL_ "GenSigTimeoutTime" BU_SG_REL_ FICM_FD SG_ 820 PosLmpSts_F 2000;
BA_REL_ "GenSigTimeoutTime" BU_SG_REL_ FICM_FD SG_ 820 PosLmpSts_R 2000;
BA_REL_ "GenSigTimeoutTime" BU_SG_REL_ FICM_FD SG_ 820 DRLSts_L 2000;
BA_REL_ "GenSigTimeoutTime" BU_SG_REL_ FICM_FD SG_ 820 DRLSts_R 2000;
BA_REL_ "GenSigTimeoutTime" BU_SG_REL_ FICM_FD SG_ 820 HdLmpOprtSts 2000;
BA_REL_ "GenSigTimeoutTime" BU_SG_REL_ FICM_FD SG_ 820 FogLmpOprtSts 2000;
BA_REL_ "GenSigTimeoutTime" BU_SG_REL_ FICM_FD SG_ 820 FrtFogLmpOprtSts 2000;
BA_REL_ "GenSigTimeoutTime" BU_SG_REL_ FICM_FD SG_ 820 PckLgtOprtSts 2000;
BA_REL_ "GenSigTimeoutTime" BU_SG_REL_ FICM_FD SG_ 823 Humidity 2000;
BA_REL_ "GenSigTimeoutTime" BU_SG_REL_ FICM_FD SG_ 834 CldrYr_Master 2000;
BA_REL_ "GenSigTimeoutTime" BU_SG_REL_ FICM_FD SG_ 834 CldrMth_Master 2000;
BA_REL_ "GenSigTimeoutTime" BU_SG_REL_ FICM_FD SG_ 834 CldrDay_Master 2000;
BA_REL_ "GenSigTimeoutTime" BU_SG_REL_ FICM_FD SG_ 834 HrofDay_Master 2000;
BA_REL_ "GenSigTimeoutTime" BU_SG_REL_ FICM_FD SG_ 834 MinofHr_Master 2000;
BA_REL_ "GenSigTimeoutTime" BU_SG_REL_ FICM_FD SG_ 834 CldV_Master 2000;
BA_REL_ "GenSigTimeoutTime" BU_SG_REL_ FICM_FD SG_ 834 DayV_Master 2000;
BA_REL_ "GenSigTimeoutTime" BU_SG_REL_ FICM_FD SG_ 834 SecofMin_Master 2000;
BA_REL_ "GenSigTimeoutTime" BU_SG_REL_ FICM_FD SG_ 834 ZnCstmSts 2000;
BA_REL_ "GenSigTimeoutTime" BU_SG_REL_ FICM_FD SG_ 834 TmZoneV_Master 2000;
BA_REL_ "GenSigTimeoutTime" BU_SG_REL_ FICM_FD SG_ 834 TmZone_Master 2000;
BA_REL_ "GenSigTimeoutTime" BU_SG_REL_ FICM_FD SG_ 837 SRFOprtSts 2000;
BA_REL_ "GenSigTimeoutTime" BU_SG_REL_ FICM_FD SG_ 837 PSROprtSts 2000;
BA_REL_ "GenSigTimeoutTime" BU_SG_REL_ FICM_FD SG_ 837 SRFRgn 2000;
BA_REL_ "GenSigTimeoutTime" BU_SG_REL_ FICM_FD SG_ 837 PSRRgn 2000;
BA_REL_ "GenSigTimeoutTime" BU_SG_REL_ FICM_FD SG_ 837 SRFPos 2000;
BA_REL_ "GenSigTimeoutTime" BU_SG_REL_ FICM_FD SG_ 837 PSRPstn 2000;
BA_REL_ "GenSigTimeoutTime" BU_SG_REL_ FICM_FD SG_ 837 PSSDPos 2000;
BA_REL_ "GenSigTimeoutTime" BU_SG_REL_ FICM_FD SG_ 837 PSSDOprtSts 2000;
BA_REL_ "GenSigTimeoutTime" BU_SG_REL_ FICM_FD SG_ 837 PSSDRgn 2000;
BA_REL_ "GenSigTimeoutTime" BU_SG_REL_ FICM_FD SG_ 838 VehSoundGenerateFeedback 2000;
BA_REL_ "GenSigTimeoutTime" BU_SG_REL_ FICM_FD SG_ 838 AVASSts 2000;
BA_REL_ "GenSigTimeoutTime" BU_SG_REL_ FICM_FD SG_ 846 IntLgtOprtMd 2000;
BA_REL_ "GenSigTimeoutTime" BU_SG_REL_ FICM_FD SG_ 846 IntWlcmLampSetFedbck 2000;
BA_REL_ "GenSigTimeoutTime" BU_SG_REL_ FICM_FD SG_ 846 RfLmp5Stts 2000;
BA_REL_ "GenSigTimeoutTime" BU_SG_REL_ FICM_FD SG_ 846 RfLmp6Stts 2000;
BA_REL_ "GenSigTimeoutTime" BU_SG_REL_ FICM_FD SG_ 846 ALCRunMdSts 2000;
BA_REL_ "GenSigTimeoutTime" BU_SG_REL_ FICM_FD SG_ 846 BkltLumTrgt 2000;
BA_REL_ "GenSigTimeoutTime" BU_SG_REL_ FICM_FD SG_ 846 BkltLum 2000;
BA_REL_ "GenSigTimeoutTime" BU_SG_REL_ FICM_FD SG_ 846 BkltSts 2000;
BA_REL_ "GenSigTimeoutTime" BU_SG_REL_ FICM_FD SG_ 846 RfLmp1Stts 2000;
BA_REL_ "GenSigTimeoutTime" BU_SG_REL_ FICM_FD SG_ 846 RfLmp2Stts 2000;
BA_REL_ "GenSigTimeoutTime" BU_SG_REL_ FICM_FD SG_ 846 RfLmp3Stts 2000;
BA_REL_ "GenSigTimeoutTime" BU_SG_REL_ FICM_FD SG_ 846 RfLmp4Stts 2000;
BA_REL_ "GenSigTimeoutTime" BU_SG_REL_ FICM_FD SG_ 846 ALCColLvlSts 2000;
BA_REL_ "GenSigTimeoutTime" BU_SG_REL_ FICM_FD SG_ 846 ALCLumLvlSts 2000;
BA_REL_ "GenSigTimeoutTime" BU_SG_REL_ FICM_FD SG_ 846 ALCSts 2000;
BA_REL_ "GenSigTimeoutTime" BU_SG_REL_ FICM_FD SG_ 846 ALDrFdbkSts 2000;
BA_REL_ "GenSigTimeoutTime" BU_SG_REL_ FICM_FD SG_ 846 ALCallRmdSts 2000;
BA_REL_ "GenSigTimeoutTime" BU_SG_REL_ FICM_FD SG_ 846 ALStartFdbkSts 2000;
BA_REL_ "GenSigTimeoutTime" BU_SG_REL_ FICM_FD SG_ 846 ALRhythmSts 2000;
BA_REL_ "GenSigTimeoutTime" BU_SG_REL_ FICM_FD SG_ 848 StSysCstmSetFdbk 5000;
BA_REL_ "GenSigTimeoutTime" BU_SG_REL_ FICM_FD SG_ 848 StSysLnkgSts_Dwdlr_R 5000;
BA_REL_ "GenSigTimeoutTime" BU_SG_REL_ FICM_FD SG_ 848 StSysSftyAlrm 5000;
BA_REL_ "GenSigTimeoutTime" BU_SG_REL_ FICM_FD SG_ 848 StSysLnkgSts_Thrn 5000;
BA_REL_ "GenSigTimeoutTime" BU_SG_REL_ FICM_FD SG_ 848 StSysLnkgSts_Dwdlr_L 5000;
BA_REL_ "GenSigTimeoutTime" BU_SG_REL_ FICM_FD SG_ 848 StSysLnkgSts_FstCls 5000;
BA_REL_ "GenSigTimeoutTime" BU_SG_REL_ FICM_FD SG_ 848 StSysLnkgSts_Strg 5000;
BA_REL_ "GenSigTimeoutTime" BU_SG_REL_ FICM_FD SG_ 848 StSysLnkgSts_Bbs 5000;
BA_REL_ "GenSigTimeoutTime" BU_SG_REL_ FICM_FD SG_ 848 StSysLnkgSts_Cstm 5000;
BA_REL_ "GenSigTimeoutTime" BU_SG_REL_ FICM_FD SG_ 848 StSysLnkgEnbl_Thrn 5000;
BA_REL_ "GenSigTimeoutTime" BU_SG_REL_ FICM_FD SG_ 848 StSysLnkgEnbl_Dwdlr_L 5000;
BA_REL_ "GenSigTimeoutTime" BU_SG_REL_ FICM_FD SG_ 848 StSysLnkgEnbl_FstCls 5000;
BA_REL_ "GenSigTimeoutTime" BU_SG_REL_ FICM_FD SG_ 848 StSysLnkgEnbl_Strg 5000;
BA_REL_ "GenSigTimeoutTime" BU_SG_REL_ FICM_FD SG_ 848 StSysLnkgEnbl_Bbs 5000;
BA_REL_ "GenSigTimeoutTime" BU_SG_REL_ FICM_FD SG_ 848 StSysLnkgEnbl_Cstm 5000;
BA_REL_ "GenSigTimeoutTime" BU_SG_REL_ FICM_FD SG_ 848 StSysLnkgSts_Rset 5000;
BA_REL_ "GenSigTimeoutTime" BU_SG_REL_ FICM_FD SG_ 848 StSysLnkgOprtSts 5000;
BA_REL_ "GenSigTimeoutTime" BU_SG_REL_ FICM_FD SG_ 848 MemCalOtExctSts_DR 5000;
BA_REL_ "GenSigTimeoutTime" BU_SG_REL_ FICM_FD SG_ 848 IntltWlcmSts 5000;
BA_REL_ "GenSigTimeoutTime" BU_SG_REL_ FICM_FD SG_ 848 LockVehRcvrSts 5000;
BA_REL_ "GenSigTimeoutTime" BU_SG_REL_ FICM_FD SG_ 848 StSysLnkgEnbl_Dwdlr_R 5000;
BA_REL_ "GenSigTimeoutTime" BU_SG_REL_ FICM_FD SG_ 851 TrOilTempV 5000;
BA_REL_ "GenSigTimeoutTime" BU_SG_REL_ FICM_FD SG_ 851 TrOilTemp 5000;
BA_REL_ "GenSigTimeoutTime" BU_SG_REL_ FICM_FD SG_ 851 TrOilTempHighTrqLimInd 5000;
BA_REL_ "GenSigTimeoutTime" BU_SG_REL_ FICM_FD SG_ 863 MrrFldSts 2000;
BA_REL_ "GenSigTimeoutTime" BU_SG_REL_ FICM_FD SG_ 864 BarPrsAbsV 5000;
BA_REL_ "GenSigTimeoutTime" BU_SG_REL_ FICM_FD SG_ 864 BarPrsAbs 5000;
BA_REL_ "GenSigTimeoutTime" BU_SG_REL_ FICM_FD SG_ 890 StHtEnbl 5000;
BA_REL_ "GenSigTimeoutTime" BU_SG_REL_ FICM_FD SG_ 897 TlgtOprt 5000;
BA_REL_ "GenSigTimeoutTime" BU_SG_REL_ FICM_FD SG_ 897 TlgtPosSts 5000;
BA_REL_ "GenSigTimeoutTime" BU_SG_REL_ FICM_FD SG_ 897 TlgtPos 5000;
BA_REL_ "GenSigTimeoutTime" BU_SG_REL_ FICM_FD SG_ 897 TlgtOprtMd 5000;
BA_REL_ "GenSigTimeoutTime" BU_SG_REL_ FICM_FD SG_ 897 TlgtAbsAlrm 5000;
BA_REL_ "GenSigTimeoutTime" BU_SG_REL_ FICM_FD SG_ 897 TlgtOpnPos 5000;
BA_REL_ "GenSigTimeoutTime" BU_SG_REL_ FICM_FD SG_ 898 SmrtWlcmVcReq 5000;
BA_REL_ "GenSigTimeoutTime" BU_SG_REL_ FICM_FD SG_ 898 SmrtFrwllVcReq 5000;
BA_REL_ "GenSigTimeoutTime" BU_SG_REL_ FICM_FD SG_ 916 EPTRgtnLvl 1000;
BA_REL_ "GenSigTimeoutTime" BU_SG_REL_ FICM_FD SG_ 916 HybVehSysStsInd 1000;
BA_REL_ "GenSigTimeoutTime" BU_SG_REL_ FICM_FD SG_ 916 IntgltBatEngyManmtDrvModHCUDisp 1000;
BA_REL_ "GenSigTimeoutTime" BU_SG_REL_ FICM_FD SG_ 916 ElecVehSysMd 1000;
BA_REL_ "GenSigTimeoutTime" BU_SG_REL_ FICM_FD SG_ 916 HybDrvrItndHVBatSOCAch 1000;
VAL_ 741 RemainDrvngDist 4095 "Invalid" ;
VAL_ 742 AvgElectricCsump 1023 "invalid" ;
VAL_ 742 IPK1KmOrMileAvgElecEnergyCsump 1023 "invalid" ;
VAL_ 746 AVMXGestureSpd 255 "invalid" ;
VAL_ 746 AVMYGestureSpd 255 "invalid" ;
VAL_ 746 RngSndVolmStepReq 0 "VoL_Step0" 1 "VoL_Step1" 2 "VoL_Step2" 3 "VoL_Step3" 4 "VoL_Step4" 5 "VoL_Step5" 6 "VoL_Step6" 7 "VoL_Step7" 8 "VoL_Step8" 9 "VoL_Step9" 10 "VoL_Step10" 11 "VoL_Step11" 12 "VoL_Step12" 13 "VoL_Step13" 14 "VoL_Step14" 15 "VoL_Step15" 16 "VoL_Step16" 17 "VoL_Step17" 18 "VoL_Step18" 19 "VoL_Step19" 20 "VoL_Step20" 21 "VoL_Step21" 22 "VoL_Step22" 23 "VoL_Step23" 24 "VoL_Step24" 25 "VoL_Step25" 26 "VoL_Step26" 27 "VoL_Step27" 28 "VoL_Step28" 29 "VoL_Step29" 30 "VoL_Step30" 31 "VoL_Step31" 32 "VoL_Step32" ;
VAL_ 746 RngSndVolmStepReqV 0 "Valid" 1 "Invalid" ;
VAL_ 747 CustzEqlzrBand9Dsp 0 "CustzEqlzrBand1Dsp_0_12dB" 1 "CustzEqlzrBand1Dsp_1_11dB" 2 "CustzEqlzrBand1Dsp_2_10dB" 3 "CustzEqlzrBand1Dsp_3_9dB" 4 "CustzEqlzrBand1Dsp_4_8dB" 5 "CustzEqlzrBand1Dsp_5_7dB" 6 "CustzEqlzrBand1Dsp_6_6dB" 7 "CustzEqlzrBand1Dsp_7_5dB" 8 "CustzEqlzrBand1Dsp_8_4dB" 9 "CustzEqlzrBand1Dsp_9_3dB" 10 "CustzEqlzrBand1Dsp_A_2dB" 11 "CustzEqlzrBand1Dsp_B_1dB" 12 "CustzEqlzrBand1Dsp_C_0dB" 13 "CustzEqlzrBand1Dsp_D_1dB" 14 "CustzEqlzrBand1Dsp_E_2dB" 15 "CustzEqlzrBand1Dsp_F_3dB" 16 "CustzEqlzrBand1Dsp_10_4dB" 17 "CustzEqlzrBand1Dsp_11_5dB" 18 "CustzEqlzrBand1Dsp_12_6dB" 19 "CustzEqlzrBand1Dsp_13_7dB" 20 "CustzEqlzrBand1Dsp_14_8dB" 21 "CustzEqlzrBand1Dsp_15_9dB" 22 "CustzEqlzrBand1Dsp_16_10dB" 23 "CustzEqlzrBand1Dsp_17_11dB" 24 "CustzEqlzrBand1Dsp_18_12dB" ;
VAL_ 747 CustzEqlzrBand10Dsp 0 "CustzEqlzrBand1Dsp_0_12dB" 1 "CustzEqlzrBand1Dsp_1_11dB" 2 "CustzEqlzrBand1Dsp_2_10dB" 3 "CustzEqlzrBand1Dsp_3_9dB" 4 "CustzEqlzrBand1Dsp_4_8dB" 5 "CustzEqlzrBand1Dsp_5_7dB" 6 "CustzEqlzrBand1Dsp_6_6dB" 7 "CustzEqlzrBand1Dsp_7_5dB" 8 "CustzEqlzrBand1Dsp_8_4dB" 9 "CustzEqlzrBand1Dsp_9_3dB" 10 "CustzEqlzrBand1Dsp_A_2dB" 11 "CustzEqlzrBand1Dsp_B_1dB" 12 "CustzEqlzrBand1Dsp_C_0dB" 13 "CustzEqlzrBand1Dsp_D_1dB" 14 "CustzEqlzrBand1Dsp_E_2dB" 15 "CustzEqlzrBand1Dsp_F_3dB" 16 "CustzEqlzrBand1Dsp_10_4dB" 17 "CustzEqlzrBand1Dsp_11_5dB" 18 "CustzEqlzrBand1Dsp_12_6dB" 19 "CustzEqlzrBand1Dsp_13_7dB" 20 "CustzEqlzrBand1Dsp_14_8dB" 21 "CustzEqlzrBand1Dsp_15_9dB" 22 "CustzEqlzrBand1Dsp_16_10dB" 23 "CustzEqlzrBand1Dsp_17_11dB" 24 "CustzEqlzrBand1Dsp_18_12dB" ;
VAL_ 747 CustzEqlzrBand11Dsp 0 "CustzEqlzrBand1Dsp_0_12dB" 1 "CustzEqlzrBand1Dsp_1_11dB" 2 "CustzEqlzrBand1Dsp_2_10dB" 3 "CustzEqlzrBand1Dsp_3_9dB" 4 "CustzEqlzrBand1Dsp_4_8dB" 5 "CustzEqlzrBand1Dsp_5_7dB" 6 "CustzEqlzrBand1Dsp_6_6dB" 7 "CustzEqlzrBand1Dsp_7_5dB" 8 "CustzEqlzrBand1Dsp_8_4dB" 9 "CustzEqlzrBand1Dsp_9_3dB" 10 "CustzEqlzrBand1Dsp_A_2dB" 11 "CustzEqlzrBand1Dsp_B_1dB" 12 "CustzEqlzrBand1Dsp_C_0dB" 13 "CustzEqlzrBand1Dsp_D_1dB" 14 "CustzEqlzrBand1Dsp_E_2dB" 15 "CustzEqlzrBand1Dsp_F_3dB" 16 "CustzEqlzrBand1Dsp_10_4dB" 17 "CustzEqlzrBand1Dsp_11_5dB" 18 "CustzEqlzrBand1Dsp_12_6dB" 19 "CustzEqlzrBand1Dsp_13_7dB" 20 "CustzEqlzrBand1Dsp_14_8dB" 21 "CustzEqlzrBand1Dsp_15_9dB" 22 "CustzEqlzrBand1Dsp_16_10dB" 23 "CustzEqlzrBand1Dsp_17_11dB" 24 "CustzEqlzrBand1Dsp_18_12dB" ;
VAL_ 747 CustzEqlzrBand12Dsp 0 "CustzEqlzrBand1Dsp_0_12dB" 1 "CustzEqlzrBand1Dsp_1_11dB" 2 "CustzEqlzrBand1Dsp_2_10dB" 3 "CustzEqlzrBand1Dsp_3_9dB" 4 "CustzEqlzrBand1Dsp_4_8dB" 5 "CustzEqlzrBand1Dsp_5_7dB" 6 "CustzEqlzrBand1Dsp_6_6dB" 7 "CustzEqlzrBand1Dsp_7_5dB" 8 "CustzEqlzrBand1Dsp_8_4dB" 9 "CustzEqlzrBand1Dsp_9_3dB" 10 "CustzEqlzrBand1Dsp_A_2dB" 11 "CustzEqlzrBand1Dsp_B_1dB" 12 "CustzEqlzrBand1Dsp_C_0dB" 13 "CustzEqlzrBand1Dsp_D_1dB" 14 "CustzEqlzrBand1Dsp_E_2dB" 15 "CustzEqlzrBand1Dsp_F_3dB" 16 "CustzEqlzrBand1Dsp_10_4dB" 17 "CustzEqlzrBand1Dsp_11_5dB" 18 "CustzEqlzrBand1Dsp_12_6dB" 19 "CustzEqlzrBand1Dsp_13_7dB" 20 "CustzEqlzrBand1Dsp_14_8dB" 21 "CustzEqlzrBand1Dsp_15_9dB" 22 "CustzEqlzrBand1Dsp_16_10dB" 23 "CustzEqlzrBand1Dsp_17_11dB" 24 "CustzEqlzrBand1Dsp_18_12dB" ;
VAL_ 747 CustzEqlzrBand13Dsp 0 "CustzEqlzrBand1Dsp_0_12dB" 1 "CustzEqlzrBand1Dsp_1_11dB" 2 "CustzEqlzrBand1Dsp_2_10dB" 3 "CustzEqlzrBand1Dsp_3_9dB" 4 "CustzEqlzrBand1Dsp_4_8dB" 5 "CustzEqlzrBand1Dsp_5_7dB" 6 "CustzEqlzrBand1Dsp_6_6dB" 7 "CustzEqlzrBand1Dsp_7_5dB" 8 "CustzEqlzrBand1Dsp_8_4dB" 9 "CustzEqlzrBand1Dsp_9_3dB" 10 "CustzEqlzrBand1Dsp_A_2dB" 11 "CustzEqlzrBand1Dsp_B_1dB" 12 "CustzEqlzrBand1Dsp_C_0dB" 13 "CustzEqlzrBand1Dsp_D_1dB" 14 "CustzEqlzrBand1Dsp_E_2dB" 15 "CustzEqlzrBand1Dsp_F_3dB" 16 "CustzEqlzrBand1Dsp_10_4dB" 17 "CustzEqlzrBand1Dsp_11_5dB" 18 "CustzEqlzrBand1Dsp_12_6dB" 19 "CustzEqlzrBand1Dsp_13_7dB" 20 "CustzEqlzrBand1Dsp_14_8dB" 21 "CustzEqlzrBand1Dsp_15_9dB" 22 "CustzEqlzrBand1Dsp_16_10dB" 23 "CustzEqlzrBand1Dsp_17_11dB" 24 "CustzEqlzrBand1Dsp_18_12dB" ;
VAL_ 747 CustzEqlzrBand14Dsp 0 "CustzEqlzrBand1Dsp_0_12dB" 1 "CustzEqlzrBand1Dsp_1_11dB" 2 "CustzEqlzrBand1Dsp_2_10dB" 3 "CustzEqlzrBand1Dsp_3_9dB" 4 "CustzEqlzrBand1Dsp_4_8dB" 5 "CustzEqlzrBand1Dsp_5_7dB" 6 "CustzEqlzrBand1Dsp_6_6dB" 7 "CustzEqlzrBand1Dsp_7_5dB" 8 "CustzEqlzrBand1Dsp_8_4dB" 9 "CustzEqlzrBand1Dsp_9_3dB" 10 "CustzEqlzrBand1Dsp_A_2dB" 11 "CustzEqlzrBand1Dsp_B_1dB" 12 "CustzEqlzrBand1Dsp_C_0dB" 13 "CustzEqlzrBand1Dsp_D_1dB" 14 "CustzEqlzrBand1Dsp_E_2dB" 15 "CustzEqlzrBand1Dsp_F_3dB" 16 "CustzEqlzrBand1Dsp_10_4dB" 17 "CustzEqlzrBand1Dsp_11_5dB" 18 "CustzEqlzrBand1Dsp_12_6dB" 19 "CustzEqlzrBand1Dsp_13_7dB" 20 "CustzEqlzrBand1Dsp_14_8dB" 21 "CustzEqlzrBand1Dsp_15_9dB" 22 "CustzEqlzrBand1Dsp_16_10dB" 23 "CustzEqlzrBand1Dsp_17_11dB" 24 "CustzEqlzrBand1Dsp_18_12dB" ;
VAL_ 747 CustzEqlzrBand15Dsp 0 "CustzEqlzrBand1Dsp_0_12dB" 1 "CustzEqlzrBand1Dsp_1_11dB" 2 "CustzEqlzrBand1Dsp_2_10dB" 3 "CustzEqlzrBand1Dsp_3_9dB" 4 "CustzEqlzrBand1Dsp_4_8dB" 5 "CustzEqlzrBand1Dsp_5_7dB" 6 "CustzEqlzrBand1Dsp_6_6dB" 7 "CustzEqlzrBand1Dsp_7_5dB" 8 "CustzEqlzrBand1Dsp_8_4dB" 9 "CustzEqlzrBand1Dsp_9_3dB" 10 "CustzEqlzrBand1Dsp_A_2dB" 11 "CustzEqlzrBand1Dsp_B_1dB" 12 "CustzEqlzrBand1Dsp_C_0dB" 13 "CustzEqlzrBand1Dsp_D_1dB" 14 "CustzEqlzrBand1Dsp_E_2dB" 15 "CustzEqlzrBand1Dsp_F_3dB" 16 "CustzEqlzrBand1Dsp_10_4dB" 17 "CustzEqlzrBand1Dsp_11_5dB" 18 "CustzEqlzrBand1Dsp_12_6dB" 19 "CustzEqlzrBand1Dsp_13_7dB" 20 "CustzEqlzrBand1Dsp_14_8dB" 21 "CustzEqlzrBand1Dsp_15_9dB" 22 "CustzEqlzrBand1Dsp_16_10dB" 23 "CustzEqlzrBand1Dsp_17_11dB" 24 "CustzEqlzrBand1Dsp_18_12dB" ;
VAL_ 747 CustzEqlzrBand16Dsp 0 "CustzEqlzrBand1Dsp_0_12dB" 1 "CustzEqlzrBand1Dsp_1_11dB" 2 "CustzEqlzrBand1Dsp_2_10dB" 3 "CustzEqlzrBand1Dsp_3_9dB" 4 "CustzEqlzrBand1Dsp_4_8dB" 5 "CustzEqlzrBand1Dsp_5_7dB" 6 "CustzEqlzrBand1Dsp_6_6dB" 7 "CustzEqlzrBand1Dsp_7_5dB" 8 "CustzEqlzrBand1Dsp_8_4dB" 9 "CustzEqlzrBand1Dsp_9_3dB" 10 "CustzEqlzrBand1Dsp_A_2dB" 11 "CustzEqlzrBand1Dsp_B_1dB" 12 "CustzEqlzrBand1Dsp_C_0dB" 13 "CustzEqlzrBand1Dsp_D_1dB" 14 "CustzEqlzrBand1Dsp_E_2dB" 15 "CustzEqlzrBand1Dsp_F_3dB" 16 "CustzEqlzrBand1Dsp_10_4dB" 17 "CustzEqlzrBand1Dsp_11_5dB" 18 "CustzEqlzrBand1Dsp_12_6dB" 19 "CustzEqlzrBand1Dsp_13_7dB" 20 "CustzEqlzrBand1Dsp_14_8dB" 21 "CustzEqlzrBand1Dsp_15_9dB" 22 "CustzEqlzrBand1Dsp_16_10dB" 23 "CustzEqlzrBand1Dsp_17_11dB" 24 "CustzEqlzrBand1Dsp_18_12dB" ;
VAL_ 748 CustzEqlzrBand9 0 "CustzEqlzrBand1Dsp_0_12dB" 1 "CustzEqlzrBand1Dsp_1_11dB" 2 "CustzEqlzrBand1Dsp_2_10dB" 3 "CustzEqlzrBand1Dsp_3_9dB" 4 "CustzEqlzrBand1Dsp_4_8dB" 5 "CustzEqlzrBand1Dsp_5_7dB" 6 "CustzEqlzrBand1Dsp_6_6dB" 7 "CustzEqlzrBand1Dsp_7_5dB" 8 "CustzEqlzrBand1Dsp_8_4dB" 9 "CustzEqlzrBand1Dsp_9_3dB" 10 "CustzEqlzrBand1Dsp_A_2dB" 11 "CustzEqlzrBand1Dsp_B_1dB" 12 "CustzEqlzrBand1Dsp_C_0dB" 13 "CustzEqlzrBand1Dsp_D_1dB" 14 "CustzEqlzrBand1Dsp_E_2dB" 15 "CustzEqlzrBand1Dsp_F_3dB" 16 "CustzEqlzrBand1Dsp_10_4dB" 17 "CustzEqlzrBand1Dsp_11_5dB" 18 "CustzEqlzrBand1Dsp_12_6dB" 19 "CustzEqlzrBand1Dsp_13_7dB" 20 "CustzEqlzrBand1Dsp_14_8dB" 21 "CustzEqlzrBand1Dsp_15_9dB" 22 "CustzEqlzrBand1Dsp_16_10dB" 23 "CustzEqlzrBand1Dsp_17_11dB" 24 "CustzEqlzrBand1Dsp_18_12dB" ;
VAL_ 748 CustzEqlzrBand10 0 "CustzEqlzrBand1Dsp_0_12dB" 1 "CustzEqlzrBand1Dsp_1_11dB" 2 "CustzEqlzrBand1Dsp_2_10dB" 3 "CustzEqlzrBand1Dsp_3_9dB" 4 "CustzEqlzrBand1Dsp_4_8dB" 5 "CustzEqlzrBand1Dsp_5_7dB" 6 "CustzEqlzrBand1Dsp_6_6dB" 7 "CustzEqlzrBand1Dsp_7_5dB" 8 "CustzEqlzrBand1Dsp_8_4dB" 9 "CustzEqlzrBand1Dsp_9_3dB" 10 "CustzEqlzrBand1Dsp_A_2dB" 11 "CustzEqlzrBand1Dsp_B_1dB" 12 "CustzEqlzrBand1Dsp_C_0dB" 13 "CustzEqlzrBand1Dsp_D_1dB" 14 "CustzEqlzrBand1Dsp_E_2dB" 15 "CustzEqlzrBand1Dsp_F_3dB" 16 "CustzEqlzrBand1Dsp_10_4dB" 17 "CustzEqlzrBand1Dsp_11_5dB" 18 "CustzEqlzrBand1Dsp_12_6dB" 19 "CustzEqlzrBand1Dsp_13_7dB" 20 "CustzEqlzrBand1Dsp_14_8dB" 21 "CustzEqlzrBand1Dsp_15_9dB" 22 "CustzEqlzrBand1Dsp_16_10dB" 23 "CustzEqlzrBand1Dsp_17_11dB" 24 "CustzEqlzrBand1Dsp_18_12dB" ;
VAL_ 748 CustzEqlzrBand11 0 "CustzEqlzrBand1Dsp_0_12dB" 1 "CustzEqlzrBand1Dsp_1_11dB" 2 "CustzEqlzrBand1Dsp_2_10dB" 3 "CustzEqlzrBand1Dsp_3_9dB" 4 "CustzEqlzrBand1Dsp_4_8dB" 5 "CustzEqlzrBand1Dsp_5_7dB" 6 "CustzEqlzrBand1Dsp_6_6dB" 7 "CustzEqlzrBand1Dsp_7_5dB" 8 "CustzEqlzrBand1Dsp_8_4dB" 9 "CustzEqlzrBand1Dsp_9_3dB" 10 "CustzEqlzrBand1Dsp_A_2dB" 11 "CustzEqlzrBand1Dsp_B_1dB" 12 "CustzEqlzrBand1Dsp_C_0dB" 13 "CustzEqlzrBand1Dsp_D_1dB" 14 "CustzEqlzrBand1Dsp_E_2dB" 15 "CustzEqlzrBand1Dsp_F_3dB" 16 "CustzEqlzrBand1Dsp_10_4dB" 17 "CustzEqlzrBand1Dsp_11_5dB" 18 "CustzEqlzrBand1Dsp_12_6dB" 19 "CustzEqlzrBand1Dsp_13_7dB" 20 "CustzEqlzrBand1Dsp_14_8dB" 21 "CustzEqlzrBand1Dsp_15_9dB" 22 "CustzEqlzrBand1Dsp_16_10dB" 23 "CustzEqlzrBand1Dsp_17_11dB" 24 "CustzEqlzrBand1Dsp_18_12dB" ;
VAL_ 748 CustzEqlzrBand12 0 "CustzEqlzrBand1Dsp_0_12dB" 1 "CustzEqlzrBand1Dsp_1_11dB" 2 "CustzEqlzrBand1Dsp_2_10dB" 3 "CustzEqlzrBand1Dsp_3_9dB" 4 "CustzEqlzrBand1Dsp_4_8dB" 5 "CustzEqlzrBand1Dsp_5_7dB" 6 "CustzEqlzrBand1Dsp_6_6dB" 7 "CustzEqlzrBand1Dsp_7_5dB" 8 "CustzEqlzrBand1Dsp_8_4dB" 9 "CustzEqlzrBand1Dsp_9_3dB" 10 "CustzEqlzrBand1Dsp_A_2dB" 11 "CustzEqlzrBand1Dsp_B_1dB" 12 "CustzEqlzrBand1Dsp_C_0dB" 13 "CustzEqlzrBand1Dsp_D_1dB" 14 "CustzEqlzrBand1Dsp_E_2dB" 15 "CustzEqlzrBand1Dsp_F_3dB" 16 "CustzEqlzrBand1Dsp_10_4dB" 17 "CustzEqlzrBand1Dsp_11_5dB" 18 "CustzEqlzrBand1Dsp_12_6dB" 19 "CustzEqlzrBand1Dsp_13_7dB" 20 "CustzEqlzrBand1Dsp_14_8dB" 21 "CustzEqlzrBand1Dsp_15_9dB" 22 "CustzEqlzrBand1Dsp_16_10dB" 23 "CustzEqlzrBand1Dsp_17_11dB" 24 "CustzEqlzrBand1Dsp_18_12dB" ;
VAL_ 748 CustzEqlzrBand13 0 "CustzEqlzrBand1Dsp_0_12dB" 1 "CustzEqlzrBand1Dsp_1_11dB" 2 "CustzEqlzrBand1Dsp_2_10dB" 3 "CustzEqlzrBand1Dsp_3_9dB" 4 "CustzEqlzrBand1Dsp_4_8dB" 5 "CustzEqlzrBand1Dsp_5_7dB" 6 "CustzEqlzrBand1Dsp_6_6dB" 7 "CustzEqlzrBand1Dsp_7_5dB" 8 "CustzEqlzrBand1Dsp_8_4dB" 9 "CustzEqlzrBand1Dsp_9_3dB" 10 "CustzEqlzrBand1Dsp_A_2dB" 11 "CustzEqlzrBand1Dsp_B_1dB" 12 "CustzEqlzrBand1Dsp_C_0dB" 13 "CustzEqlzrBand1Dsp_D_1dB" 14 "CustzEqlzrBand1Dsp_E_2dB" 15 "CustzEqlzrBand1Dsp_F_3dB" 16 "CustzEqlzrBand1Dsp_10_4dB" 17 "CustzEqlzrBand1Dsp_11_5dB" 18 "CustzEqlzrBand1Dsp_12_6dB" 19 "CustzEqlzrBand1Dsp_13_7dB" 20 "CustzEqlzrBand1Dsp_14_8dB" 21 "CustzEqlzrBand1Dsp_15_9dB" 22 "CustzEqlzrBand1Dsp_16_10dB" 23 "CustzEqlzrBand1Dsp_17_11dB" 24 "CustzEqlzrBand1Dsp_18_12dB" ;
VAL_ 748 CustzEqlzrBand14 0 "CustzEqlzrBand1Dsp_0_12dB" 1 "CustzEqlzrBand1Dsp_1_11dB" 2 "CustzEqlzrBand1Dsp_2_10dB" 3 "CustzEqlzrBand1Dsp_3_9dB" 4 "CustzEqlzrBand1Dsp_4_8dB" 5 "CustzEqlzrBand1Dsp_5_7dB" 6 "CustzEqlzrBand1Dsp_6_6dB" 7 "CustzEqlzrBand1Dsp_7_5dB" 8 "CustzEqlzrBand1Dsp_8_4dB" 9 "CustzEqlzrBand1Dsp_9_3dB" 10 "CustzEqlzrBand1Dsp_A_2dB" 11 "CustzEqlzrBand1Dsp_B_1dB" 12 "CustzEqlzrBand1Dsp_C_0dB" 13 "CustzEqlzrBand1Dsp_D_1dB" 14 "CustzEqlzrBand1Dsp_E_2dB" 15 "CustzEqlzrBand1Dsp_F_3dB" 16 "CustzEqlzrBand1Dsp_10_4dB" 17 "CustzEqlzrBand1Dsp_11_5dB" 18 "CustzEqlzrBand1Dsp_12_6dB" 19 "CustzEqlzrBand1Dsp_13_7dB" 20 "CustzEqlzrBand1Dsp_14_8dB" 21 "CustzEqlzrBand1Dsp_15_9dB" 22 "CustzEqlzrBand1Dsp_16_10dB" 23 "CustzEqlzrBand1Dsp_17_11dB" 24 "CustzEqlzrBand1Dsp_18_12dB" ;
VAL_ 748 CustzEqlzrBand15 0 "CustzEqlzrBand1Dsp_0_12dB" 1 "CustzEqlzrBand1Dsp_1_11dB" 2 "CustzEqlzrBand1Dsp_2_10dB" 3 "CustzEqlzrBand1Dsp_3_9dB" 4 "CustzEqlzrBand1Dsp_4_8dB" 5 "CustzEqlzrBand1Dsp_5_7dB" 6 "CustzEqlzrBand1Dsp_6_6dB" 7 "CustzEqlzrBand1Dsp_7_5dB" 8 "CustzEqlzrBand1Dsp_8_4dB" 9 "CustzEqlzrBand1Dsp_9_3dB" 10 "CustzEqlzrBand1Dsp_A_2dB" 11 "CustzEqlzrBand1Dsp_B_1dB" 12 "CustzEqlzrBand1Dsp_C_0dB" 13 "CustzEqlzrBand1Dsp_D_1dB" 14 "CustzEqlzrBand1Dsp_E_2dB" 15 "CustzEqlzrBand1Dsp_F_3dB" 16 "CustzEqlzrBand1Dsp_10_4dB" 17 "CustzEqlzrBand1Dsp_11_5dB" 18 "CustzEqlzrBand1Dsp_12_6dB" 19 "CustzEqlzrBand1Dsp_13_7dB" 20 "CustzEqlzrBand1Dsp_14_8dB" 21 "CustzEqlzrBand1Dsp_15_9dB" 22 "CustzEqlzrBand1Dsp_16_10dB" 23 "CustzEqlzrBand1Dsp_17_11dB" 24 "CustzEqlzrBand1Dsp_18_12dB" ;
VAL_ 748 CustzEqlzrBand16 0 "CustzEqlzrBand1Dsp_0_12dB" 1 "CustzEqlzrBand1Dsp_1_11dB" 2 "CustzEqlzrBand1Dsp_2_10dB" 3 "CustzEqlzrBand1Dsp_3_9dB" 4 "CustzEqlzrBand1Dsp_4_8dB" 5 "CustzEqlzrBand1Dsp_5_7dB" 6 "CustzEqlzrBand1Dsp_6_6dB" 7 "CustzEqlzrBand1Dsp_7_5dB" 8 "CustzEqlzrBand1Dsp_8_4dB" 9 "CustzEqlzrBand1Dsp_9_3dB" 10 "CustzEqlzrBand1Dsp_A_2dB" 11 "CustzEqlzrBand1Dsp_B_1dB" 12 "CustzEqlzrBand1Dsp_C_0dB" 13 "CustzEqlzrBand1Dsp_D_1dB" 14 "CustzEqlzrBand1Dsp_E_2dB" 15 "CustzEqlzrBand1Dsp_F_3dB" 16 "CustzEqlzrBand1Dsp_10_4dB" 17 "CustzEqlzrBand1Dsp_11_5dB" 18 "CustzEqlzrBand1Dsp_12_6dB" 19 "CustzEqlzrBand1Dsp_13_7dB" 20 "CustzEqlzrBand1Dsp_14_8dB" 21 "CustzEqlzrBand1Dsp_15_9dB" 22 "CustzEqlzrBand1Dsp_16_10dB" 23 "CustzEqlzrBand1Dsp_17_11dB" 24 "CustzEqlzrBand1Dsp_18_12dB" ;
VAL_ 753 PassngrCbnLckSts 0 "Unlock" 1 "Lock" 2 "Driver Door Unlock Only" 3 "Invalid" ;
VAL_ 753 LckSts_DR 0 "Unlock" 1 "Lock" ;
VAL_ 753 LckSts_Mid 0 "Unlock" 1 "Lock" ;
VAL_ 753 DrAjr_Mid 1 "Open" 0 "Close" ;
VAL_ 753 DrAjr_MidV 0 "Invalid" 1 "Valid" ;
VAL_ 753 DrAjr_DR 0 "Inactive（Door Close）" 1 "Active（Door Open）" ;
VAL_ 753 DrAjr_DRV 0 "Invalid" 1 "Valid" ;
VAL_ 753 DrAjr_PR 0 "Inactive（Door Close）" 1 "Active（Door Open）" ;
VAL_ 753 DrAjr_PRV 0 "Invalid" 1 "Valid" ;
VAL_ 753 WdwDRPos 127 "Position Unknown" ;
VAL_ 753 WdwPRPos 127 "Position Unknown" ;
VAL_ 753 ECDrSts 0 "Closed" 1 "Open" 2 "Moving" ;
VAL_ 753 ECDCtrlReqDisable 0 "False" 1 "True" ;
VAL_ 754 DrAjr_RL 1 "Open" 0 "Close" ;
VAL_ 754 DrAjr_RLV 0 "Invalid" 1 "Valid" ;
VAL_ 754 DrAjr_RR 1 "Open" 0 "Close" ;
VAL_ 754 DrAjr_RRV 0 "Invalid" 1 "Valid" ;
VAL_ 754 WdwRLPos 127 "Position Unknown" ;
VAL_ 754 WdwRRPos 127 "Position Unknown" ;
VAL_ 754 PwrPdlModuSts_RL 0 "Fully Retraction" 1 "Stretching" 2 "Fully Stretched" 3 "Retracting" 4 "Learning" 5 "PPM_Stop" 6 "Reserved" 7 "Invalid" ;
VAL_ 754 PwrPdlModuSts_RR 0 "Fully Retraction" 1 "Stretching" 2 "Fully Stretched" 3 "Retracting" 4 "Learning" 5 "PPM_Stop" 6 "Reserved" 7 "Invalid" ;
VAL_ 754 HVFuelSts 0 "Lock" 1 "UnLock" 2 "Reserved" ;
VAL_ 754 Ajr_HVFulBxV 0 "Valid" 1 "Invaild" ;
VAL_ 754 Ajr_HVFulBx 0 "FuelDoorClosed" 1 "FuelDoorOpen" 2 "Indeterminate" ;
VAL_ 754 ChldLckSts_RR 0 "Unlock" 1 "Lock" ;
VAL_ 754 ChldLckSts_RL 0 "Unlock" 1 "Lock" ;
VAL_ 754 FuelSysEPTRdyOvrdInvsn 0 "NotReady Request" 1 "No Override Request" ;
VAL_ 754 FuelSysEPTRdyOvrd 0 "No Override" 1 "NotReady" ;
VAL_ 754 DrAjr_CRP 1 "Open" 0 "Close" ;
VAL_ 754 DrAjr_CRPV 0 "Invalid" 1 "Valid" ;
VAL_ 754 ECDErrResp 0 "No error " 1 "Blockage Fault " 2 "Hall AntPinch " 3 "Reserved" ;
VAL_ 767 PADispInfo_1 0 "No request" 1 "Route learning succeeded" 2 "System fault, parking function exits" 3 "The parking function exits if the door or front and rear covers are not closed" 4 "Abnormal tire pressure, parking function exits" 5 "If the slope exceeds the limit, the parking function will exit" 6 "Abnormal environment, parking function exits" 7 "The speed is too fast, and the parking function exits" 8 "The route does not support learning, and the parking function exits" 9 "The learning mileage has exceeded, and the parking function exits" 10 "Timeout, parking function exits" 11 "The parking function exits when the vehicle is stationary for a long time" 12 "Parking function exit" 13 "The steering wheel has been turned and the parking function exits" 14 "The accelerator has been pressed, and the parking function exits" 15 "EPB has been pulled up and parking function exits" 16 "The gear has been intervened, and the parking function exits" 17 "The parking function exits when the ignition switch is pressed" 18 "Parking space is not detected, parking function exits" 19 "There are obstacles in the driving area, and the parking function exits" 20 "The waiting time is too long, and the parking function exits" 21 "If the vehicle is not on the route, the parking function will exit" 22 "Parking space is too small, parking function exits" 23 "The camera is blocked and the parking function exits" 24 "Route learning failed, parking function exits" 25 "Route learning cancelled" 26 "Route matching is unsuccessful, parking function exits" 27 "The driver's door is open, please close the door" 28 "If the passenger door is open, please close the door" 29 "The left passenger area is open, please close the door" 30 "The right passenger area is open, please close the door" 31 "The front compartment lid is open, please close the door" 32 "The tailgate is open, please close the door" 33 "APA parking aid system fault, parking exit" 34 "APA related actuator failure, parking exit" 35 "ACC / ICC function cannot be activated in parking" 36 "The vehicle speed is too fast and the system exits" 37 "The slope is too steep to use the parking function" 38 "The speed is too fast, please slow down!" 39 "Parking space found, please stop the vehicle" 40 "Please apply the brake and click Start parking" 41 "Please drive forward. I'm looking for a parking space" 42 "If you need to park, please find a parking space and stop the vehicle" 43 "Please click continue to start parking" 44 "Please select the parking direction" 45 "Please release the brake and start parking" 46 "Timeout, park in and exit" 47 "Timeout, park out exit" 48 "Gear intervention, park in and exit" 49 "Gear intervention, park out exit" 50 "Throttle intervention, park in and exit" 51 "Throttle intervention, park out exit" 52 "Steering wheel intervention, park in and exit" 53 "Steering wheel intervention, park out exit" 54 "Electronic handbrake intervention, park in and exit" 55 "Electronic handbrake intervention, parking exit" 56 "The driver's door is opened and parking is suspended" 57 "The driver's door is opened and parking out is suspended" 58 "Parking times exceed the limit, parking in and parking out" 59 "Parking times exceed the limit, parking exit" 60 "The slope of the road is too large, and it is necessary to park in and exit" 61 "The road slope is too large, and the parking exit" 62 "The number of interruptions exceeds the limit, berthing in and exiting" 63 "The number of interruptions exceeds the limit, and the parking exit" 64 "Associated ECU fault, park in and exit" 65 "Associated ECU failure, park out exit" 66 "Parking speed exceeds the limit, parking in and exiting" 67 "Parking speed exceeds the limit, parking exit" 68 "Parking system fault, parking in and parking out" 69 "Parking system failure, parking exit" 70 "Gear cannot be switched normally, park in and exit" 71 "Gear cannot be switched normally, parking out exit" 72 "Driver active exit" 73 "The vehicle cannot move, park in and exit" 74 "The vehicle cannot move, park out and exit" 75 "Obstacle detected, park in pause" 76 "Obstacle detected, parking out pause" 77 "The driver's safety belt is released and parking is suspended" 78 "The driver's safety belt is released and parking out is suspended" 79 "The front passenger door is open and parking is suspended" 80 "The front passenger door is opened and parking is suspended" 81 "Parking space is limited, parking in function exits" 82 "Parking space is limited, parking out function exits" 83 "Please pay attention to the surrounding environment during berthing（Parking in）" 84 "Please pay attention to the surrounding environment during berthing（Parking out）" 85 "Rear right door open, parking pause" 86 "Rear right door open, parking out pause" 87 "Rear left door open, parking pause" 88 "Rear left door open, parking out pause" 89 "The front hatch door is open and berthing is suspended（Parking in）" 90 "The front hatch door is open and berthing is suspended（Parking out）" 91 "Tailgate open, park in pause" 92 "Tailgate open, parking out pause" 93 "To continue parking, click the Continue button" 94 "When parking starts, please release the brake and pay attention to the safety of the surrounding environment" 95 "Berthing completed" 96 "Berthing out completed" 97 "Please release the brake and continue to park" 98 "Please release the brake and continue to park out" 99 "Bluetooth connection failed, unable to park in" 100 "Bluetooth connection failed, unable to park out" 101 "Bluetooth connection interrupted, docking paused, please try to reconnect" 102 "Bluetooth connection interrupted, parking out is suspended, please try to reconnect" 103 "Exit app interface and park in interrupt" 104 "Exit the app interface and exit the interrupt" 105 "Phone access, park in pause" 106 "Telephone access, parking out, pause" 107 "Parking failure" 108 "the driver's door is open and the parking function cannot be turned on" 109 "the front passenger door is open and the parking function cannot be turned on" 110 "the left passenger door is open and the parking function cannot be opened" 111 "the right passenger door is open and the parking function cannot be turned on" 112 "the front compartment lid door is open and the parking function cannot be opened" 113 "tailgate open, unable to open parking function" 114 "APA parking aid system failure, unable to turn on the parking function" 115 "APA related actuator failure, unable to turn on parking function" 116 "ACC / ICA function activated, unable to turn on parking function" 117 "the parking function cannot be turned on when the vehicle speed exceeds 25kph" 118 "the slope is too large to activate the parking function" 119 "Unable to park out in this direction" 120 "Please step on the brake and click the <start passing> button" 121 "Please release the brake and pay attention to the surrounding environment" 122 "System abnormality, the function exits" 123 "The associated system is abnormal, the function exits" 124 "Other intelligent driving functions are activated, the function exits" 125 "System timeout, the function exits" 126 "There are obstacles on the driving path, Narrow pass exits" 127 "The gear is interfered, the function exits" 128 "The accelerator pedal is depressed, the function exits" 129 "The steering wheel has been turned , the function exits" 130 "The driver's safety belt is released, the function exits" 131 "Too many pauses, the function exits" 132 "Gear cannot be switched normally, the function exits" 133 "Driver active exit(Narrow pass)" 134 "Narrow pass has been completed" 135 "Please apply the brake" 136 "Please apply the brake and click Park" 137 "The brake is released too fast, the function exits" ;
VAL_ 767 PADispInfo_2 0 "No request" 1 "please close the door or front and rear covers" 2 "please keep the vehicle stationary" 3 "please open the left and right exterior rearview mirrors" 4 "start route learning" 5 "Please shift into gear d to start route learning" 6 "in route learning, the vehicle speed is less than 10km / h and the total distance is less than 50m" 7 "Please select the route to replace" 8 "display save progress bar + saving route, please wait patiently" 9 "the speed is high, please slow down" 10 "please park and shift into P to end learning" 11 "matching route, please wait" 12 "route matching succeeded, please keep the vehicle stationary" 13 "parking has been started. Please use the mobile app to operate. Do not turn off the engine" 14 "to take over the vehicle, please step on the brake and press the ignition switch" 15 "end point reached" 16 "please close the door and trunk before continuing to use the parking" 17 "Please note that there are obstacles in the driving area" 18 "please release the brake pedal to continue parking" 19 "please press and hold the parking button to start parking" 20 "there is no obstacle ahead, please pull out by yourself" 21 "this function can only be used after starting the vehicle" 22 "it has been switched to normal mode, please operate the driver" 23 "end learning" 24 "parking has been suspended. To continue, please operate the parking button" 25 "route matching" 26 "route matching, please drive forward slowly for a distance" 27 "route matching is successful, please stop and shift to p gear and pull up the electronic handbrake" 28 "start parking, please pay attention to the surrounding environment of the vehicle" 29 "Parking pause" 30 "Parking continues" 31 "system fault function exit" 32 "Parking completed, doors locked, windows and sunroof closed" 33 "after parking, please pay attention to whether the windows and sunroof are closed" ;
VAL_ 767 ParkingInSetReqFdbck 0 "No Request" 1 "Request Honored" ;
VAL_ 767 ParkingStReqFdbck 0 "No Request" 1 "Request Honored" ;
VAL_ 767 ParkingContinueReqFdbck 0 "No Request" 1 "Request Honored" ;
VAL_ 767 ParkingExitReqFdbck 0 "No Request" 1 "Request Honored" ;
VAL_ 767 ParkingOutSetReqFdbck 0 "No Request" 1 "Request Honored" ;
VAL_ 767 ParkingDragReqFdbck 0 "No Request" 1 "Request Honored" ;
VAL_ 767 ParkingOutDircnReqFdbck 0 "No Request" 1 "Turn Left" 2 "Turn Right" ;
VAL_ 767 ParkingDragSlotTypReqFdbck 0 "No request" 1 "Vertical Parking" 2 "Horizontal Parking" 3 "Diagonal parking" ;
VAL_ 767 TurnAVMReqFdbck 0 "ON" 1 "OFF" ;
VAL_ 767 TrackLineSwReqFdbck 0 "ON" 1 "OFF" ;
VAL_ 767 UnderPerspectiveSwReqFdbck 0 "ON" 1 "OFF" ;
VAL_ 767 NarrowPathReqFdbck 0 "No Request" 1 "Request Honored" ;
VAL_ 769 TrlerAttchSts 0 "TrailerMd OFF " 1 "TrailerMd ON" ;
VAL_ 775 BMSOfbdChrgSpRsn 0 "None" 1 "ChargerSatusAbnormal" 2 "ChargerPortOverTemperature" 3 "ChargingGunNotProperlyPluggedIn" 4 "ChargerVoltageMismatch" ;
VAL_ 775 BMSDsChrgSpRsn 0 "Default" 1 "Reserved" 2 "Discharging system fault" 3 "Not Plug in DisCharge Gun" 4 "Over load" 5 "The discharging gun over temperature" 6 "Electronic Lock Failure" 7 "Others" ;
VAL_ 775 DisChrgngRmnngTimeV 1 "Invalid" 0 "Valid" ;
VAL_ 775 BMSPTCHeatReqDspCmd 0 "Default" 1 "HeatStart" 2 "HeatStop" 3 "Reserved" ;
VAL_ 775 BMSPTCHeatResp 0 "Default" 1 "CommandExecutedSuccessful" 2 "Failed,BatteryPackHeatingSystemFailure" 3 "Failed,NotMeetChargingConditions" 4 "Failed,BatteryPackNotNeedToBeHeated" 5 "Failed,ReachStopTime" 7 "Failed,Others" ;
VAL_ 775 BMSDsChrgCtrlDspCmd 0 "No Request" 1 "start Discharge" 2 "stop Discharge" 3 "Preparing" ;
VAL_ 775 BMSOnRutWarmSwDsp 0 "On" 1 "Off" ;
VAL_ 776 FrtPsngAirbagOnOffReqFdbck 0 "Passange Airbag NO Indication" 1 "Passange Airbag ON Indication" 2 "Passange Airbag OFF Indication" 3 "Passange Airbag ON and OFF Indication Both" ;
VAL_ 776 SBRSetReqFdbck_R 0 "On" 1 "Off" ;
VAL_ 788 BMSChrgSpRsn 0 "No_Fault" 1 "Grid_Supply_Abnormal" 2 "Charging_Connector_Temperature_Abnormal" 3 "Charging_Connection_Abnormal" 4 "Charging_Station_Not_Up_To_Standard" 5 "ForeignMentalObjectIsDetected" 6 "LivingObjectIsDetected" 7 "Wireless_Charging_Station_Fault" 8 "Wireless_Charger_Wifi_Communication_Abnormal" 9 "Charging_Electric_Lock_Failure" 10 "WirelessChargerGroundAssemblyTemperatureTooHigh" 16 "OnboardChargingSystemAbnormal" 17 "OnboardCharger_Abnormal" 18 "Offboard_Charging_System_Abnormal" 19 "Wireless_Charging_System_Abnormal" 20 "Wireless_Charger_Abnormal" 21 "Cell_Temperature_Abnormal" 22 "Charging_Over_Current" 23 "Charging_Over_Voltage" ;
VAL_ 788 BMSChrgOtptCrntReqV 0 "Valid" 1 "Invalid" ;
VAL_ 788 BMSChrgCtrlResp 0 "Default" 1 "CommandExecutedSuccessful" 2 "Failed_Notpluginchargegun" 3 "Failed_Chargerunauthorized" 7 "Failed_Others" ;
VAL_ 788 BMSChrgCtrlDspCmd 0 "NoRequest" 1 "StartCharge" 2 "StopCharge" 3 "Reserved" ;
VAL_ 788 BMSChrgSts 0 "None" 1 "OnboardCharging" 2 "Charge_Done" 3 "Balancing" 4 "Charge_Fault" 5 "Connecting" 6 "Connected_not_Recognized" 7 "Connected_not_Charged" 8 "Charge_Cease" 9 "Charge_Reserved" 10 "Offboard_Charging" 11 "Discharging_Gun_Connecting" 12 "Multiple_Charging" 13 "DisCharging" 14 "DisCharging_cease" 15 "Discharging_Done" 16 "WirlessCharging" ;
VAL_ 794 CCUOnbdChrgrPlugOn 0 "Disconnected" 1 "Connected, Gun is 63A" 2 "Connected, Gun is 32A" 3 "Connected, Gun is 16A" 4 "Connected, Gun is 10A" 5 "Semi-connected" 6 "Abnormal Connected" 7 "V2L Connected" 8 "V2G Connected" 9 "Unknow Connected" ;
VAL_ 794 CCUDsChrgVolDsp 0 "230V" 1 "110V" ;
VAL_ 794 CCUDsChrgFreqDsp 0 "50Hz" 1 "60Hz" ;
VAL_ 794 CCUEleccLckCtrlDspCmd 0 "NoRequest" 1 "Locked" 2 "Unlock" 3 "Reserved" ;
VAL_ 794 OnBdChrgrCtrlPilotPWMSts 0 "Cp9v" 1 "Cp0v" 2 "Cp9vPwm" 3 "Cp6v" 4 "Cp6vPwm" 5 "Cp12v" 6 "Cp12vPwm" 7 "CpBMSOfRange" ;
VAL_ 800 MemFdbk_PR 0 "No Process" 1 "Success" 2 "Failure" 3 "Reserved" ;
VAL_ 800 MemClrFdbk_PR 0 "No Process" 1 "Success" 2 "Failure" 3 "Reserved" ;
VAL_ 803 EngCltTmpV 0 "Invalid" 1 "valid" ;
VAL_ 803 SpStButtonSts 0 "Enable" 1 "Disable" ;
VAL_ 811 FOTAModReq 0 "No Request" 1 "ON" 2 "OFF" 3 "Reserved" ;
VAL_ 813 EmgcCallTrigd_TBOX 0 "no E-call" 1 "E-call in progress" ;
VAL_ 813 CldDiagGPSPermsnSwSts 0 "Invalid" 1 "Disable（关闭）" 2 "Single Enable（单次）" 3 "7Days Enable （7天）" 4 "1Month Enable（30天）" 5 "3Months Enable（90天）" 6 "6Months Enable （180天）" 7 "1year Enable （365天）" 8 "3years Enable" 9 "Reserved" 10 "Reserved" 11 "Reserved" 12 "Reserved" 13 "Reserved" 14 "Reserved" 15 "Reserved" ;
VAL_ 813 VehPosPermsnSwSts 0 "Invalid" 1 "Disable（关闭）" 2 "Single Enable（单次）" 3 "7Days Enable （7天）" 4 "1Month Enable（30天）" 5 "3Months Enable（90天）" 6 "6Months Enable （180天）" 7 "1year Enable （365天）" 8 "3years Enable" 9 "Reserved" 10 "Reserved" 11 "Reserved" 12 "Resrved" 13 "Reserved" 14 "Reserved" 15 "Reserved" ;
VAL_ 813 PrvyPlyVrsnV 0 "Invalid" 1 "Valid" ;
VAL_ 814 iCGMFctryDeftSetFnsh 0 "No Request" 1 "Successed" 2 "Failed" 3 "Reserved" ;
VAL_ 814 DrvMdRcmdnFnSetReqFdbck 0 "Function ON" 1 "Function OFF" ;
VAL_ 814 DrvMdRcmdnDispReq 0 "No Request" 1 "Request" ;
VAL_ 817 FrtWprOprtSts 0 "Off" 1 "Slow Mode" 2 "Fast Mode" 3 "Auto Mode" 4 "Intermittent Mode" ;
VAL_ 817 WprSnstvtySts 0 "Position 1(low)" 1 "Position 2" 2 "Position 3" 3 "Position 4" 4 "Position 5(high)" ;
VAL_ 817 FrtWprSw 0 "Unknown" 1 "Off" 2 "Auto" 3 "Slow" 4 "Fast" 5 "Immediate / Wash" 6 "Error" 7 "Intermittent" ;
VAL_ 817 RrWprOprtSts 0 "Off" 1 "Slow Mode" 2 "Reserved" 3 "Reserved" ;
VAL_ 817 RvsGearActvtRrWprSts 0 "Off" 1 "On" ;
VAL_ 818 HiBmSts_L 0 "Off" 1 "On" ;
VAL_ 818 HiBmSts_R 0 "Off" 1 "On" ;
VAL_ 818 FrtFogLmpSts 0 "Off" 1 "On" ;
VAL_ 818 LoBmSts_L 0 "Off" 1 "On" ;
VAL_ 818 LoBmSts_R 0 "Off" 1 "On" ;
VAL_ 818 RrFogLmpSts 0 "Off" 1 "On" ;
VAL_ 818 RrFogLmpDspReq 0 "Off" 1 "On" ;
VAL_ 818 FrtFogLmpDspReq 0 "Off" 1 "On" ;
VAL_ 818 ChrIndFedbck 0 "Disable" 1 "Enable" ;
VAL_ 818 HdLmpAdjSts 0 "Level 1(Lowest)" 1 "Level 2" 2 "Level 3" 3 "Level 4（Highest）" ;
VAL_ 818 LogoLgtOnPGearSetFedbck 0 "Disable" 1 "Enable" ;
VAL_ 818 BrkLmpSts 0 "Off" 1 "On" ;
VAL_ 818 RvsGr 0 "Not In Reverse Gear" 1 "In Reverse Gear" ;
VAL_ 818 VisionMdSts 0 "ON" 1 "OFF" ;
VAL_ 818 HdLmpOffSwEnbl 0 "Disable" 1 "Enable" ;
VAL_ 819 CTDSts 0 "Disarmed" 1 "Prearm" 2 "Partially Armed" 3 "Fully Armed" 4 "In Alarm" ;
VAL_ 819 VehLckDrvSts 0 "No Action" 1 "Lock" 2 "Unlock" 3 "Reserved" ;
VAL_ 819 HeatFrtWndsldSts 0 "Off" 1 "ON" ;
VAL_ 819 MemCalOtFlRsn 0 "No Process" 1 "Overspeed" 2 "Reserved" 3 "Reserved" ;
VAL_ 819 MemSts_Set1 0 "Invalid" 1 "Valid" ;
VAL_ 819 MemSts_Set2 0 "Invalid" 1 "Valid" ;
VAL_ 819 MemSts_Set3 0 "Invalid" 1 "Valid" ;
VAL_ 820 TrnLmpSw 0 "Unknown" 1 "Off" 2 "Left Lamp" 3 "Right Lamp" 4 "Error" ;
VAL_ 820 TrnLmpSts_L 0 "Off" 1 "On" ;
VAL_ 820 TrnLmpSts_R 0 "Off" 1 "On" ;
VAL_ 820 AprchngLghtSts 0 "Off" 1 "On" ;
VAL_ 820 PosLmpSts_F 0 "Off" 1 "On" ;
VAL_ 820 PosLmpSts_R 0 "Off" 1 "On" ;
VAL_ 820 DRLSts_L 0 "Off" 1 "On" 2 "Error(Reserved)" ;
VAL_ 820 DRLSts_R 0 "Off" 1 "On" 2 "Error(Reserved)" ;
VAL_ 820 HdLmpOprtSts 0 "OFF" 1 "POSITION LAMP" 2 "LOW BEAM" 3 "AUTO LAMP" ;
VAL_ 820 FogLmpOprtSts 0 "OFF" 1 "Rear Lamp" 2 "Reserved" 3 "Reserved" ;
VAL_ 820 FrtFogLmpOprtSts 0 "OFF" 1 "Front Lamp" 2 "Reserved" 3 "Reserved" ;
VAL_ 820 PckLgtOprtSts 0 "Auto" 1 "Off" 2 "On" 3 "Reserved" ;
VAL_ 823 Humidity 255 "Invalid" ;
VAL_ 833 OMSEyeCntrlFdbk 0 "Open" 1 "Close" ;
VAL_ 833 ChldLfWning 0 "No Warning" 1 "Warning" ;
VAL_ 833 HMIMscCntrlSts 0 "Pause" 1 "Music On" ;
VAL_ 833 HMIAudioScSts 0 "FM" 1 "AM" 2 "USB Audio" 3 "BTAudio" 4 "在线音乐" 5 "Carplay音乐" 6 "Reserved" 15 "Reserved" ;
VAL_ 834 CldrMth_Master 12 "December" 11 "November" 10 "October" 9 "September" 8 "August" 7 "July" 6 "June" 5 "May" 4 "April" 3 "March" 2 "February" 1 "January" 0 "Unknown" ;
VAL_ 834 CldV_Master 1 "Valid" 0 "Invalid" ;
VAL_ 834 DayV_Master 1 "Valid" 0 "Invalid" ;
VAL_ 834 ZnCstmSts 0 "Self-definition" 1 "Not Self-definition" ;
VAL_ 834 TmZoneV_Master 1 "Valid" 0 "Invalid" ;
VAL_ 834 TmZone_Master 0 "UTC + 14" 1 "UTC + 13:45" 2 "UTC + 13" 3 "UTC + 12:45" 4 "UTC + 12" 5 "UTC + 11" 6 "UTC + 10:30" 7 "UTC + 10" 8 "UTC + 9:30" 9 "UTC + 9" 10 "UTC + 8:45" 11 "UTC + 8:30" 12 "UTC + 8" 13 "UTC + 7" 14 "UTC + 6:30" 15 "UTC + 6" 16 "UTC + 5:45" 17 "UTC + 5:30" 18 "UTC + 5" 19 "UTC + 4:30" 20 "UTC + 4" 21 "UTC + 3:30" 22 "UTC + 3" 23 "UTC + 2" 24 "UTC + 1" 25 "UTC + 0" 26 "UTC - 1" 27 "UTC - 2" 28 "UTC - 2:30" 29 "UTC - 3" 30 "UTC - 3:30" 31 "UTC - 4" 32 "UTC - 5" 33 "UTC - 6" 34 "UTC - 7" 35 "UTC - 8" 36 "UTC - 9" 37 "UTC - 9:30" 38 "UTC - 10" 39 "UTC - 11" ;
VAL_ 837 SRFOprtSts 0 "Idle" 1 "Move To Open" 2 "Move To Close" ;
VAL_ 837 PSROprtSts 0 "Idle" 1 "Move To Open" 2 "Move To Close" ;
VAL_ 837 SRFRgn 0 "Unknown" 1 "Fully Closed" 2 "Tilting" 3 "Tilt Up" 4 "Slide Open" 5 "Comfort" 6 "slide back region" 7 "Fully Open" 8 "Position not Trusted" ;
VAL_ 837 PSRRgn 0 "Unknown" 1 "Fully Closed" 2 "Tilting" 3 "Tilt Up" 4 "Slide Open" 5 "Comfort" 6 "slide back region" 7 "Fully Open" 8 "Position not Trusted" ;
VAL_ 837 SRFPos 127 "Position Unknown" ;
VAL_ 837 PSRPstn 127 "Position Unknown" ;
VAL_ 837 PSSDPos 127 "Position Unknown" ;
VAL_ 837 PSSDOprtSts 0 "Idle" 1 "Move To Open" 2 "Move To Close" ;
VAL_ 837 PSSDRgn 0 "Unkonw" 1 "Fully Closed" 2 "Between Fully Closed and Half" 3 "Half" 4 "Between Half and Fully Open" 5 "Fully Open" 6 "Position not Trusted" ;
VAL_ 838 VehSoundGenerateFeedback 0 "Tone1" 1 "Tone2" 2 "Tone3" 3 "Reserved" 5 "Reserved" 6 "Reserved" 7 "Reserved" ;
VAL_ 838 AVASSts 0 "AVAS ON" 1 "AVAS OFF" ;
VAL_ 846 IntLgtOprtMd 0 "AUTO" 1 "OFF/NonAuto（65）" 2 "ON" 3 "Reserved" ;
VAL_ 846 IntWlcmLampSetFedbck 0 "Disable" 1 "Enable" ;
VAL_ 846 RfLmp5Stts 0 "On" 1 "Off" ;
VAL_ 846 RfLmp6Stts 0 "On" 1 "Off" ;
VAL_ 846 ALCRunMdSts 0 "Always on" 1 "Blinking" 2 "Breathing" 3 "Reserved" ;
VAL_ 846 BkltLumTrgt 0 "Default" 1 "5%" 2 "10%" 20 "100%" ;
VAL_ 846 BkltLum 0 "Off" 1 "1%" 2 "2%" 100 "100%" ;
VAL_ 846 BkltSts 0 "Off" 1 "On" ;
VAL_ 846 RfLmp1Stts 0 "On" 1 "Off" ;
VAL_ 846 RfLmp2Stts 0 "On" 1 "Off" ;
VAL_ 846 RfLmp3Stts 0 "On" 1 "Off" ;
VAL_ 846 RfLmp4Stts 0 "On" 1 "Off" ;
VAL_ 846 ALCColLvlSts 255 "Invalid" ;
VAL_ 846 ALCLumLvlSts 127 "Invalid" ;
VAL_ 846 ALCSts 0 "On" 1 "Off" 2 "Auto" 3 "Default" ;
VAL_ 846 ALDrFdbkSts 0 "On" 1 "Off" ;
VAL_ 846 ALCallRmdSts 0 "On" 1 "Off" ;
VAL_ 846 ALStartFdbkSts 0 "On" 1 "Off" ;
VAL_ 846 ALRhythmSts 0 "On" 1 "Off" ;
VAL_ 848 StSysCstmSetFdbk 0 "Unsetted" 1 "Setted" ;
VAL_ 848 StSysLnkgSts_Dwdlr_R 0 "Idle" 1 "In Progress" 2 "Failed" 3 "Completed" ;
VAL_ 848 StSysSftyAlrm 0 "No Request" 1 "Alarm On" ;
VAL_ 848 StSysLnkgSts_Thrn 0 "Idle" 1 "In Progress" 2 "Failed" 3 "Completed" ;
VAL_ 848 StSysLnkgSts_Dwdlr_L 0 "Idle" 1 "In Progress" 2 "Failed" 3 "Completed" ;
VAL_ 848 StSysLnkgSts_FstCls 0 "Idle" 1 "In Progress" 2 "Failed" 3 "Completed" ;
VAL_ 848 StSysLnkgSts_Strg 0 "Idle" 1 "In Progress" 2 "Failed" 3 "Completed" ;
VAL_ 848 StSysLnkgSts_Bbs 0 "Idle" 1 "In Progress" 2 "Failed" 3 "Completed" ;
VAL_ 848 StSysLnkgSts_Cstm 0 "Idle" 1 "In Progress" 2 "Failed" 3 "Completed" ;
VAL_ 848 StSysLnkgEnbl_Thrn 0 "Enable" 1 "Disable" ;
VAL_ 848 StSysLnkgEnbl_Dwdlr_L 0 "Enable" 1 "Disable" ;
VAL_ 848 StSysLnkgEnbl_FstCls 0 "Enable" 1 "Disable" ;
VAL_ 848 StSysLnkgEnbl_Strg 0 "Enable" 1 "Disable" ;
VAL_ 848 StSysLnkgEnbl_Bbs 0 "Enable" 1 "Disable" ;
VAL_ 848 StSysLnkgEnbl_Cstm 0 "Enable" 1 "Disable" ;
VAL_ 848 StSysLnkgSts_Rset 0 "Idle" 1 "In Progress" 2 "Failed" 3 "Completed" ;
VAL_ 848 StSysLnkgOprtSts 0 "Default（不在任一模式）" 1 "Throne Mode（王座模式）" 2 "Dawdler Mode_R（右懒人模式）" 3 "First Class Mode（二排头等舱模式）" 4 "Storage Mode（空间模式）" 5 "Babies Mode（二胎模式）" 6 "Custom Mode（自定义模式）" 7 "ReSet Mode （复位模式）" 8 "Dawdler Mode_L（左懒人模式）" 9 "Reserved" 10 "Reserved" 11 "Reserved" 12 "Reserved" 13 "Reserved" 14 "Reserved" 15 "Reserved" ;
VAL_ 848 MemCalOtExctSts_DR 0 "Idle" 1 "In Progress" 2 "Failed" 3 "Completed" ;
VAL_ 848 IntltWlcmSts 0 "Idle" 1 "In Progress" 2 "Failed" 3 "Completed" ;
VAL_ 848 LockVehRcvrSts 0 "Idle" 1 "In Progress" 2 "Failed" 3 "Completed" ;
VAL_ 848 StSysLnkgEnbl_Dwdlr_R 0 "Enable" 1 "Disable" ;
VAL_ 849 StSysLnkgReq_HMI 0 "No Request" 1 "Throne Mode（王座模式）" 2 "Dawdler Mode_R（右懒人模式）" 3 "First Class Mode（二排头等舱模式）" 4 "Storage Mode（空间模式）" 5 "Babies Mode（二胎模式）" 6 "Reset Seat（复位非主驾座椅）" 7 "Dawdler Mode_L（左懒人模式）" 8 "Reserved" 9 "Reserved" 10 "Reserved" 11 "Reserved" 12 "Reserved" 13 "Reserved" 14 "Reserved" 15 "Reserved" ;
VAL_ 849 StSysCstmReq_HMI 0 "No Request" 1 "Set" 2 "Call Out" 3 "Reserved" ;
VAL_ 851 TrOilTempV 0 "Invalid" 1 "Valid" ;
VAL_ 851 TrOilTemp 255 "Invalid" ;
VAL_ 851 TrOilTempHighTrqLimInd 1 "TRUE" 0 "FALSE" ;
VAL_ 863 MrrFldSts 0 "Fold" 1 "UnFold" 2 "Illegal（Reserved）" ;
VAL_ 864 BarPrsAbsV 0 "Invalid" 1 "Valid" ;
VAL_ 890 StHtEnbl 0 "Disable" 1 "Enable" ;
VAL_ 897 TlgtOprt 0 "Status Unkown" 1 "Opening" 2 "Closing" 3 "Hold" ;
VAL_ 897 TlgtPosSts 0 "Status Unkown" 1 "Open" 2 "HalfLocked" 3 "FullyClosed" ;
VAL_ 897 TlgtPos 127 "Position Unknown" ;
VAL_ 897 TlgtOprtMd 0 "Manual（手动模式，仅支持解锁）" 1 "Park（车库模式）" 2 "Norm（正常/全开模式）" 3 "Selflearning Unfinished (未完成自学习)" ;
VAL_ 897 TlgtAbsAlrm 0 "No Request" 1 "In Abuse Mode 1" 2 "In Abuse Mode 2" 3 "In Abuse Mode 3" ;
VAL_ 897 TlgtOpnPos 127 "Default" ;
VAL_ 898 SmrtWlcmVcReq 0 "No Request" 1 "Request" ;
VAL_ 898 SmrtFrwllVcReq 0 "No Request" 1 "Request" ;
VAL_ 900 AVASPauseFuncReq 0 "No Request" 1 "AVAS Pause" 2 "AVAS Continue" 3 "Reserved" ;
VAL_ 900 VehSoundGenerateReq 0 "No Request" 1 "Tone1" 2 "Tone2" 3 "Tone3" 4 "Reserved" 5 "Reserved" 6 "Reserved" 7 "Reserved" ;
VAL_ 900 FxdMdSetReq 0 "NoRequest" 1 "ModeON" 2 "ModeOFF" 3 "Reserved" ;
VAL_ 900 AirSuspensionHeightReq 0 "NoRequest" 1 "Higher" 2 "High" 3 "Standard" 4 "Low" 5 "Lower" 6 "Reserved" 7 "Reserved" ;
VAL_ 900 HLCMainSwSetReq 0 "No Request" 1 "HLC OFF" 2 "HLC ON" 3 "Reserved" ;
VAL_ 900 ECDCtrlReq_HMI 0 "No request " 1 "Open " 2 "Close" ;
VAL_ 900 DcrtvLmpSwReq 0 "No request" 1 "OFF" 2 "ON" ;
VAL_ 904 LeavVentStsReq_HMI 0 "No request" 1 "On" 2 "Off" 3 "Reserved" ;
VAL_ 904 HVACBloLimtSetReq_HMI 0 "No request" 1 "7档" 2 "6档" 3 "5档" 4 "4档" 5 "3档" 6 "2档" 7 "OFF" ;
VAL_ 904 OtsdAirPrtclMtrCDC_HMI 255 "error" 254 "reserved" 253 "Invalid" 252 "reminder on" 251 "reminder off" ;
VAL_ 904 OtsAirHumidity_HMI 255 "Invalid" ;
VAL_ 904 TrafficCongestionSts_HMI 0 "非常通畅" 1 "通畅" 2 "轻微拥堵" 3 "中度拥堵" 4 "严重拥堵" ;
VAL_ 904 HVACAtDefReq_HMI 0 "No request" 1 "On" 2 "Off" 3 "Reserved" ;
VAL_ 904 CallInStatus_HMI 0 "No Call" 1 "Call In" 2 "Call Out" 3 "In Communication" 4 "Reserved" 5 "Reserved" 6 "Reserved" 7 "Reserved" ;
VAL_ 904 AmbtTemp_HMI 255 "Invalid" ;
VAL_ 904 HVACQuietSet_HMI 0 "No request" 1 "On" 2 "Off" 3 "Reserved" ;
VAL_ 904 HeatFrtWndsldSwReq 0 "No Request" 1 "Off" 2 "On" ;
VAL_ 904 HVACAtCylTimReq_HMI 0 "No request" 1 "10 min" 2 "20 min" 3 "30 min" 4 "OFF" ;
VAL_ 904 HVACAirFltrReset_HMI 0 "No request" 1 "Request" ;
VAL_ 904 RCPSWEnblSet 0 "No Request" 1 "Enable" 2 "Disable" ;
VAL_ 909 StTrgtSlc_HMI 0 "No Request" 1 "Seat_DR" 2 "Seat_PR" 3 "Seat_RL" 4 "Seat_RR" 5 "Seat_3rdL" 6 "Seat_3rdR" ;
VAL_ 909 StTrkPosReq_HMI 0 "0%" 1 "5%" 2 "10%" 3 "15%" 19 "95%" 20 "100%" 31 "No Request" ;
VAL_ 909 StRtaPosReq_HMI 0 "0%" 1 "5%" 2 "10%" 3 "15%" 19 "95%" 20 "100%" 31 "No Request" ;
VAL_ 909 StPhaPosReq_HMI 0 "0%" 1 "5%" 2 "10%" 3 "15%" 19 "95%" 20 "100%" 31 "No Request" ;
VAL_ 909 StTiltPosReq_HMI 0 "0%" 1 "5%" 2 "10%" 3 "15%" 19 "95%" 20 "100%" 31 "No Request" ;
VAL_ 909 StSldPosReq_HMI 0 "0%" 1 "5%" 2 "10%" 3 "15%" 19 "95%" 20 "100%" 31 "No Request" ;
VAL_ 909 StLgLgthPosReq_HMI 0 "0%" 1 "5%" 2 "10%" 3 "15%" 19 "95%" 20 "100%" 31 "No Request" ;
VAL_ 909 StLgRtaPosReq_HMI 0 "0%" 1 "5%" 2 "10%" 3 "15%" 19 "95%" 20 "100%" 31 "No Request" ;
VAL_ 909 StHdrstPosReq_HMI 0 "0%" 1 "5%" 20 "100%" 31 "No Request" ;
VAL_ 911 RlxMdSts_Lf 0 "Not Relax Mode" 1 "Moving" 2 "Relax Mode" ;
VAL_ 911 SlpMdSts_Lf 0 "Not Sleep Mode " 1 "Moving " 2 "Sleep Mode" ;
VAL_ 911 WkMdSts_Lf 0 "Not Working Mode" 1 "Moving" 2 "Working Mode" ;
VAL_ 911 WmMdSts_Lf 0 "Not Warming Mode " 1 "Moving" 2 "Warming Mode " ;
VAL_ 911 ClMdSts_Lf 0 "Not CoolingMode" 1 "Moving" 2 "CoolingMode" ;
VAL_ 911 SmkMdSts_Lf 0 "Not Smoking Mode " 1 "Moving" 2 "Smoking Mode " ;
VAL_ 911 RlxMdSts_Rt 0 "Not Relax Mode" 1 "Moving" 2 "Relax Mode" ;
VAL_ 911 SlpMdSts_Rt 0 "Not Sleep Mode " 1 "Moving " 2 "Sleep Mode" ;
VAL_ 911 WkMdSts_Rt 0 "Not Working Mode" 1 "Moving" 2 "Working Mode" ;
VAL_ 911 WmMdSts_Rt 0 "Not Warming Mode " 1 "Moving" 2 "Warming Mode " ;
VAL_ 911 ClMdSts_Rt 0 "Not CoolingMode" 1 "Moving" 2 "CoolingMode" ;
VAL_ 911 SmkMdSts_Rt 0 "Not Smoking Mode " 1 "Moving" 2 "Smoking Mode " ;
VAL_ 911 StBOSSVIPSts_L 0 "Not PRBOSS Mode" 1 "Moving" 2 "PRBOSS Mode" ;
VAL_ 911 StBOSSVIPSts_R 0 "Not PRBOSS Mode" 1 "Moving" 2 "PRBOSS Mode" ;
VAL_ 911 OMSCntrlObjt_L 0 "No Request" 1 "Passenger Seat Control Active" 2 "HCM Control Active" 3 "FL Window Control Active（预留）" 4 "FR Window Control Active（预留）" 5 "RL Window Control Active" 6 "RR Window Control Active" 7 "SunRoof Control Active" 8 "Media Control Active" 9 "L Sliding Door Control Active" 10 "R Sliding Door Control Active" 11 "Reserved" 12 "Reserved" 13 "Reserved" 14 "Reserved" 15 "Reserved" ;
VAL_ 911 OMSCntrlObjt_R 0 "No Request" 1 "Passenger Seat Control Active" 2 "HCM Control Active" 3 "FL Window Control Active（预留）" 4 "FR Window Control Active（预留）" 5 "RL Window Control Active" 6 "RR Window Control Active" 7 "SunRoof Control Active" 8 "Media Control Active" 9 "L Sliding Door Control Active" 10 "R Sliding Door Control Active" 11 "Reserved" 12 "Reserved" 13 "Reserved" 14 "Reserved" 15 "Reserved" ;
VAL_ 911 ClMdSts 0 "Not Cooling Mode" 1 "Cooling Mode" ;
VAL_ 911 WmMdSts 0 "Not Warming Mode " 1 "Warming Mode " ;
VAL_ 911 CmfrtMdSts 0 "Not Comfort Mode" 1 "Comfort Mode " ;
VAL_ 911 RlxMdSts 0 "Not Relax Mode " 1 "Relax Mode" ;
VAL_ 911 ZenMdSts 0 "Not zen mode" 1 "Zen Mode" ;
VAL_ 911 MtngMdSts 0 "No meeting mode" 1 "Meeting Mode" ;
VAL_ 911 StdMdSts 0 "Not standard mode" 1 "Standard Mode" ;
VAL_ 916 EPTRgtnLvl 0 "Low" 1 "Standard" 2 "High" 3 "Reserved" ;
VAL_ 916 HybVehSysStsInd 0 "Default" 1 "EV" 2 "HEV" 3 "Reserved" ;
VAL_ 916 IntgltBatEngyManmtDrvModHCUDisp 0 "default" 1 "ElectricityConsumptionFirstMode" 2 "IntelligenceHybridMode" 3 "SOCHold" ;
VAL_ 916 ElecVehSysMd 0 "Default" 1 "Idlecharge" 2 "Smartcharge" 3 "Pureelectricdrivemode" 4 "Pureenginedrivemode" 5 "Seriesdrivemode" 6 "Paralleldrivemode" 7 "ParallelRegenmode" 8 "Series Regen mode" 9 "Pureelectricdrivemode_4WD" 10 "Paralleldrivemode_4WD" 11 "EngineIdlebutnotelectricdrive" 12 "EngineIdleandelectricdrive" 13 "PureelectricRegenmode" 14 "EngineOffbutnotelectricdrive" 15 "Reserved" ;
VAL_ 928 FCM_AEBMainSwReq 0 "No Request" 1 "OFF" 2 "ON" 3 "Reserved" ;
VAL_ 928 LDWReminderReq 0 "No Request" 1 "Only Auditory" 2 "Only Vibration" 3 "Auditory and Vibration" ;
VAL_ 928 LDWAccuracyReq 0 "No Request" 1 "Low" 2 "Standard" 3 "High" ;
VAL_ 928 LKA_LDW_ELKMainSwReq 0 "No Request" 1 "OFF" 2 "ON" 3 "Reserved" ;
VAL_ 928 SLIF_ISAMainSwReq 0 "No Request" 1 "OFF" 2 "ON" 3 "Reserved" ;
VAL_ 928 FCMMainSensitivityReq 0 "No Request" 1 "Low" 2 "Standard" 3 "High" ;
VAL_ 928 ICA_ALCAMainSwReq 0 "No Request" 1 "OFF" 2 "ON" 3 "Reserved" ;
VAL_ 928 DASSoundCtrlSetReq 0 "No Request" 1 "OFF" 2 "ON" 3 "Reserved" ;
VAL_ 928 MAPMainSwReq 0 "No Request" 1 "OFF" 2 "ON" 3 "Reserved" ;
VAL_ 928 BSDMainSwReq 0 "No Request" 1 "OFF" 2 "ON" 3 "Reserved" ;
VAL_ 928 MAPRemindReq 0 "No Request" 1 "Common" 2 "Simple" 3 "Reserved" ;
VAL_ 928 AESMainSwReq 0 "No Request" 1 "OFF" 2 "ON" 3 "Reserved" ;
VAL_ 928 MAPSpdAccuracyReq 0 "No Request" 1 "OFF" 2 "Level1 Sfot" 3 "Level2 Normal " 4 "Level3 Fast " 5 "Reserved" 6 "Reserved" 7 "Reserved" ;
VAL_ 928 MAP_ICA_ACCFunctionSwReq 0 "No Request" 1 "Request" ;
VAL_ 928 ChangeLaneConfirmToMsgBox 0 "No Request" 1 "NO" 2 "YES" 3 "Reserved" ;
VAL_ 928 MAPChngLaneConfirmReq 0 "No Request" 1 "NO" 2 "YES" 3 "Reserved" ;
VAL_ 928 IHCMainSwReq 0 "No Request" 1 "ON" 2 "OFF" 3 "Reserved" ;
VAL_ 928 MAPRcmndConfirmReq 0 "No Request" 1 "NO" 2 "YES" 3 "Reserved" ;
VAL_ 928 MAPRcmndConfirmBeforeETC 0 "No Request" 1 "NO" 2 "YES" 3 "Reserved" ;
VAL_ 928 DASDrvrSetHdwayReq 0 "No Gap set" 1 "distance stage 1" 2 "distance stage 2" 3 "distance stage 3" ;
VAL_ 928 PASoundCtrlSetReq 0 "No Request" 1 "OFF" 2 "ON" 3 "Reserved" ;
VAL_ 928 PASoundCtrlReq 0 "No Request" 1 "Start Parking" 2 "Pause Parking" 3 "Resume Parking" 4 "Exit Parking" 5 "Choose Parking Space1" 6 "Choose Parking Space2" 7 "Choose Parking Space3" 8 "Choose Parking Space4" 9 "Choose Parking Space5" 10 "Choose Parking Space6" 11 "Choose Parking Space7" 12 "Choose Parking Space8" 13 "Choose ParkingSpace9" 14 "Choose Parking Space10" ;
VAL_ 928 DASDrvrSetSpdReq 255 "NO Request" ;
VAL_ 928 SoundCtrlLaneChng 0 "NO Request" 1 "Request left" 2 "Request right" 3 "Cancel" ;
VAL_ 928 SentryMdSensitivityReq 0 "No Request" 1 "Low" 2 "Standard" 3 "High" ;
VAL_ 928 LDWSundWrnngReq 0 "No Request" 1 "Warning OFF" 2 "Warning ON" 3 "Reserved" ;
VAL_ 937 SLIFSundWrnngReq 0 "No Request" 1 "Warning OFF" 2 "Warning ON" 3 "Reserved" ;
VAL_ 937 ELKMainSwReq 0 "No Request" 1 "OFF" 2 "ON" 3 "Reserved" ;
VAL_ 937 SLIFMainSwReq 0 "No Request" 1 "OFF" 2 "ON" 3 "Reserved" ;
VAL_ 937 ISAMainSwReq 0 "No Request" 1 "OFF" 2 "ON" 3 "Reserved" ;
VAL_ 937 LKA_LDWMainSwReq 0 "No Request" 1 "LDW" 2 "LDW+LKA" 3 "OFF" ;
VAL_ 937 BSISMainSwReq 0 "No Request" 1 "OFF" 2 "ON" 3 "Reserved" ;
VAL_ 937 MOISMainSwReq 0 "No Request" 1 "OFF" 2 "ON" 3 "Reserved" ;
VAL_ 937 SpdLimitOffsetSta 0 "Km/h " 1 "mph" 2 "%" ;
VAL_ 937 SpdLimitOffsetValuePlusMinus 0 "+ " 1 "-" ;
VAL_ 937 FCMVibrationCfg 0 "No Vibration Interface" 1 "Vibration Interface" ;
VAL_ 937 FCMReminderReq 0 "No Request" 1 "Only Auditory" 2 "Auditory and Vibration" 3 "Reserve" ;
VAL_ 937 LDWReminderTypeReq 0 "No Request" 1 "off" 2 "Only Auditory" 3 "Only Vibration" 4 "Auditory and Vibration" ;
VAL_ 937 LDWVibrationCfg 0 "No Vibration Interface" 1 "Vibration Interface" ;
VAL_ 937 BSDLCAMainSwReq 0 "No Request" 1 "OFF" 2 "ON" 3 "Reserved" ;
VAL_ 937 RCTAMainSwReq 0 "No Request" 1 "OFF" 2 "ON" 3 "Reserved" ;
VAL_ 937 DOWMainSwReq 0 "No Request" 1 "OFF" 2 "ON" 3 "Reserved" ;
VAL_ 937 RCWMainSwReq 0 "No Request" 1 "OFF" 2 "ON" 3 "Reserved" ;
VAL_ 937 RAEBMainSwReq 0 "No Request" 1 "OFF" 2 "ON" 3 "Reserved" ;
VAL_ 931 FICMALCLumLvlReq 127 "No Request" ;
VAL_ 931 FICMALCColLvlReq 255 "No Request" ;
VAL_ 931 FICMALCSw 0 "No Request" 1 "On" 2 "Off" 3 "Auto" ;
VAL_ 931 ALDrFdbkSw 0 "No Request" 1 "On" 2 "Off" 3 "Reserved" ;
VAL_ 931 ALCallRmdSw 0 "No Request" 1 "On" 2 "Off" 3 "Reserved" ;
VAL_ 931 ALCallRmdReq 0 "No Request" 1 "On" 2 "Off" 3 "Reserved" ;
VAL_ 931 ALStartFdbkSw 0 "No Request" 1 "On" 2 "Off" 3 "Reserved" ;
VAL_ 931 ALRhythmSw 0 "No Request" 1 "On" 2 "Off" 3 "Reserved" ;
VAL_ 931 FICMALCMdReq 0 "No Request" 1 "Always on" 2 "Blinking" 3 "Breathing" ;
VAL_ 931 ALColourRhythmCmd 255 "Invalid" ;
VAL_ 931 ALLumRhythmCmd 127 "Invalid" ;
VAL_ 931 ALVocIntfcSw 0 "No Request" 1 "On" 2 "Off" 3 "Reserved" ;
VAL_ 931 ALVocIntfcReq 0 "No Request" 1 "FL Interface" 2 "FR Interface" 3 "RL Interface" 4 "RR Interface" 5 "Off" ;
VAL_ 931 ALVocWkupReq 0 "No Request" 1 "FL Wakeup" 2 "FR Wakeup" 3 "RL Wakeup" 4 "RR Wakeup" 5 "Off" ;
VAL_ 933 StTrkAdjReq_PR 0 "No Request" 1 "Foreward" 2 "Backward" ;
VAL_ 933 StRtaAdjReq_PR 0 "No Request" 1 "Foreward" 2 "Backward" ;
VAL_ 933 StTrkAdjReq_RL_FICM 0 "No Request" 1 "Foreward" 2 "Backward" ;
VAL_ 933 StRtaAdjReq_RL_FICM 0 "No Request" 1 "Foreward" 2 "Backward" ;
VAL_ 933 StTrkAdjReq_RR_FICM 0 "No Request" 1 "Foreward" 2 "Backward" ;
VAL_ 933 StRtaAdjReq_RR_FICM 0 "No Request" 1 "Foreward" 2 "Backward" ;
VAL_ 933 StTrkAdjReq_3rdL_FICM 0 "No Request" 1 "Foreward" 2 "Backward" ;
VAL_ 933 StTrkAdjReq_3rdR_FICM 0 "No Request" 1 "Foreward" 2 "Backward" ;
VAL_ 933 StHtReq_DR 0 "No Request" 1 "Off" 2 "Low" 3 "Medium" 4 "High" ;
VAL_ 933 StHtReq_PR 0 "No Request" 1 "Off" 2 "Low" 3 "Medium" 4 "High" ;
VAL_ 933 MemReq_PR 0 "No Request" 1 "Set 1" 2 "Set 2" 3 "Set 3" ;
VAL_ 933 StVtReq_DR 0 "No Request" 1 "Off" 2 "Low" 3 "Medium" 4 "High" ;
VAL_ 933 StVtReq_PR 0 "No Request" 1 "Off" 2 "Low" 3 "Medium" 4 "High" ;
VAL_ 933 MemCalOtReq_PR 0 "No Request" 1 "Set 1" 2 "Set 2" 3 "Set 3" ;
VAL_ 933 MemClrReq_PR 0 "No Request" 1 "Clear Set 1" 2 "Clear Set 2" 3 "Clear Set 3" 4 "Clear All" ;
VAL_ 933 StWelcomeSet_DR 0 "No Request" 1 "On" 2 "Off" ;
VAL_ 933 StSysRstReq 0 "No Request" 1 "Seat System Reset Request" ;
VAL_ 933 MemReq_DR 0 "No Request" 1 "Set 1" 2 "Set 2" 3 "Set 3" ;
VAL_ 933 StMsgReq_DR 0 "No Request" 1 "Mode1" 2 "Mode2" 3 "Mode3" 4 "Mode4" 5 "Mode5" 6 "Mode6" 7 "Mode7" 8 "Mode8" 15 "OFF" ;
VAL_ 933 StMsgReq_PR 0 "No Request" 1 "Mode1" 2 "Mode2" 3 "Mode3" 4 "Mode4" 5 "Mode5" 6 "Mode6" 7 "Mode7" 8 "Mode8" 15 "OFF" ;
VAL_ 933 StMsgIntstyReq_DR 0 "No Request" 1 "Level 1" 2 "Level 2" 3 "Level 3" 4 "OFF" ;
VAL_ 933 StMsgIntstyReq_PR 0 "No Request" 1 "Level 1" 2 "Level 2" 3 "Level 3" 4 "OFF" ;
VAL_ 933 MemCalOtReq_DR 0 "No Request" 1 "Set 1" 2 "Set 2" 3 "Set 3" ;
VAL_ 933 MemClrReq_DR 0 "No Request" 1 "Clear Set 1" 2 "Clear Set 2" 3 "Clear Set 3" 4 "Clear All" ;
VAL_ 933 StFRtaReq 0 "Not_Request" 1 "Turn Forward" ;
VAL_ 933 StBRtaReq 0 "Not_Request" 1 "Turn Back" ;
